VERSION "dbc-export 1 2026.26.6.5"

NS_ :

BS_:

BU_: APP BMS CC CMP CMPD CP DAS DI DIF DIR EPBL EPBR EVSE FC GTW HCML HCMR HVP ICR PCS PCS2 PM PMF PMR PTC SCCM SDCR TAS UMC V2G VC VCBATT VCBATT1 VCBATT2 VCFRONT VCFRONT1 VCLEFT VCRIGHT VCSEC

BO_ 994 VCLEFT_lightStatus: 7 VCLEFT
 SG_ VCLEFT_brakeLightStatus : 0|2@1+ (1,0) [0|2] "" Vector__XXX
 SG_ VCLEFT_tailLightStatus : 2|2@1+ (1,0) [0|2] "" Vector__XXX
 SG_ VCLEFT_turnSignalStatus : 4|2@1+ (1,0) [0|2] "" Vector__XXX
 SG_ VCLEFT_FLMapLightStatus : 6|2@1+ (1,0) [0|2] "" Vector__XXX
 SG_ VCLEFT_FRMapLightStatus : 8|2@1+ (1,0) [0|2] "" Vector__XXX
 SG_ VCLEFT_RLMapLightStatus : 10|2@1+ (1,0) [0|2] "" Vector__XXX
 SG_ VCLEFT_RRMapLightStatus : 12|2@1+ (1,0) [0|2] "" Vector__XXX
 SG_ VCLEFT_FLMapLightSwitchPressed : 14|1@1+ (1,0) [0|1] "" Vector__XXX
 SG_ VCLEFT_FRMapLightSwitchPressed : 15|1@1+ (1,0) [0|1] "" Vector__XXX
 SG_ VCLEFT_RLMapLightSwitchPressed : 16|1@1+ (1,0) [0|1] "" Vector__XXX
 SG_ VCLEFT_RRMapLightSwitchPressed : 17|1@1+ (1,0) [0|1] "" Vector__XXX
 SG_ VCLEFT_leftTurnTrailerLightStatu : 18|2@1+ (1,0) [0|2] "" Vector__XXX
 SG_ VCLEFT_rightTrnTrailerLightStatu : 20|2@1+ (1,0) [0|2] "" Vector__XXX
 SG_ VCLEFT_brakeTrailerLightStatus : 22|2@1+ (1,0) [0|2] "" Vector__XXX
 SG_ VCLEFT_tailTrailerLightStatus : 24|2@1+ (1,0) [0|2] "" Vector__XXX
 SG_ VCLEFT_fogTrailerLightStatus : 26|2@1+ (1,0) [0|2] "" Vector__XXX
 SG_ VCLEFT_frontRideHeight : 28|8@1- (1,0) [-127|127] "mm" Vector__XXX
 SG_ VCLEFT_rearRideHeight : 36|8@1- (1,0) [-127|127] "mm" Vector__XXX
 SG_ VCLEFT_trailerDetected : 46|2@1+ (1,0) [1|3] "" Vector__XXX
 SG_ VCLEFT_rideHeightSensorFault : 48|1@1+ (1,0) [0|1] "" Vector__XXX
 SG_ VCLEFT_reverseTrailerLightStatus : 49|2@1+ (1,0) [0|2] "" Vector__XXX
 SG_ VCLEFT_tailLightOutageStatus : 51|1@1+ (1,0) [0|1] "" Vector__XXX
 SG_ VCLEFT_reverseLightStatus : 52|2@1+ (1,0) [0|2] "" Vector__XXX
 SG_ VCLEFT_thirdRowLeftMapLightSwitc : 54|1@1+ (1,0) [0|1] "" Vector__XXX
 SG_ VCLEFT_thirdRowRightMapLightSwit : 55|1@1+ (1,0) [0|1] "" Vector__XXX

BO_ 1802 VCLEFT_logging0point1Hz: 8 VCLEFT
 SG_ VCLEFT_logging0point1HzIndex M : 0|1@1+ (1,0) [0|1] "" Vector__XXX
 SG_ VCLEFT_leftBrakeTailLightCurrent m0 : 2|9@1+ (0.005,0) [0|2.55] "A" Vector__XXX
 SG_ VCLEFT_leftBrakeTailLightCu_0001 m0 : 11|3@1+ (1,0) [1|7] "" Vector__XXX
 SG_ VCLEFT_leftRearTurnLightCurrent m0 : 14|9@1+ (0.002,0) [0|1.02] "A" Vector__XXX
 SG_ VCLEFT_leftRearTurnLightCurrentS m0 : 24|3@1+ (1,0) [1|7] "" Vector__XXX
 SG_ VCLEFT_canAuthResyncDurationMs m0 : 48|16@1+ (1,0) [0|65535] "" Vector__XXX

BO_ 936 VCLEFT_logging1Hz: 8 VCLEFT
 SG_ VCLEFT_logging1HzIndex M : 0|3@1+ (1,0) [0|7] "" Vector__XXX
 SG_ VCLEFT_tohcPCBATemperature m0 : 8|8@1+ (1,-40) [-40|214] "degC" Vector__XXX
 SG_ VCLEFT_phoneChargingFL m0 : 16|1@1+ (1,0) [0|1] "" Vector__XXX
 SG_ VCLEFT_phoneChargingFR m0 : 17|1@1+ (1,0) [0|1] "" Vector__XXX
 SG_ VCLEFT_swcResistance m0 : 24|7@1+ (0.025,0) [0|3.15] "Ohm" Vector__XXX
 SG_ VCLEFT_frontSeatHeatCushionPwr m0 : 32|7@1+ (1,0) [0|127] "W" Vector__XXX
 SG_ VCLEFT_frontSeatHeatBackrestPwr m0 : 40|7@1+ (1,0) [0|127] "W" Vector__XXX
 SG_ VCLEFT_rgbLedIPFLCurrent m3 : 3|10@1+ (0.000488758552819,0) [0|0.499999999534] "A" Vector__XXX
 SG_ VCLEFT_rgbLedIPFRCurrent m3 : 13|10@1+ (0.000488758552819,0) [0|0.499999999534] "A" Vector__XXX
 SG_ VCLEFT_rgbLedIPFLOutput m3 : 23|1@1+ (1,0) [0|1] "" Vector__XXX
 SG_ VCLEFT_rgbLedIPFROutput m3 : 24|1@1+ (1,0) [0|1] "" Vector__XXX
 SG_ VCLEFT_rgbLedFrontCurrent m3 : 25|10@1+ (0.000488758552819,0) [0|0.499999999534] "A" Vector__XXX
 SG_ VCLEFT_rgbLedRearCurrent m3 : 35|10@1+ (0.000488758552819,0) [0|0.499999999534] "A" Vector__XXX
 SG_ VCLEFT_rgbLedFrontOutput m3 : 45|1@1+ (1,0) [0|1] "" Vector__XXX
 SG_ VCLEFT_rgbLedRearOutput m3 : 46|1@1+ (1,0) [0|1] "" Vector__XXX
 SG_ VCLEFT_seat2RControllerCurrent m3 : 55|9@1+ (0.2,0) [0|102] "A" Vector__XXX

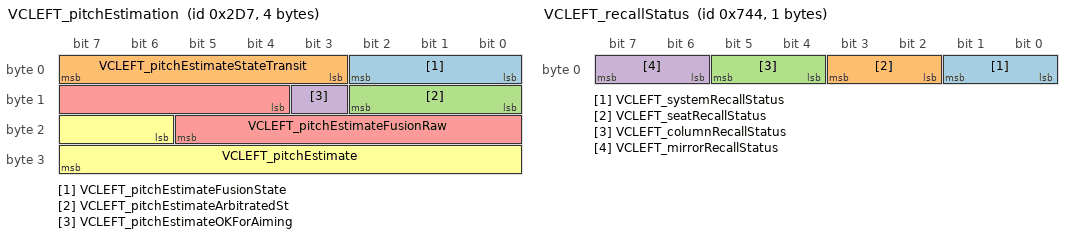
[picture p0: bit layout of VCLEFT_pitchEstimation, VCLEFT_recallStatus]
BO_ 727 VCLEFT_pitchEstimation: 4 VCLEFT
 SG_ VCLEFT_pitchEstimateFusionState : 0|3@1+ (1,0) [0|7] "" Vector__XXX
 SG_ VCLEFT_pitchEstimateStateTransit : 3|5@1+ (1,0) [0|31] "" Vector__XXX
 SG_ VCLEFT_pitchEstimateArbitratedSt : 8|3@1+ (1,0) [0|7] "" Vector__XXX
 SG_ VCLEFT_pitchEstimateOKForAiming : 11|1@1+ (1,0) [0|1] "" Vector__XXX
 SG_ VCLEFT_pitchEstimateFusionRaw : 12|10@1- (0.0002,0) [-0.1024|0.1022] "rad" Vector__XXX
 SG_ VCLEFT_pitchEstimate : 22|10@1- (0.0002,0) [-0.1022|0.1022] "rad" Vector__XXX

BO_ 1860 VCLEFT_recallStatus: 1 VCLEFT
 SG_ VCLEFT_systemRecallStatus : 0|2@1+ (1,0) [1|3] "" Vector__XXX
 SG_ VCLEFT_seatRecallStatus : 2|2@1+ (1,0) [1|3] "" Vector__XXX
 SG_ VCLEFT_columnRecallStatus : 4|2@1+ (1,0) [1|3] "" Vector__XXX
 SG_ VCLEFT_mirrorRecallStatus : 6|2@1+ (1,0) [1|3] "" Vector__XXX

BO_ 1250 VCLEFT_seatStatus: 8 VCLEFT
 SG_ VCLEFT_seatStatusIndex M : 0|3@1+ (1,0) [0|7] "" Vector__XXX
 SG_ VC_AH_1RowLeftSeatMovementHealth m0 : 5|3@1+ (1,0) [0|7] "" Vector__XXX
 SG_ VCLEFT_frontSeatTrackPos m0 : 8|16@1- (1,0) [-32768|32767] "" Vector__XXX
 SG_ VCLEFT_frontSeatTrackCurrent m0 : 24|12@1- (0.01,0) [-20.48|20.47] "A" Vector__XXX
 SG_ VCLEFT_frontSeatTrackDuty m0 : 36|12@1- (0.1,0) [-204.8|204.7] "%" Vector__XXX
 SG_ VCLEFT_frontSeatTrackState m0 : 48|3@1+ (1,0) [0|7] "" Vector__XXX
 SG_ VCLEFT_frontSeatTrackCalibrated m0 : 51|1@1+ (1,0) [0|1] "" Vector__XXX
 SG_ VCLEFT_frontSeatTrackLog m0 : 52|1@1+ (1,0) [0|1] "" Vector__XXX
 SG_ VCLEFT_frontSeatTrackBridgeSt m0 : 53|2@1+ (1,0) [0|3] "" Vector__XXX
 SG_ VCLEFT_frontSeatTrackPercentage m0 : 55|7@1+ (1,0) [0|100] "%" Vector__XXX
 SG_ VCLEFT_frontSeatBackPos m1 : 8|16@1- (1,0) [-32768|32767] "" Vector__XXX
 SG_ VCLEFT_frontSeatBackCurrent m1 : 24|12@1- (0.01,0) [-20.48|20.47] "A" Vector__XXX
 SG_ VCLEFT_frontSeatBackDuty m1 : 36|12@1- (0.1,0) [-204.8|204.7] "%" Vector__XXX
 SG_ VCLEFT_frontSeatBackState m1 : 48|3@1+ (1,0) [0|7] "" Vector__XXX
 SG_ VCLEFT_frontSeatBackCalibrated m1 : 51|1@1+ (1,0) [0|1] "" Vector__XXX
 SG_ VCLEFT_frontSeatBackLog m1 : 52|1@1+ (1,0) [0|1] "" Vector__XXX
 SG_ VCLEFT_frontSeatBackBridgeSt m1 : 53|2@1+ (1,0) [0|3] "" Vector__XXX
 SG_ VCLEFT_frontSeatBackPercentage m1 : 55|7@1+ (1,0) [0|100] "%" Vector__XXX
 SG_ VCLEFT_frontSeatLiftPos m2 : 8|16@1- (1,0) [-32768|32767] "" Vector__XXX
 SG_ VCLEFT_frontSeatLiftCurrent m2 : 24|12@1- (0.01,0) [-20.48|20.47] "A" Vector__XXX
 SG_ VCLEFT_frontSeatLiftDuty m2 : 36|12@1- (0.1,0) [-204.8|204.7] "%" Vector__XXX
 SG_ VCLEFT_frontSeatLiftState m2 : 48|3@1+ (1,0) [0|7] "" Vector__XXX
 SG_ VCLEFT_frontSeatLiftCalibrated m2 : 51|1@1+ (1,0) [0|1] "" Vector__XXX
 SG_ VCLEFT_frontSeatLiftLog m2 : 52|1@1+ (1,0) [0|1] "" Vector__XXX
 SG_ VCLEFT_frontSeatLiftBridgeSt m2 : 53|2@1+ (1,0) [0|3] "" Vector__XXX
 SG_ VCLEFT_frontSeatLiftPercentage m2 : 55|7@1+ (1,0) [0|100] "%" Vector__XXX
 SG_ VCLEFT_frontSeatTiltPos m3 : 8|16@1- (1,0) [-32768|32767] "" Vector__XXX
 SG_ VCLEFT_frontSeatTiltCurrent m3 : 24|12@1- (0.01,0) [-20.48|20.47] "A" Vector__XXX
 SG_ VCLEFT_frontSeatTiltDuty m3 : 36|12@1- (0.1,0) [-204.8|204.7] "%" Vector__XXX
 SG_ VCLEFT_frontSeatTiltState m3 : 48|3@1+ (1,0) [0|7] "" Vector__XXX
 SG_ VCLEFT_frontSeatTiltCalibrated m3 : 51|1@1+ (1,0) [0|1] "" Vector__XXX
 SG_ VCLEFT_frontSeatTiltLog m3 : 52|1@1+ (1,0) [0|1] "" Vector__XXX
 SG_ VCLEFT_frontSeatTiltBridgeSt m3 : 53|2@1+ (1,0) [0|3] "" Vector__XXX
 SG_ VCLEFT_frontSeatTiltPercentage m3 : 55|7@1+ (1,0) [0|100] "%" Vector__XXX
 SG_ VCLEFT_lumbarAState m4 : 3|3@1+ (1,0) [0|7] "" Vector__XXX
 SG_ VCLEFT_lumbarBState m4 : 6|3@1+ (1,0) [0|7] "" Vector__XXX
 SG_ VCLEFT_lumbarAPressureHpa m4 : 9|12@1+ (1,0) [0|4095] "" Vector__XXX
 SG_ VCLEFT_lumbarAPressureHpaFilt m4 : 21|10@1+ (1,0) [0|1023] "" Vector__XXX
 SG_ VCLEFT_lumbarBPressureHpa m4 : 31|12@1+ (1,0) [0|4095] "" Vector__XXX
 SG_ VCLEFT_lumbarBPressureHpaFilt m4 : 43|10@1+ (1,0) [0|1023] "" Vector__XXX
 SG_ VCLEFT_lumbarActiveTooLongErr m4 : 53|1@1+ (1,0) [0|1] "" Vector__XXX
 SG_ VCLEFT_lumbarMaxPErr m4 : 54|1@1+ (1,0) [0|1] "" Vector__XXX
 SG_ VCLEFT_lumbarOvercurrentErr m4 : 55|1@1+ (1,0) [0|1] "" Vector__XXX
 SG_ VCLEFT_lumbarMaxOperatingPErr m4 : 56|1@1+ (1,0) [0|1] "" Vector__XXX
 SG_ VCLEFT_lumbarMinPErr m4 : 57|1@1+ (1,0) [0|1] "" Vector__XXX
 SG_ VCLEFT_lumbarGeneralErr m4 : 58|1@1+ (1,0) [0|1] "" Vector__XXX
 SG_ VCLEFT_lumbarDevMaxPumpPressA m4 : 59|1@1+ (1,0) [0|1] "" Vector__XXX
 SG_ VCLEFT_lumbarDevMaxPumpPressB m4 : 60|1@1+ (1,0) [0|1] "" Vector__XXX
 SG_ VCLEFT_frontSeatTrackPosReal m5 : 3|12@1- (1,0) [-2048|2047] "mm" Vector__XXX
 SG_ VCLEFT_frontSeatBackPosReal m5 : 16|12@1- (0.1,0) [-204.8|204.7] "deg" Vector__XXX
 SG_ VCLEFT_frontSeatLiftPosReal m5 : 28|12@1- (1,0) [-2048|2047] "mm" Vector__XXX
 SG_ VCLEFT_frontSeatTiltPosReal m5 : 40|12@1- (0.1,0) [-204.8|204.7] "deg" Vector__XXX
 SG_ VCLEFT_frontSeatThighSupportPosR m5 : 52|12@1- (1,0) [-2048|2047] "mm" Vector__XXX
 SG_ VCLEFT_frontSeatTrackPosOffset m6 : 3|12@1- (1,0) [-2048|2047] "mm" Vector__XXX
 SG_ VCLEFT_frontSeatBackPosOffset m6 : 16|12@1- (0.1,0) [-204.8|204.7] "deg" Vector__XXX
 SG_ VCLEFT_frontSeatLiftPosOffset m6 : 28|12@1- (1,0) [-2048|2047] "mm" Vector__XXX
 SG_ VCLEFT_frontSeatTiltPosOffset m6 : 40|12@1- (0.1,0) [-204.8|204.7] "deg" Vector__XXX
 SG_ VCLEFT_frontSeatThighSupportPosO m6 : 52|12@1- (1,0) [-2048|2047] "mm" Vector__XXX
 SG_ VCLEFT_lumbarAPressurePercentage m7 : 3|7@1+ (1,0) [0|100] "%" Vector__XXX
 SG_ VCLEFT_lumbarBPressurePercentage m7 : 10|7@1+ (1,0) [0|100] "%" Vector__XXX

BO_ 738 VCLEFT_seatStatus2: 8 VCLEFT
 SG_ VCLEFT_seatStatus2Index M : 0|4@1+ (1,0) [0|15] "" Vector__XXX
 SG_ VCLEFT_frontSeatHeatCurrent m0 : 4|12@1+ (0.01,0) [0|40.95] "A" Vector__XXX
 SG_ VCLEFT_frontSeatHeatDuty m0 : 16|8@1+ (1,0) [0|255] "%" Vector__XXX
 SG_ VCLEFT_frontSeatHeatTmp m0 : 24|12@1- (0.05,0) [-40|80] "degC" Vector__XXX
 SG_ VCLEFT_frontSeatHeatTmpTarget m0 : 36|8@1- (0.5,0) [0|60] "degC" Vector__XXX
 SG_ VCLEFT_frontSeatHeatInhibited m0 : 44|1@1+ (1,0) [0|1] "" Vector__XXX
 SG_ VCLEFT_frontSeatHeatPowered m0 : 45|1@1+ (1,0) [0|1] "" Vector__XXX
 SG_ VCLEFT_2RowSeatFoldLeftSwitch m0 : 46|2@1+ (1,0) [1|3] "" Vector__XXX
 SG_ VCLEFT_2RowSeatUnfoldLeftSwitch m0 : 48|2@1+ (1,0) [1|3] "" Vector__XXX
 SG_ VCLEFT_2RowSeatFoldRightSwitch m0 : 50|2@1+ (1,0) [1|3] "" Vector__XXX
 SG_ VCLEFT_2RowSeatUnfoldRightSwitch m0 : 52|2@1+ (1,0) [1|3] "" Vector__XXX
 SG_ VCLEFT_3RowSeatFoldLeftSwitch m0 : 54|2@1+ (1,0) [1|3] "" Vector__XXX
 SG_ VCLEFT_3RowSeatUnfoldLeftSwitch m0 : 56|2@1+ (1,0) [1|3] "" Vector__XXX
 SG_ VCLEFT_3RowSeatFoldRightSwitch m0 : 58|2@1+ (1,0) [1|3] "" Vector__XXX
 SG_ VCLEFT_3RowSeatUnfoldRightSwitch m0 : 60|2@1+ (1,0) [1|3] "" Vector__XXX
 SG_ VC_AH_1RowLeftSeatHeatVentHealth m0 : 62|2@1+ (1,0) [0|3] "" Vector__XXX
 SG_ VCLEFT_2RowSeatReclineState m11 : 4|4@1+ (1,0) [0|14] "" Vector__XXX
 SG_ VCLEFT_2RowSeatReclineDuty m11 : 8|8@1- (1,0) [-100|100] "%" Vector__XXX
 SG_ VCLEFT_2RowSeatReclineCurrent m11 : 16|12@1- (0.05,0) [-100|100] "A" Vector__XXX
 SG_ VCLEFT_2RowSeatReclineCalibrated m11 : 28|1@1+ (1,0) [0|1] "" Vector__XXX
 SG_ VCLEFT_2RowSeatReclinePositionRa m11 : 29|12@1- (1,0) [-2048|2047] "" Vector__XXX
 SG_ VCLEFT_2RowSeatReclineAngle m11 : 41|12@1- (0.1,0) [-204.8|204.7] "deg" Vector__XXX
 SG_ VCLEFT_2RowSeatReclineAbsPosSwit m11 : 53|2@1+ (1,0) [1|3] "" Vector__XXX
 SG_ VCLEFT_2RowSeatReclinePositionSt m12 : 4|3@1+ (1,0) [0|7] "" Vector__XXX
 SG_ VCLEFT_2RowSeatReclineAdjustment m12 : 7|1@1+ (1,0) [0|1] "" Vector__XXX
 SG_ VCLEFT_2RowSeatReclineFoldAllowe m12 : 8|1@1+ (1,0) [0|1] "" Vector__XXX
 SG_ VCLEFT_2RowSeatReclineUnfoldAllo m12 : 9|1@1+ (1,0) [0|1] "" Vector__XXX
 SG_ VCLEFT_2RowSeatReclineNextToggle m12 : 10|2@1+ (1,0) [0|3] "" Vector__XXX
 SG_ VCLEFT_2RowSeatReclineChoreoBloc m12 : 12|1@1+ (1,0) [0|1] "" Vector__XXX
 SG_ VCLEFT_2RowSeat1RClashAvoidanceB m12 : 13|3@1+ (1,0) [0|7] "" Vector__XXX
 SG_ VCLEFT_2RowSeat1RClashAvoidanceS m12 : 16|2@1+ (1,0) [0|3] "" Vector__XXX
 SG_ VCLEFT_2RowSeatReclineAbsPo_0001 m12 : 18|12@1- (0.1,0) [-204.8|204.7] "deg" Vector__XXX
 SG_ VC_AH_2RowLeftSeatMovementHealth m12 : 61|3@1+ (1,0) [0|7] "" Vector__XXX
 SG_ VCLEFT_3RowSeatReclineState m14 : 4|4@1+ (1,0) [0|14] "" Vector__XXX
 SG_ VCLEFT_3RowSeatReclineDuty m14 : 8|8@1- (1,0) [-100|100] "%" Vector__XXX
 SG_ VCLEFT_3RowSeatReclineCurrent m14 : 16|12@1- (0.05,0) [-100|100] "A" Vector__XXX
 SG_ VCLEFT_3RowSeatReclineCalibrated m14 : 28|1@1+ (1,0) [0|1] "" Vector__XXX
 SG_ VCLEFT_3RowSeatReclinePositionRa m14 : 29|12@1- (1,0) [-2048|2047] "" Vector__XXX
 SG_ VCLEFT_3RowSeatReclineAngle m14 : 41|12@1- (0.1,0) [-204.8|204.7] "deg" Vector__XXX
 SG_ VCLEFT_3RowSeatReclineNextToggle m14 : 53|2@1+ (1,0) [0|3] "" Vector__XXX
 SG_ VCLEFT_3RRightCushionHeatCurrent m15 : 4|12@1+ (0.01,0) [0|40.95] "A" Vector__XXX
 SG_ VCLEFT_3RRightCushionHeatDuty m15 : 16|8@1- (1,0) [-100|100] "%" Vector__XXX
 SG_ VCLEFT_3RRightCushionHeatTmp m15 : 24|12@1- (0.05,0) [-40|80] "degC" Vector__XXX
 SG_ VCLEFT_3RRightCushionHeatTmpTarg m15 : 36|8@1- (0.5,0) [0|60] "degC" Vector__XXX
 SG_ VCLEFT_3RRightCushionHeatInhibit m15 : 44|1@1+ (1,0) [0|1] "" Vector__XXX
 SG_ VCLEFT_3RowSeatReclinePositionSt m15 : 46|3@1+ (1,0) [0|7] "" Vector__XXX
 SG_ VCLEFT_3RowSeatReclineAdjustment m15 : 49|1@1+ (1,0) [0|1] "" Vector__XXX
 SG_ VCLEFT_3RowSeatReclineFoldAllowe m15 : 50|1@1+ (1,0) [0|1] "" Vector__XXX
 SG_ VCLEFT_3RowSeatReclineUnfoldAllo m15 : 51|1@1+ (1,0) [0|1] "" Vector__XXX
 SG_ VCLEFT_3RowSeatReclineChoreoBloc m15 : 52|1@1+ (1,0) [0|1] "" Vector__XXX
 SG_ VCLEFT_3RowSeatReclineAbsPosSwit m15 : 53|2@1+ (1,0) [1|3] "" Vector__XXX

BO_ 930 VCLEFT_status: 8 VCLEFT
 SG_ VCLEFT_statusIndex M : 0|2@1+ (1,0) [0|3] "" Vector__XXX
 SG_ VCLEFT_securityControllerEnable m0 : 5|1@1+ (1,0) [0|1] "" Vector__XXX
 SG_ VCLEFT_securityControllerVoltage m0 : 6|5@1+ (0.625,0) [0|19.375] "V" Vector__XXX
 SG_ VCLEFT_consoleDoorAssist m0 : 11|1@1+ (1,0) [0|1] "" Vector__XXX
 SG_ VCLEFT_OTAState m0 : 12|1@1+ (1,0) [0|1] "" Vector__XXX
 SG_ VCLEFT_5AVoltage m0 : 13|10@1+ (0.005443676,0) [0|5.568880548] "V" Vector__XXX
 SG_ VCLEFT_vbatProt m0 : 23|12@1+ (0.005443676,0) [0|22.29185322] "V" Vector__XXX
 SG_ VCLEFT_footwellLightCurrent m0 : 35|12@1- (0.1,0) [-204.8|204.7] "mA" Vector__XXX
 SG_ VCLEFT_swcInputVoltage m0 : 47|8@1+ (0.1,0) [0|25.4] "V" Vector__XXX
 SG_ VCLEFT_swcPCBATemperature m0 : 55|8@1- (1,68) [-59|195] "degC" Vector__XXX
 SG_ VCLEFT_obdEthernetActive m0 : 63|1@1+ (1,0) [0|1] "" Vector__XXX
 SG_ VCLEFT_rationalityAggregateCurre m1 : 12|8@1+ (0.5,0) [0|127.5] "A" Vector__XXX
 SG_ VCLEFT_LVBatteryTypeDBG m1 : 20|3@1+ (1,0) [0|7] "" Vector__XXX
 SG_ VCLEFT_DIeFuseFault m1 : 24|1@1+ (1,0) [0|1] "" Vector__XXX
 SG_ VCLEFT_eFuseMgmtVoltageMonitor m1 : 25|7@1+ (0.125,0) [0|15.875] "V" Vector__XXX
 SG_ VCLEFT_trailerAuxCurrent m1 : 32|12@1+ (0.025,0) [0|102.35] "A" Vector__XXX
 SG_ VCLEFT_swcHeatTmp m1 : 44|10@1+ (0.1,-35) [-35|65] "degC" Vector__XXX
 SG_ VCLEFT_swcHeatStatus m1 : 54|3@1+ (1,0) [1|7] "" Vector__XXX
 SG_ VCLEFT_swcHeatInhibited m1 : 57|1@1+ (1,0) [0|1] "" Vector__XXX
 SG_ VCLEFT_obdDeviceDetected m1 : 58|1@1+ (1,0) [0|1] "" Vector__XXX
 SG_ VCLEFT_pcbaTemperature m2 : 4|11@1+ (0.125,-40) [-40|150] "degC" Vector__XXX
 SG_ VCLEFT_swcHeatPwr m2 : 15|9@1+ (0.5,0) [0|254] "W" Vector__XXX
 SG_ VCLEFT_swcHeatDutyCycle m2 : 24|7@1+ (1,0) [0|100] "%" Vector__XXX
 SG_ VCLEFT_DIeFuseCurrent m2 : 31|6@1+ (0.1,0) [0|6.3] "A" Vector__XXX
 SG_ VCLEFT_SWCpresent m2 : 37|1@1+ (1,0) [0|1] "" Vector__XXX
 SG_ VCLEFT_autonomyBehaviorStatus m2 : 46|2@1+ (1,0) [0|3] "" Vector__XXX
 SG_ VCLEFT_thirdRowLeftMapLightStatu m2 : 48|2@1+ (1,0) [0|2] "" Vector__XXX
 SG_ VCLEFT_thirdRowRightMapLightStat m2 : 50|2@1+ (1,0) [0|2] "" Vector__XXX

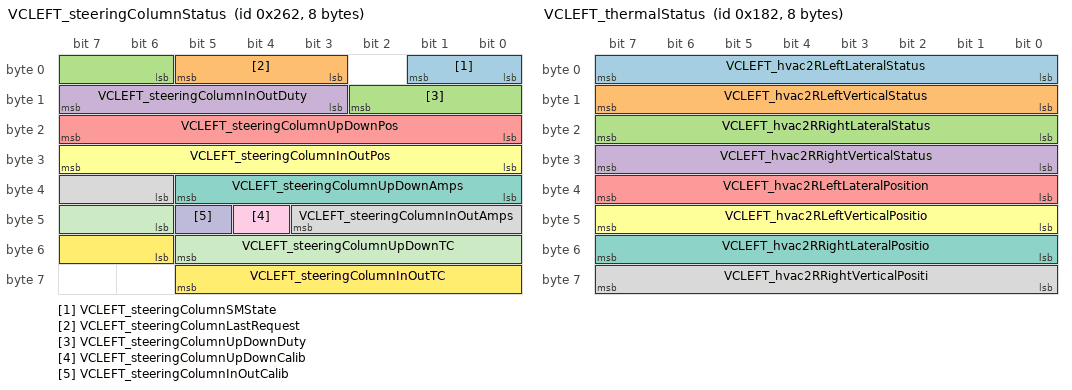
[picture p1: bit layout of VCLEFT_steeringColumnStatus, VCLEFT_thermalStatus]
BO_ 610 VCLEFT_steeringColumnStatus: 8 VCLEFT
 SG_ VCLEFT_steeringColumnSMState : 0|2@1+ (1,0) [1|3] "" Vector__XXX
 SG_ VCLEFT_steeringColumnLastRequest : 3|3@1+ (1,0) [1|7] "" Vector__XXX
 SG_ VCLEFT_steeringColumnUpDownDuty : 6|5@1- (7,0) [-100|100] "%" Vector__XXX
 SG_ VCLEFT_steeringColumnInOutDuty : 11|5@1- (7,0) [-100|100] "%" Vector__XXX
 SG_ VCLEFT_steeringColumnUpDownPos : 16|8@1- (1,103) [-25|230] "mm" Vector__XXX
 SG_ VCLEFT_steeringColumnInOutPos : 24|8@1- (1,103) [-25|230] "mm" Vector__XXX
 SG_ VCLEFT_steeringColumnUpDownAmps : 32|6@1- (0.63,0) [-20|19.53] "A" Vector__XXX
 SG_ VCLEFT_steeringColumnInOutAmps : 38|6@1- (0.63,0) [-20|19.53] "A" Vector__XXX
 SG_ VCLEFT_steeringColumnUpDownCalib : 44|1@1+ (1,0) [0|1] "" Vector__XXX
 SG_ VCLEFT_steeringColumnInOutCalib : 45|1@1+ (1,0) [0|1] "" Vector__XXX
 SG_ VCLEFT_steeringColumnUpDownTC : 46|8@1+ (0.5,-10) [-10|117.5] "s" Vector__XXX
 SG_ VCLEFT_steeringColumnInOutTC : 54|8@1+ (0.5,-10) [-10|117.5] "s" Vector__XXX

BO_ 962 VCLEFT_switchStatus: 8 VCLEFT
 SG_ VCLEFT_switchStatusIndex M : 0|1@1+ (1,0) [0|1] "" Vector__XXX
 SG_ VCLEFT_hornSwitchPressed m0 : 2|1@1+ (1,0) [0|1] "" Vector__XXX
 SG_ VCLEFT_hazardButtonPressed m0 : 3|1@1+ (1,0) [0|1] "" Vector__XXX
 SG_ VCLEFT_brakeSwitchPressed m0 : 4|1@1+ (1,0) [0|1] "" Vector__XXX
 SG_ VCLEFT_rightMirrorTilt m0 : 5|3@1+ (1,0) [0|7] "" Vector__XXX
 SG_ VCLEFT_frontSeatTrackBack m0 : 8|2@1+ (1,0) [1|3] "" Vector__XXX
 SG_ VCLEFT_frontSeatTrackForward m0 : 10|2@1+ (1,0) [1|3] "" Vector__XXX
 SG_ VCLEFT_frontSeatTiltDown m0 : 12|2@1+ (1,0) [1|3] "" Vector__XXX
 SG_ VCLEFT_frontSeatTiltUp m0 : 14|2@1+ (1,0) [1|3] "" Vector__XXX
 SG_ VCLEFT_frontSeatLiftDown m0 : 16|2@1+ (1,0) [1|3] "" Vector__XXX
 SG_ VCLEFT_frontSeatLiftUp m0 : 18|2@1+ (1,0) [1|3] "" Vector__XXX
 SG_ VCLEFT_frontSeatBackrestBack m0 : 20|2@1+ (1,0) [1|3] "" Vector__XXX
 SG_ VCLEFT_frontSeatBackrestForward m0 : 22|2@1+ (1,0) [1|3] "" Vector__XXX
 SG_ VCLEFT_frontSeatLumbarDown m0 : 24|2@1+ (1,0) [1|3] "" Vector__XXX
 SG_ VCLEFT_frontSeatLumbarUp m0 : 26|2@1+ (1,0) [1|3] "" Vector__XXX
 SG_ VCLEFT_frontSeatLumbarIn m0 : 28|2@1+ (1,0) [1|3] "" Vector__XXX
 SG_ VCLEFT_frontSeatLumbarOut m0 : 30|2@1+ (1,0) [1|3] "" Vector__XXX
 SG_ VCLEFT_btnWindowSwPackUpLF m0 : 32|1@1+ (1,0) [0|1] "" Vector__XXX
 SG_ VCLEFT_btnWindowSwPackAutoUpLF m0 : 33|1@1+ (1,0) [0|1] "" Vector__XXX
 SG_ VCLEFT_btnWindowSwPackDownLF m0 : 34|1@1+ (1,0) [0|1] "" Vector__XXX
 SG_ VCLEFT_btnWindowSwPackAutoDownLF m0 : 35|1@1+ (1,0) [0|1] "" Vector__XXX
 SG_ VCLEFT_btnWindowSwPackUpLR m0 : 36|1@1+ (1,0) [0|1] "" Vector__XXX
 SG_ VCLEFT_btnWindowSwPackAutoUpLR m0 : 37|1@1+ (1,0) [0|1] "" Vector__XXX
 SG_ VCLEFT_btnWindowSwPackDownLR m0 : 38|1@1+ (1,0) [0|1] "" Vector__XXX
 SG_ VCLEFT_btnWindowSwPackAutoDownLR m0 : 39|1@1+ (1,0) [0|1] "" Vector__XXX
 SG_ VCLEFT_btnWindowSwPackUpRF m0 : 40|1@1+ (1,0) [0|1] "" Vector__XXX
 SG_ VCLEFT_btnWindowSwPackAutoUpRF m0 : 41|1@1+ (1,0) [0|1] "" Vector__XXX
 SG_ VCLEFT_btnWindowSwPackDownRF m0 : 42|1@1+ (1,0) [0|1] "" Vector__XXX
 SG_ VCLEFT_btnWindowSwPackAutoDownRF m0 : 43|1@1+ (1,0) [0|1] "" Vector__XXX
 SG_ VCLEFT_btnWindowSwPackUpRR m0 : 44|1@1+ (1,0) [0|1] "" Vector__XXX
 SG_ VCLEFT_btnWindowSwPackAutoUpRR m0 : 45|1@1+ (1,0) [0|1] "" Vector__XXX
 SG_ VCLEFT_btnWindowSwPackDownRR m0 : 46|1@1+ (1,0) [0|1] "" Vector__XXX
 SG_ VCLEFT_btnWindowSwPackAutoDownRR m0 : 47|1@1+ (1,0) [0|1] "" Vector__XXX
 SG_ VCLEFT_frontBuckleSwitch m0 : 48|2@1+ (1,0) [1|3] "" Vector__XXX
 SG_ VCLEFT_frontOccupancySwitch m0 : 50|2@1+ (1,0) [1|3] "" Vector__XXX
 SG_ VCLEFT_rearLeftBuckleSwitch m0 : 52|2@1+ (1,0) [1|3] "" Vector__XXX
 SG_ VCLEFT_rearCenterOccupancySwitch m0 : 54|2@1+ (1,0) [1|3] "" Vector__XXX
 SG_ VCLEFT_rearLeftOccupancySwitch m0 : 56|2@1+ (1,0) [1|3] "" Vector__XXX
 SG_ VCLEFT_rearRightOccupancySwitch m0 : 58|2@1+ (1,0) [1|3] "" Vector__XXX
 SG_ VCLEFT_brakePressed m0 : 60|1@1+ (1,0) [0|1] "" Vector__XXX
 SG_ VCLEFT_rearHVACButtonPressed m0 : 61|1@1+ (1,0) [0|1] "" Vector__XXX
 SG_ VCLEFT_rearCenterBuckleSwitch m0 : 62|2@1+ (1,0) [1|3] "" Vector__XXX
 SG_ VCLEFT_isAlcoholInterlockSet m1 : 2|1@1+ (1,0) [0|1] "" Vector__XXX
 SG_ VCLEFT_swcLeftTiltRight m1 : 3|2@1+ (1,0) [1|3] "" Vector__XXX
 SG_ VCLEFT_swcLeftPressed m1 : 5|2@1+ (1,0) [1|3] "" Vector__XXX
 SG_ VCLEFT_swcRightTiltLeft m1 : 8|2@1+ (1,0) [1|3] "" Vector__XXX
 SG_ VCLEFT_swcRightTiltRight m1 : 10|2@1+ (1,0) [1|3] "" Vector__XXX
 SG_ VCLEFT_swcRightPressed m1 : 12|2@1+ (1,0) [1|3] "" Vector__XXX
 SG_ VCLEFT_swcLeftTiltLeft m1 : 14|2@1+ (1,0) [1|3] "" Vector__XXX
 SG_ VCLEFT_swcLeftScrollTicks m1 : 16|6@1- (1,0) [-32|31] "" Vector__XXX
 SG_ VCLEFT_swcWiperButtonState m1 : 22|2@1+ (1,0) [0|3] "" Vector__XXX
 SG_ VCLEFT_swcRightScrollTicks m1 : 24|6@1- (1,0) [-32|31] "" Vector__XXX
 SG_ VCLEFT_swcTurnSignalLeftButtonSt m1 : 30|2@1+ (1,0) [0|3] "" Vector__XXX
 SG_ VCLEFT_btnWindowUpLR m1 : 32|1@1+ (1,0) [0|1] "" Vector__XXX
 SG_ VCLEFT_btnWindowAutoUpLR m1 : 33|1@1+ (1,0) [0|1] "" Vector__XXX
 SG_ VCLEFT_btnWindowDownLR m1 : 34|1@1+ (1,0) [0|1] "" Vector__XXX
 SG_ VCLEFT_btnWindowAutoDownLR m1 : 35|1@1+ (1,0) [0|1] "" Vector__XXX
 SG_ VCLEFT_2RowSeatLeftFoldFlatSwitc m1 : 38|1@1+ (1,0) [0|1] "" Vector__XXX
 SG_ VCLEFT_2RowSeatRightFoldFlatSwit m1 : 39|1@1+ (1,0) [0|1] "" Vector__XXX
 SG_ VCLEFT_2RowSeatBothFoldFlatSwitc m1 : 40|1@1+ (1,0) [0|1] "" Vector__XXX
 SG_ VCLEFT_swcLeftDoublePress m1 : 41|1@1+ (1,0) [0|1] "" Vector__XXX
 SG_ VCLEFT_swcRightDoublePress m1 : 42|1@1+ (1,0) [0|1] "" Vector__XXX
 SG_ VCLEFT_swcTurnSignalRightButtonS m1 : 44|2@1+ (1,0) [0|3] "" Vector__XXX
 SG_ VCLEFT_swcHighBeamButtonState m1 : 46|2@1+ (1,0) [0|3] "" Vector__XXX
 SG_ VCLEFT_swcVoiceControlPress m1 : 48|2@1+ (1,0) [1|3] "" Vector__XXX
 SG_ VCLEFT_swcCameraButtonState m1 : 50|2@1+ (1,0) [0|3] "" Vector__XXX
 SG_ VCLEFT_swcRightPressedQF m1 : 52|1@1+ (1,0) [0|1] "" Vector__XXX
 SG_ VCLEFT_frontSeatResistiveOccupan m1 : 62|2@1+ (1,0) [1|3] "" Vector__XXX

BO_ 656 VCLEFT_thermalLogging10Hz: 8 VCLEFT
 SG_ VCLEFT_thermalLogging10HzIndex M : 0|3@1+ (1,0) [0|7] "" Vector__XXX
 SG_ VCLEFT_hvac2RLeftLateralVoltage m2 : 8|8@1+ (0.02,0) [0|5] "V" Vector__XXX
 SG_ VCLEFT_hvac2RLeftVerticalVoltage m2 : 16|8@1+ (0.02,0) [0|5] "V" Vector__XXX
 SG_ VCLEFT_hvac2RRightLateralVoltage m2 : 24|8@1+ (0.02,0) [0|5] "V" Vector__XXX
 SG_ VCLEFT_hvac2RRightVerticalVoltag m2 : 32|8@1+ (0.02,0) [0|5] "V" Vector__XXX
 SG_ VCLEFT_hvac2RLeftLateralCalibrat m2 : 40|1@1+ (1,0) [0|1] "" Vector__XXX
 SG_ VCLEFT_hvac2RLeftVerticalCalibra m2 : 41|1@1+ (1,0) [0|1] "" Vector__XXX
 SG_ VCLEFT_hvac2RRightLateralCalibra m2 : 42|1@1+ (1,0) [0|1] "" Vector__XXX
 SG_ VCLEFT_hvac2RRightVerticalCalibr m2 : 43|1@1+ (1,0) [0|1] "" Vector__XXX
 SG_ VCLEFT_hvac2RLeftLateralState m2 : 44|4@1+ (1,0) [0|15] "" Vector__XXX
 SG_ VCLEFT_hvac2RLeftVerticalState m2 : 48|4@1+ (1,0) [0|15] "" Vector__XXX
 SG_ VCLEFT_hvac2RRightLateralState m2 : 52|4@1+ (1,0) [0|15] "" Vector__XXX
 SG_ VCLEFT_hvac2RRightVerticalState m2 : 56|4@1+ (1,0) [0|15] "" Vector__XXX
 SG_ VCLEFT_hvacBlowerWindmillElecRpm m3 : 3|14@1+ (1,0) [0|16383] "RPM" Vector__XXX
 SG_ VCLEFT_hvac2RRightVerticalVeloci m3 : 17|8@1- (1,0) [-100|100] "deg/s" Vector__XXX
 SG_ VCLEFT_hvacBlowerWindmillBemf m3 : 25|14@1+ (4,0) [0|65532] "mV" Vector__XXX
 SG_ VCLEFT_hvac2RLeftVerticalVelocit m3 : 39|8@1- (1,0) [-100|100] "deg/s" Vector__XXX
 SG_ VCLEFT_hvac2RLeftLateralVelocity m3 : 47|8@1- (1,0) [-100|100] "deg/s" Vector__XXX
 SG_ VCLEFT_vcusbLinSchedule m3 : 55|2@1+ (1,0) [0|3] "" Vector__XXX
 SG_ VCLEFT_hvacBlowerArbState m3 : 57|3@1+ (1,0) [0|7] "" Vector__XXX
 SG_ VCLEFT_hvacBlowerArbResult m3 : 60|2@1+ (1,0) [0|3] "" Vector__XXX
 SG_ VCLEFT_hvac2RLeftLateralDuty m4 : 3|8@1- (1,0) [-100|100] "%" Vector__XXX
 SG_ VCLEFT_hvac2RLeftVerticalDuty m4 : 11|8@1- (1,0) [-100|100] "%" Vector__XXX
 SG_ VCLEFT_hvac2RRightLateralDuty m4 : 19|8@1- (1,0) [-100|100] "%" Vector__XXX
 SG_ VCLEFT_hvac2RRightVerticalDuty m4 : 27|8@1- (1,0) [-100|100] "%" Vector__XXX
 SG_ VCLEFT_hvacBlowerWindmilling m4 : 35|1@1+ (1,0) [0|1] "" Vector__XXX
 SG_ VCLEFT_hvac2RRightLateralVelocit m4 : 36|8@1- (1,0) [-100|100] "deg/s" Vector__XXX
 SG_ VCLEFT_hvacBlower1msOverrunFrequ m4 : 44|10@1+ (1,0) [0|1023] "" Vector__XXX
 SG_ VCLEFT_hvacBlower10msOverrunFreq m4 : 54|7@1+ (1,0) [0|127] "" Vector__XXX

BO_ 657 VCLEFT_thermalLogging1Hz: 7 VCLEFT
 SG_ VCLEFT_thermalLogging1HzIndex M : 0|4@1+ (1,0) [0|15] "" Vector__XXX
 SG_ VCLEFT_hvac2RLeftLateralZeroStop m0 : 8|8@1+ (0.02,0) [0|5] "V" Vector__XXX
 SG_ VCLEFT_hvac2RLeftVerticalZeroSto m0 : 16|8@1+ (0.02,0) [0|5] "V" Vector__XXX
 SG_ VCLEFT_hvac2RRightLateralZeroSto m0 : 24|8@1+ (0.02,0) [0|5] "V" Vector__XXX
 SG_ VCLEFT_hvac2RRightVerticalZeroSt m0 : 32|8@1+ (0.02,0) [0|5] "V" Vector__XXX
 SG_ VCLEFT_hvac2RLeftLateralEndStopV m1 : 8|8@1+ (0.02,0) [0|5] "V" Vector__XXX
 SG_ VCLEFT_hvac2RLeftVerticalEndStop m1 : 16|8@1+ (0.02,0) [0|5] "V" Vector__XXX
 SG_ VCLEFT_hvac2RRightLateralEndStop m1 : 24|8@1+ (0.02,0) [0|5] "V" Vector__XXX
 SG_ VCLEFT_hvac2RRightVerticalEndSto m1 : 32|8@1+ (0.02,0) [0|5] "V" Vector__XXX
 SG_ VCLEFT_hvacBlowerArbCurrent m1 : 40|8@1+ (0.1,0) [0|25.5] "A" Vector__XXX
 SG_ VCLEFT_hvacBlowerTorqueIndexFilt m1 : 48|7@1+ (1,0) [0|127] "%" Vector__XXX

BO_ 386 VCLEFT_thermalStatus: 8 VCLEFT
 SG_ VCLEFT_hvac2RLeftLateralStatus : 0|8@1+ (1,0) [0|255] "" Vector__XXX
 SG_ VCLEFT_hvac2RLeftVerticalStatus : 8|8@1+ (1,0) [0|255] "" Vector__XXX
 SG_ VCLEFT_hvac2RRightLateralStatus : 16|8@1+ (1,0) [0|255] "" Vector__XXX
 SG_ VCLEFT_hvac2RRightVerticalStatus : 24|8@1+ (1,0) [0|255] "" Vector__XXX
 SG_ VCLEFT_hvac2RLeftLateralPosition : 32|8@1+ (0.4,0) [0|100] "%" Vector__XXX
 SG_ VCLEFT_hvac2RLeftVerticalPositio : 40|8@1+ (0.4,0) [0|100] "%" Vector__XXX
 SG_ VCLEFT_hvac2RRightLateralPositio : 48|8@1+ (0.4,0) [0|100] "%" Vector__XXX
 SG_ VCLEFT_hvac2RRightVerticalPositi : 56|8@1+ (0.4,0) [0|100] "%" Vector__XXX

BO_ 706 VCLEFT_windowStatus: 8 VCLEFT
 SG_ VCLEFT_windowStatusIndex M : 0|1@1+ (1,0) [0|1] "" Vector__XXX
 SG_ VCLEFT_windowStateLF m0 : 1|4@1+ (1,0) [0|15] "" Vector__XXX
 SG_ VCLEFT_windowTrimClearMoveReques m0 : 5|2@1+ (1,0) [0|3] "" Vector__XXX
 SG_ VCLEFT_windowDutyLF m0 : 8|6@1- (5,0) [-100|100] "%" Vector__XXX
 SG_ VCLEFT_windowTrimClearActiveRequ m0 : 14|2@1+ (1,0) [1|3] "" Vector__XXX
 SG_ VCLEFT_windowCurrentLF m0 : 16|6@1- (0.5,0) [-15|15] "A" Vector__XXX
 SG_ VCLEFT_windowPositionLF m0 : 22|9@1- (1.25,265) [-50|580] "mm" Vector__XXX
 SG_ VCLEFT_windowCalibratedLF m0 : 32|1@1+ (1,0) [0|1] "" Vector__XXX
 SG_ VCLEFT_windowStateLR m0 : 33|4@1+ (1,0) [0|15] "" Vector__XXX
 SG_ VCLEFT_windowDutyLR m0 : 40|6@1- (5,0) [-100|100] "%" Vector__XXX
 SG_ VCLEFT_windowCurrentLR m0 : 48|6@1- (0.5,0) [-15|15] "A" Vector__XXX
 SG_ VCLEFT_windowPositionLR m0 : 54|9@1- (1.25,265) [-50|580] "mm" Vector__XXX
 SG_ VCLEFT_windowCalibratedLR m0 : 63|1@1+ (1,0) [0|1] "" Vector__XXX
 SG_ VCLEFT_windowThermalTCLF m1 : 1|8@1+ (1,0) [0|255] "s" Vector__XXX
 SG_ VCLEFT_windowThermalModeLF m1 : 9|2@1+ (1,0) [1|3] "" Vector__XXX
 SG_ VCLEFT_windowStopReasonLF m1 : 11|3@1+ (1,0) [0|7] "" Vector__XXX
 SG_ VCLEFT_windowStopReqReasonLF m1 : 14|4@1+ (1,0) [0|15] "" Vector__XXX
 SG_ VCLEFT_windowThermalTCLR m1 : 18|8@1+ (1,0) [0|255] "s" Vector__XXX
 SG_ VCLEFT_windowThermalModeLR m1 : 26|2@1+ (1,0) [1|3] "" Vector__XXX
 SG_ VCLEFT_windowStopReasonLR m1 : 28|3@1+ (1,0) [0|7] "" Vector__XXX
 SG_ VCLEFT_windowStopReqReasonLR m1 : 31|4@1+ (1,0) [0|15] "" Vector__XXX
 SG_ VCLEFT_windowControlStateLF m1 : 35|2@1+ (1,0) [0|3] "" Vector__XXX
 SG_ VCLEFT_windowCtrlUnavailableLF m1 : 38|3@1+ (1,0) [0|7] "" Vector__XXX
 SG_ VCLEFT_windowControlStateLR m1 : 42|2@1+ (1,0) [0|3] "" Vector__XXX
 SG_ VCLEFT_windowCtrlUnavailableLR m1 : 45|3@1+ (1,0) [0|7] "" Vector__XXX
 SG_ VCLEFT_windowPositionStateLF m1 : 49|3@1+ (1,0) [0|7] "" Vector__XXX
 SG_ VCLEFT_windowPositionStateLR m1 : 52|3@1+ (1,0) [0|7] "" Vector__XXX
 SG_ VCLEFT_windowVehGearStateLF m1 : 56|2@1+ (1,0) [1|3] "" Vector__XXX
 SG_ VCLEFT_windowVehGearStateLR m1 : 58|2@1+ (1,0) [1|3] "" Vector__XXX
 SG_ VCLEFT_windowSpeedTableStatusLF m1 : 60|2@1+ (1,0) [1|3] "" Vector__XXX
 SG_ VCLEFT_windowSpeedTableStatusLR m1 : 62|2@1+ (1,0) [1|3] "" Vector__XXX

BO_ 549 VCRIGHT_LVPowerState: 4 VCRIGHT
 SG_ VCRIGHT_ptcLVState : 0|2@1+ (1,0) [0|3] "" Vector__XXX
 SG_ VCRIGHT_ocsLVState : 2|2@1+ (1,0) [0|3] "" Vector__XXX
 SG_ VCRIGHT_premAudioLVState : 4|2@1+ (1,0) [0|3] "" Vector__XXX
 SG_ VCRIGHT_rearOilPumpLVState : 6|2@1+ (1,0) [0|3] "" Vector__XXX
 SG_ VCRIGHT_tunerLVState : 8|2@1+ (1,0) [0|3] "" Vector__XXX
 SG_ VCRIGHT_hvcLVState : 10|2@1+ (1,0) [0|3] "" Vector__XXX
 SG_ VCRIGHT_rcmLVState : 12|2@1+ (1,0) [0|3] "" Vector__XXX
 SG_ VCRIGHT_lumbarLVState : 14|2@1+ (1,0) [0|3] "" Vector__XXX
 SG_ VCRIGHT_3RUSBPowered : 16|1@1+ (1,0) [0|1] "" Vector__XXX
 SG_ VCRIGHT_cntctrPwrState : 17|1@1+ (1,0) [0|1] "" Vector__XXX
 SG_ VCRIGHT_eFuseLockoutStatus : 18|2@1+ (1,0) [0|3] "" Vector__XXX
 SG_ VCRIGHT_swEnStatus : 20|1@1+ (1,0) [0|1] "" Vector__XXX
 SG_ VCRIGHT_vehiclePowerStateDBG : 21|2@1+ (1,0) [0|3] "" Vector__XXX
 SG_ VCRIGHT_parkLVState : 23|2@1+ (1,0) [0|3] "" Vector__XXX
 SG_ VCRIGHT_icrLVState : 25|2@1+ (1,0) [0|3] "" Vector__XXX
 SG_ VCRIGHT_interiorCameraLedLVState : 27|2@1+ (1,0) [0|3] "" Vector__XXX
 SG_ VCRIGHT_diLVState : 29|2@1+ (1,0) [0|3] "" Vector__XXX
 SG_ VCRIGHT_accDevicesDetected : 31|1@1+ (1,0) [0|1] "" Vector__XXX

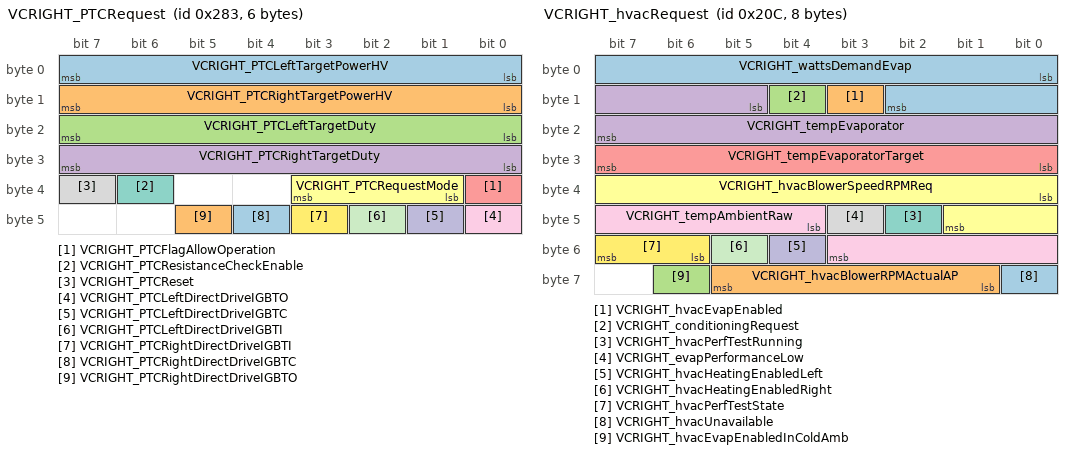
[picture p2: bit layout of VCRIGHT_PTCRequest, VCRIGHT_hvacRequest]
BO_ 643 VCRIGHT_PTCRequest: 6 VCRIGHT
 SG_ VCRIGHT_PTCLeftTargetPowerHV : 0|8@1+ (30,0) [0|7650] "W" Vector__XXX
 SG_ VCRIGHT_PTCRightTargetPowerHV : 8|8@1+ (30,0) [0|7650] "W" Vector__XXX
 SG_ VCRIGHT_PTCLeftTargetDuty : 16|8@1+ (0.5,0) [0|100] "%" Vector__XXX
 SG_ VCRIGHT_PTCRightTargetDuty : 24|8@1+ (0.5,0) [0|100] "%" Vector__XXX
 SG_ VCRIGHT_PTCFlagAllowOperation : 32|1@1+ (1,0) [0|1] "" Vector__XXX
 SG_ VCRIGHT_PTCRequestMode : 33|3@1+ (1,0) [0|7] "" Vector__XXX
 SG_ VCRIGHT_PTCResistanceCheckEnable : 38|1@1+ (1,0) [0|1] "" Vector__XXX
 SG_ VCRIGHT_PTCReset : 39|1@1+ (1,0) [0|1] "" Vector__XXX
 SG_ VCRIGHT_PTCLeftDirectDriveIGBTO : 40|1@1+ (1,0) [0|1] "" Vector__XXX
 SG_ VCRIGHT_PTCLeftDirectDriveIGBTC : 41|1@1+ (1,0) [0|1] "" Vector__XXX
 SG_ VCRIGHT_PTCLeftDirectDriveIGBTI : 42|1@1+ (1,0) [0|1] "" Vector__XXX
 SG_ VCRIGHT_PTCRightDirectDriveIGBTI : 43|1@1+ (1,0) [0|1] "" Vector__XXX
 SG_ VCRIGHT_PTCRightDirectDriveIGBTC : 44|1@1+ (1,0) [0|1] "" Vector__XXX
 SG_ VCRIGHT_PTCRightDirectDriveIGBTO : 45|1@1+ (1,0) [0|1] "" Vector__XXX

BO_ 1795 VCRIGHT_debugThermal10Hz: 8 VCRIGHT
 SG_ VCRIGHT_debugThermal10HzIndex M : 0|4@1+ (1,0) [0|15] "" Vector__XXX
 SG_ VCRIGHT_hvacPanelFloorSplitRow1 m2 : 8|8@1+ (0.4,0) [0|100] "%" Vector__XXX
 SG_ VCRIGHT_hvacDefrostPercent m2 : 16|8@1+ (0.4,0) [0|100] "%" Vector__XXX
 SG_ VCRIGHT_hvacRow2Percent m2 : 24|8@1+ (0.4,0) [0|100] "%" Vector__XXX
 SG_ VCRIGHT_hvacPanelFloorSplitRow2 m2 : 32|8@1+ (0.4,0) [0|100] "%" Vector__XXX
 SG_ VCRIGHT_hvacFreshMassCounter m2 : 40|12@1+ (10,0) [0|40000] "kg" Vector__XXX
 SG_ VCRIGHT_hvacRecircMassCounter m2 : 52|12@1+ (10,0) [0|40000] "kg" Vector__XXX
 SG_ VCRIGHT_setTempAdjustmentLeft m3 : 8|7@1+ (0.1,0) [0|12] "degC" Vector__XXX
 SG_ VCRIGHT_setTempAdjustmentRight m3 : 16|7@1+ (0.1,0) [0|12] "degC" Vector__XXX
 SG_ VCRIGHT_hvacLHVaneVelocity m3 : 24|8@1- (0.8,0) [-100|100] "deg/s" Vector__XXX
 SG_ VCRIGHT_hvacRHVaneVelocity m3 : 32|8@1- (0.8,0) [-100|100] "deg/s" Vector__XXX
 SG_ VCRIGHT_hvacVehicleSpeed m3 : 40|5@1+ (5,0) [0|150] "kph" Vector__XXX
 SG_ VCRIGHT_hvacMassflowCompensated m3 : 47|8@1+ (1.5,0) [0|250] "g/s" Vector__XXX
 SG_ VCRIGHT_PTCcenterPowerLeft m5 : 8|6@1+ (30,0) [0|1800] "W" Vector__XXX
 SG_ VCRIGHT_PTCouterPowerLeft m5 : 16|6@1+ (30,0) [0|1800] "W" Vector__XXX
 SG_ VCRIGHT_PTCinnerPowerLeft m5 : 24|6@1+ (30,0) [0|1800] "W" Vector__XXX
 SG_ VCRIGHT_PTCcenterPowerRight m5 : 32|6@1+ (30,0) [0|1800] "W" Vector__XXX
 SG_ VCRIGHT_PTCouterPowerRight m5 : 40|6@1+ (30,0) [0|1800] "W" Vector__XXX
 SG_ VCRIGHT_PTCinnerPowerRight m5 : 48|6@1+ (30,0) [0|1800] "W" Vector__XXX
 SG_ VCRIGHT_PTCcenterStoneTempLeft m6 : 8|8@1+ (2,-70) [-70|438] "degC" Vector__XXX
 SG_ VCRIGHT_PTCcenterStoneTempRight m6 : 16|8@1+ (2,-70) [-70|438] "degC" Vector__XXX
 SG_ VCRIGHT_PTCinnerStoneTempLeft m6 : 24|8@1+ (2,-70) [-70|438] "degC" Vector__XXX
 SG_ VCRIGHT_PTCinnerStoneTempRight m6 : 32|8@1+ (2,-70) [-70|438] "degC" Vector__XXX
 SG_ VCRIGHT_PTCouterStoneTempLeft m7 : 8|8@1+ (2,-70) [-70|438] "degC" Vector__XXX
 SG_ VCRIGHT_PTCouterRodTempLeft m7 : 16|8@1+ (2,-70) [-70|438] "degC" Vector__XXX
 SG_ VCRIGHT_PTCouterAirTempLeft m7 : 24|8@1+ (2,-70) [-70|438] "degC" Vector__XXX
 SG_ VCRIGHT_PTCcenterRodTempLeft m7 : 32|8@1+ (2,-70) [-70|438] "degC" Vector__XXX
 SG_ VCRIGHT_PTCinnerRodTempLeft m7 : 40|8@1+ (2,-70) [-70|438] "degC" Vector__XXX
 SG_ VCRIGHT_PTCcenterAirTempLeft m7 : 48|8@1+ (2,-70) [-70|438] "degC" Vector__XXX
 SG_ VCRIGHT_PTCinnerAirTempLeft m7 : 56|8@1+ (2,-70) [-70|438] "degC" Vector__XXX
 SG_ VCRIGHT_PTCouterStoneTempRight m8 : 8|8@1+ (2,-70) [-70|438] "degC" Vector__XXX
 SG_ VCRIGHT_PTCouterRodTempRight m8 : 16|8@1+ (2,-70) [-70|438] "degC" Vector__XXX
 SG_ VCRIGHT_PTCouterAirTempRight m8 : 24|8@1+ (2,-70) [-70|438] "degC" Vector__XXX
 SG_ VCRIGHT_PTCcenterRodTempRight m8 : 32|8@1+ (2,-70) [-70|438] "degC" Vector__XXX
 SG_ VCRIGHT_PTCinnerRodTempRight m8 : 40|8@1+ (2,-70) [-70|438] "degC" Vector__XXX
 SG_ VCRIGHT_PTCcenterAirTempRight m8 : 48|8@1+ (2,-70) [-70|438] "degC" Vector__XXX
 SG_ VCRIGHT_PTCinnerAirTempRight m8 : 56|8@1+ (2,-70) [-70|438] "degC" Vector__XXX

BO_ 291 VCRIGHT_doorStatus2: 8 VCRIGHT
 SG_ VCRIGHT_doorStatus2Index M : 0|1@1+ (1,0) [0|1] "" Vector__XXX
 SG_ VCRIGHT_frontLatchRelDuty m1 : 8|8@1+ (1,0) [0|255] "%" Vector__XXX
 SG_ VCRIGHT_BPillarCameraHeaterState m1 : 16|3@1+ (1,0) [1|7] "" Vector__XXX
 SG_ VCRIGHT_doorLatchAjarSwitchVolta m1 : 24|8@1+ (0.02,0) [0|5] "V" Vector__XXX
 SG_ VCRIGHT_doorLatchAjarSwitch_0001 m1 : 32|8@1+ (0.02,0) [0|5] "V" Vector__XXX
 SG_ VCRIGHT_BPillarCameraHeaterCurre m1 : 40|6@1+ (0.02,0) [0|1.24] "A" Vector__XXX
 SG_ VCRIGHT_mirrorTiltXOffset m1 : 48|8@1- (0.02,0) [-2.5|2.5] "V" Vector__XXX
 SG_ VCRIGHT_mirrorTiltYOffset m1 : 56|8@1- (0.02,0) [-2.5|2.5] "V" Vector__XXX

BO_ 915 VCRIGHT_epbmDebug: 8 VCRIGHT
 SG_ VCRIGHT_epbmDebugIndex M : 0|1@1+ (1,0) [0|1] "" Vector__XXX
 SG_ VCRIGHT_epbmCaliperState m0 : 1|3@1+ (1,0) [0|7] "" Vector__XXX
 SG_ VCRIGHT_epbmMotorEnabled m0 : 4|1@1+ (1,0) [0|1] "" Vector__XXX
 SG_ VCRIGHT_epbMotorCurrent m0 : 5|11@1+ (0.01,0) [0|20.47] "A" Vector__XXX
 SG_ VCRIGHT_epbmApplyVoltage m0 : 16|11@1+ (0.01,0) [0|20.47] "A" Vector__XXX
 SG_ VCRIGHT_epbmReleaseVoltage m0 : 27|11@1+ (0.01,0) [0|20.47] "A" Vector__XXX
 SG_ VCRIGHT_summonFaultReason m0 : 38|5@1+ (1,0) [0|31] "" Vector__XXX
 SG_ VCRIGHT_epbSummonState m0 : 43|3@1+ (1,0) [0|7] "" Vector__XXX
 SG_ VCRIGHT_epbmSummonState m0 : 46|3@1+ (1,0) [0|7] "" Vector__XXX
 SG_ VCRIGHT_epbUnitStatus m0 : 49|5@1+ (1,0) [0|31] "" Vector__XXX
 SG_ VCRIGHT_epbmFaultStatus m0 : 54|2@1+ (1,0) [0|3] "" Vector__XXX
 SG_ VCRIGHT_epbFaultStatus m0 : 56|2@1+ (1,0) [0|3] "" Vector__XXX
 SG_ VCRIGHT_epbmSystemStatus m0 : 58|4@1+ (1,0) [0|15] "" Vector__XXX
 SG_ VCRIGHT_epbmAutonomyBehavior m0 : 62|2@1+ (1,0) [0|3] "" Vector__XXX

BO_ 524 VCRIGHT_hvacRequest: 8 VCRIGHT
 SG_ VCRIGHT_wattsDemandEvap : 0|11@1+ (5,0) [0|10000] "W" Vector__XXX
 SG_ VCRIGHT_hvacEvapEnabled : 11|1@1+ (1,0) [0|1] "" Vector__XXX
 SG_ VCRIGHT_conditioningRequest : 12|1@1+ (1,0) [0|1] "" Vector__XXX
 SG_ VCRIGHT_tempEvaporator : 13|11@1+ (0.1,-40) [-40|105] "degC" Vector__XXX
 SG_ VCRIGHT_tempEvaporatorTarget : 24|8@1+ (0.2,0) [0|50] "degC" Vector__XXX
 SG_ VCRIGHT_hvacBlowerSpeedRPMReq : 32|10@1+ (5,0) [0|5115] "RPM" Vector__XXX
 SG_ VCRIGHT_hvacPerfTestRunning : 42|1@1+ (1,0) [0|1] "" Vector__XXX
 SG_ VCRIGHT_evapPerformanceLow : 43|1@1+ (1,0) [0|1] "" Vector__XXX
 SG_ VCRIGHT_tempAmbientRaw : 44|8@1+ (0.5,-40) [-39.5|80] "degC" Vector__XXX
 SG_ VCRIGHT_hvacHeatingEnabledLeft : 52|1@1+ (1,0) [0|1] "" Vector__XXX
 SG_ VCRIGHT_hvacHeatingEnabledRight : 53|1@1+ (1,0) [0|1] "" Vector__XXX
 SG_ VCRIGHT_hvacPerfTestState : 54|2@1+ (1,0) [0|3] "" Vector__XXX
 SG_ VCRIGHT_hvacUnavailable : 56|1@1+ (1,0) [0|1] "" Vector__XXX
 SG_ VCRIGHT_hvacBlowerRPMActualAP : 57|5@1+ (200,0) [0|4200] "rpm" Vector__XXX
 SG_ VCRIGHT_hvacEvapEnabledInColdAmb : 62|1@1+ (1,0) [0|1] "" Vector__XXX

BO_TX_BU_ 994 : VCLEFT;
BO_TX_BU_ 1802 : VCLEFT;
BO_TX_BU_ 936 : VCLEFT;
BO_TX_BU_ 727 : VCLEFT;
BO_TX_BU_ 1860 : VCLEFT;
BO_TX_BU_ 1250 : VCLEFT;
BO_TX_BU_ 738 : VCLEFT;
BO_TX_BU_ 930 : VCLEFT;
BO_TX_BU_ 610 : VCLEFT;
BO_TX_BU_ 962 : VCLEFT;
BO_TX_BU_ 656 : VCLEFT;
BO_TX_BU_ 657 : VCLEFT;
BO_TX_BU_ 386 : VCLEFT;
BO_TX_BU_ 706 : VCLEFT;
BO_TX_BU_ 549 : VCRIGHT;
BO_TX_BU_ 643 : VCRIGHT;
BO_TX_BU_ 1795 : VCRIGHT;
BO_TX_BU_ 291 : VCRIGHT;
BO_TX_BU_ 915 : VCRIGHT;
BO_TX_BU_ 524 : VCRIGHT;
CM_ BO_ 994 "Left body controller message: light status";
CM_ SG_ 994 VCLEFT_brakeLightStatus "Status of rear left brake light source; raw 3 = signal not available (SNA)";
CM_ SG_ 994 VCLEFT_tailLightStatus "Status of left tail (rear position) light source; raw 3 = signal not available (SNA)";
CM_ SG_ 994 VCLEFT_turnSignalStatus "Status of rear left turn signal light source; raw 3 = signal not available (SNA)";
CM_ SG_ 994 VCLEFT_FLMapLightStatus "Status of front left overhead map light; raw 3 = signal not available (SNA)";
CM_ SG_ 994 VCLEFT_FRMapLightStatus "Status of front right overhead map light; raw 3 = signal not available (SNA)";
CM_ SG_ 994 VCLEFT_RLMapLightStatus "Status of rear left overhead map light; raw 3 = signal not available (SNA)";
CM_ SG_ 994 VCLEFT_RRMapLightStatus "Status of rear right overhead map light; raw 3 = signal not available (SNA)";
CM_ SG_ 994 VCLEFT_FLMapLightSwitchPressed "Status of front left overhead map light switch";
CM_ SG_ 994 VCLEFT_FRMapLightSwitchPressed "Status of front right overhead map light switch";
CM_ SG_ 994 VCLEFT_RLMapLightSwitchPressed "Status of rear left overhead map light switch";
CM_ SG_ 994 VCLEFT_RRMapLightSwitchPressed "Status of rear right overhead map light switch";
CM_ SG_ 994 VCLEFT_leftTurnTrailerLightStatu "The desired on/off state of the trailer left turn light; raw 3 = signal not available (SNA)";
CM_ SG_ 994 VCLEFT_rightTrnTrailerLightStatu "The desired on/off state of the trailer right turn light; raw 3 = signal not available (SNA)";
CM_ SG_ 994 VCLEFT_brakeTrailerLightStatus "The desired on/off state of the trailer brake light; raw 3 = signal not available (SNA)";
CM_ SG_ 994 VCLEFT_tailTrailerLightStatus "The desired on/off state of the trailer tail light; raw 3 = signal not available (SNA)";
CM_ SG_ 994 VCLEFT_fogTrailerLightStatus "The desired on/off state of the trailer fog light.; raw 3 = signal not available (SNA)";
CM_ SG_ 994 VCLEFT_frontRideHeight "Left body controller: front ride height; raw 128 = signal not available (SNA)";
CM_ SG_ 994 VCLEFT_rearRideHeight "Left body controller: rear ride height; raw 128 = signal not available (SNA)";
CM_ SG_ 994 VCLEFT_trailerDetected "Trailer light detection status; raw 0 = signal not available (SNA)";
CM_ SG_ 994 VCLEFT_rideHeightSensorFault "Fault status of the front and rear ride height sensors";
CM_ SG_ 994 VCLEFT_reverseTrailerLightStatus "The desired on/off state of the trailer reverse light; raw 3 = signal not available (SNA)";
CM_ SG_ 994 VCLEFT_tailLightOutageStatus "Left body controller: tail light outage status";
CM_ SG_ 994 VCLEFT_reverseLightStatus "Status of left rear body side reverse light source; raw 3 = signal not available (SNA)";
CM_ SG_ 994 VCLEFT_thirdRowLeftMapLightSwitc "Reports the status of the third row left overhead map light switch";
CM_ SG_ 994 VCLEFT_thirdRowRightMapLightSwit "Reports the status of the third row right overhead map light switch";
CM_ BO_ 1802 "Left body controller message: logging0point1 hz";
CM_ SG_ 1802 VCLEFT_logging0point1HzIndex "Left body controller: logging0point1 hz index";
CM_ SG_ 1802 VCLEFT_leftBrakeTailLightCurrent "Current sensed by the left brake tail light HSD (high side driver).; raw 511 = signal not available (SNA)";
CM_ SG_ 1802 VCLEFT_leftBrakeTailLightCu_0001 "State representing validity of the left brake tail light HSD (high side driver) current sense.; raw 0 = signal not available (SNA)";
CM_ SG_ 1802 VCLEFT_leftRearTurnLightCurrent "Current sensed by the left rear turn signal HSD (high side driver).; raw 511 = signal not available (SNA)";
CM_ SG_ 1802 VCLEFT_leftRearTurnLightCurrentS "State representing validity of the left rear turn signal HSD (high side driver) current sense.; raw 0 = signal not available (SNA)";
CM_ SG_ 1802 VCLEFT_canAuthResyncDurationMs "Left body controller: can auth resync duration ms";
CM_ BO_ 936 "Left body controller message: logging1 hz";
CM_ SG_ 936 VCLEFT_logging1HzIndex "Left body controller: logging1 hz index";
CM_ SG_ 936 VCLEFT_tohcPCBATemperature "Left body controller: tohc PCBA temperature; raw 255 = signal not available (SNA)";
CM_ SG_ 936 VCLEFT_phoneChargingFL "Charging status of front left wireless phone charger (if installed)";
CM_ SG_ 936 VCLEFT_phoneChargingFR "Charging status of front right wireless phone charger (if installed)";
CM_ SG_ 936 VCLEFT_swcResistance "Left body controller: swc resistance; raw 127 = signal not available (SNA)";
CM_ SG_ 936 VCLEFT_frontSeatHeatCushionPwr "Left body controller: front seat heat cushion pwr";
CM_ SG_ 936 VCLEFT_frontSeatHeatBackrestPwr "Left body controller: front seat heat backrest pwr";
CM_ SG_ 936 VCLEFT_rgbLedIPFLCurrent "Current drawn by the IPFL RGB LED";
CM_ SG_ 936 VCLEFT_rgbLedIPFRCurrent "Current drawn by the IPFR RGB LED";
CM_ SG_ 936 VCLEFT_rgbLedIPFLOutput "The power state of the IPFL RGB LED";
CM_ SG_ 936 VCLEFT_rgbLedIPFROutput "The power state of the IPFR RGB LED";
CM_ SG_ 936 VCLEFT_rgbLedFrontCurrent "Current drawn by the front door RGB LED";
CM_ SG_ 936 VCLEFT_rgbLedRearCurrent "Current drawn by the rear door RGB LED";
CM_ SG_ 936 VCLEFT_rgbLedFrontOutput "The power state of the front door RGB LED";
CM_ SG_ 936 VCLEFT_rgbLedRearOutput "The power state of the rear door RGB LED";
CM_ SG_ 936 VCLEFT_seat2RControllerCurrent "Left body controller: seat2 r controller current";
CM_ BO_ 727 "Left body controller message: pitch estimation";
CM_ SG_ 727 VCLEFT_pitchEstimateFusionState "Left body controller: pitch estimate fusion state";
CM_ SG_ 727 VCLEFT_pitchEstimateStateTransit "Left body controller: pitch estimate state transition ID";
CM_ SG_ 727 VCLEFT_pitchEstimateArbitratedSt "Left body controller: pitch estimate arbitrated state";
CM_ SG_ 727 VCLEFT_pitchEstimateOKForAiming "Left body controller: pitch estimate OK for aiming";
CM_ SG_ 727 VCLEFT_pitchEstimateFusionRaw "Left body controller: pitch estimate fusion raw";
CM_ SG_ 727 VCLEFT_pitchEstimate "Left body controller: pitch estimate; raw 512 = signal not available (SNA)";
CM_ BO_ 1860 "Left body controller message: recall status";
CM_ SG_ 1860 VCLEFT_systemRecallStatus "Left body controller: system recall status; raw 0 = signal not available (SNA)";
CM_ SG_ 1860 VCLEFT_seatRecallStatus "Left body controller: seat recall status; raw 0 = signal not available (SNA)";
CM_ SG_ 1860 VCLEFT_columnRecallStatus "Left body controller: column recall status; raw 0 = signal not available (SNA)";
CM_ SG_ 1860 VCLEFT_mirrorRecallStatus "Recall status for the left side view mirror; raw 0 = signal not available (SNA)";
CM_ BO_ 1250 "Left body controller message: seat status";
CM_ SG_ 1250 VCLEFT_seatStatusIndex "Left body controller: seat status index";
CM_ SG_ 1250 VC_AH_1RowLeftSeatMovementHealth "Left body controller: AH 1 row left seat movement health";
CM_ SG_ 1250 VCLEFT_frontSeatTrackPos "communicates raw encoder count for driver seat track position";
CM_ SG_ 1250 VCLEFT_frontSeatTrackCurrent "Current drawn by front left seat track motor";
CM_ SG_ 1250 VCLEFT_frontSeatTrackDuty "Front left seat track motor duty cycle";
CM_ SG_ 1250 VCLEFT_frontSeatTrackState "State of front left seat track motor";
CM_ SG_ 1250 VCLEFT_frontSeatTrackCalibrated "Left body controller: front seat track calibrated";
CM_ SG_ 1250 VCLEFT_frontSeatTrackLog "Left body controller: front seat track log";
CM_ SG_ 1250 VCLEFT_frontSeatTrackBridgeSt "Bridge state";
CM_ SG_ 1250 VCLEFT_frontSeatTrackPercentage "Communicates position of front seat track as percentage of its total range";
CM_ SG_ 1250 VCLEFT_frontSeatBackPos "communicates raw encoder count for driver seat backrest position";
CM_ SG_ 1250 VCLEFT_frontSeatBackCurrent "Current drawn by front left seat backrest motor";
CM_ SG_ 1250 VCLEFT_frontSeatBackDuty "Front left seat backrest motor duty cycle";
CM_ SG_ 1250 VCLEFT_frontSeatBackState "Active state of front left seat backrest";
CM_ SG_ 1250 VCLEFT_frontSeatBackCalibrated "Left body controller: front seat back calibrated";
CM_ SG_ 1250 VCLEFT_frontSeatBackLog "Left body controller: front seat back log";
CM_ SG_ 1250 VCLEFT_frontSeatBackBridgeSt "Bridge state";
CM_ SG_ 1250 VCLEFT_frontSeatBackPercentage "Communicates position of front seat backrest recline as percentage of its total range";
CM_ SG_ 1250 VCLEFT_frontSeatLiftPos "communicates raw encoder count for driver seat lift position";
CM_ SG_ 1250 VCLEFT_frontSeatLiftCurrent "Current drawn by front left seat lift motor";
CM_ SG_ 1250 VCLEFT_frontSeatLiftDuty "Front left seat lift motor duty cycle";
CM_ SG_ 1250 VCLEFT_frontSeatLiftState "Status of front left seat motor";
CM_ SG_ 1250 VCLEFT_frontSeatLiftCalibrated "Left body controller: front seat lift calibrated";
CM_ SG_ 1250 VCLEFT_frontSeatLiftLog "Left body controller: front seat lift log";
CM_ SG_ 1250 VCLEFT_frontSeatLiftBridgeSt "Bridge state";
CM_ SG_ 1250 VCLEFT_frontSeatLiftPercentage "Communicates position of front seat lift as percentage of its total range";
CM_ SG_ 1250 VCLEFT_frontSeatTiltPos "communicates raw encoder count for driver seat tile position";
CM_ SG_ 1250 VCLEFT_frontSeatTiltCurrent "Current drawn by front left seat tilt motor";
CM_ SG_ 1250 VCLEFT_frontSeatTiltDuty "Front left seat tilt motor duty cycle";
CM_ SG_ 1250 VCLEFT_frontSeatTiltState "State of front left seat tilt motor";
CM_ SG_ 1250 VCLEFT_frontSeatTiltCalibrated "Left body controller: front seat tilt calibrated";
CM_ SG_ 1250 VCLEFT_frontSeatTiltLog "Left body controller: front seat tilt log";
CM_ SG_ 1250 VCLEFT_frontSeatTiltBridgeSt "Bridge state";
CM_ SG_ 1250 VCLEFT_frontSeatTiltPercentage "Communicates position of front seat tilt as percentage of its total range";
CM_ SG_ 1250 VCLEFT_lumbarAState "State of front left seat lumbar bladder A";
CM_ SG_ 1250 VCLEFT_lumbarBState "State of front left lumbar bladder B";
CM_ SG_ 1250 VCLEFT_lumbarAPressureHpa "Left body controller: lumbar a pressure hpa";
CM_ SG_ 1250 VCLEFT_lumbarAPressureHpaFilt "logs filtered pressure of left seat lumbar bladder A";
CM_ SG_ 1250 VCLEFT_lumbarBPressureHpa "Left body controller: lumbar b pressure hpa";
CM_ SG_ 1250 VCLEFT_lumbarBPressureHpaFilt "logs filtered pressure of left seat lumbar bladder B";
CM_ SG_ 1250 VCLEFT_lumbarActiveTooLongErr "Error reported by lumbar ECU: Valve activated too long";
CM_ SG_ 1250 VCLEFT_lumbarMaxPErr "Error reported by lumbar ECU: max bladder pressure reached";
CM_ SG_ 1250 VCLEFT_lumbarOvercurrentErr "Error reported by lumbar ECU: pump overcurrent";
CM_ SG_ 1250 VCLEFT_lumbarMaxOperatingPErr "Error reported by lumbar ECU: max bladder operating pressure reached";
CM_ SG_ 1250 VCLEFT_lumbarMinPErr "Error reported by lumbar ECU: min bladder pressure reached";
CM_ SG_ 1250 VCLEFT_lumbarGeneralErr "Error reported by lumbar ECU: general error";
CM_ SG_ 1250 VCLEFT_lumbarDevMaxPumpPressA "System has reached Tesla specified maximum pressure for lumbar bladder A";
CM_ SG_ 1250 VCLEFT_lumbarDevMaxPumpPressB "System has reached Tesla specified maximum pressure for lumbar bladder B";
CM_ SG_ 1250 VCLEFT_frontSeatTrackPosReal "communicates position of driver seat track in a physical unit";
CM_ SG_ 1250 VCLEFT_frontSeatBackPosReal "communicates position of driver seat backrest in degrees";
CM_ SG_ 1250 VCLEFT_frontSeatLiftPosReal "communicates position of driver seat lift in a physical unit";
CM_ SG_ 1250 VCLEFT_frontSeatTiltPosReal "communicates position of driver seat tilt in a physical unit";
CM_ SG_ 1250 VCLEFT_frontSeatThighSupportPosR "Position of front seat thigh support in a physical unit";
CM_ SG_ 1250 VCLEFT_frontSeatTrackPosOffset "Communicates post calibration position offset of front left seat track in a physical unit";
CM_ SG_ 1250 VCLEFT_frontSeatBackPosOffset "Communicates post calibration position offset of front left seat backrest in degrees";
CM_ SG_ 1250 VCLEFT_frontSeatLiftPosOffset "Communicates post calibration position offset of front left seat lift in a physical unit";
CM_ SG_ 1250 VCLEFT_frontSeatTiltPosOffset "Communicates post calibration position offset of front left seat tilt in a physical unit";
CM_ SG_ 1250 VCLEFT_frontSeatThighSupportPosO "Post calibration position offset of front seat thigh support in a physical unit";
CM_ SG_ 1250 VCLEFT_lumbarAPressurePercentage "Percentage of lumbar bladder A pressure relative to maximum pressure";
CM_ SG_ 1250 VCLEFT_lumbarBPressurePercentage "Percentage of lumbar bladder B pressure relative to maximum pressure";
CM_ BO_ 738 "Left body controller message: seat status2";
CM_ SG_ 738 VCLEFT_seatStatus2Index "Left body controller: seat status2 index";
CM_ SG_ 738 VCLEFT_frontSeatHeatCurrent "Left body controller: front seat heat current; raw 12 = signal not available (SNA)";
CM_ SG_ 738 VCLEFT_frontSeatHeatDuty "Left body controller: front seat heat duty";
CM_ SG_ 738 VCLEFT_frontSeatHeatTmp "Left body controller: front seat heat tmp";
CM_ SG_ 738 VCLEFT_frontSeatHeatTmpTarget "Left body controller: front seat heat tmp target";
CM_ SG_ 738 VCLEFT_frontSeatHeatInhibited "Left body controller: front seat heat inhibited";
CM_ SG_ 738 VCLEFT_frontSeatHeatPowered "Left body controller: front seat heat powered";
CM_ SG_ 738 VCLEFT_2RowSeatFoldLeftSwitch "Reports status of the left seat fold switch in the second row; raw 0 = signal not available (SNA)";
CM_ SG_ 738 VCLEFT_2RowSeatUnfoldLeftSwitch "Reports status of the left seat unfold switch in the second row; raw 0 = signal not available (SNA)";
CM_ SG_ 738 VCLEFT_2RowSeatFoldRightSwitch "Reports status of the right seat fold switch in the second row; raw 0 = signal not available (SNA)";
CM_ SG_ 738 VCLEFT_2RowSeatUnfoldRightSwitch "Reports status of the right seat unfold switch in the second row; raw 0 = signal not available (SNA)";
CM_ SG_ 738 VCLEFT_3RowSeatFoldLeftSwitch "Reports status of the left seat fold switch in the third row; raw 0 = signal not available (SNA)";
CM_ SG_ 738 VCLEFT_3RowSeatUnfoldLeftSwitch "Reports status of the left seat unfold switch in the third row; raw 0 = signal not available (SNA)";
CM_ SG_ 738 VCLEFT_3RowSeatFoldRightSwitch "Reports status of the right seat fold switch in the third row; raw 0 = signal not available (SNA)";
CM_ SG_ 738 VCLEFT_3RowSeatUnfoldRightSwitch "Reports status of the right seat unfold switch in the third row; raw 0 = signal not available (SNA)";
CM_ SG_ 738 VC_AH_1RowLeftSeatHeatVentHealth "Left body controller: AH 1 row left seat heat vent health";
CM_ SG_ 738 VCLEFT_2RowSeatReclineState "Reports the active state of the 2nd row seat recliner; raw 15 = signal not available (SNA)";
CM_ SG_ 738 VCLEFT_2RowSeatReclineDuty "Reports the 2nd row seat recliner motor duty cycle";
CM_ SG_ 738 VCLEFT_2RowSeatReclineCurrent "Reports the 2nd row seat recliner motor current";
CM_ SG_ 738 VCLEFT_2RowSeatReclineCalibrated "Reports calibration status of the 2nd row seat recliner";
CM_ SG_ 738 VCLEFT_2RowSeatReclinePositionRa "Reports the 2nd row seat recliner raw encoder count";
CM_ SG_ 738 VCLEFT_2RowSeatReclineAngle "Reports the position of the 2nd row seat recliner in degrees";
CM_ SG_ 738 VCLEFT_2RowSeatReclineAbsPosSwit "Reports the status of 2nd row seat recline absolute position (comfort zone) switch; raw 0 = signal not available (SNA)";
CM_ SG_ 738 VCLEFT_2RowSeatReclinePositionSt "Reports the active position state of the 2nd row seat recliner; raw 4 = signal not available (SNA)";
CM_ SG_ 738 VCLEFT_2RowSeatReclineAdjustment "Indicates whether adjustment requests are currently permitted for the rear seat recliner";
CM_ SG_ 738 VCLEFT_2RowSeatReclineFoldAllowe "Indicates whether auto-fold requests are currently permitted for the rear seat recliner";
CM_ SG_ 738 VCLEFT_2RowSeatReclineUnfoldAllo "Indicates whether auto-unfold requests are currently permitted for the rear seat recliner";
CM_ SG_ 738 VCLEFT_2RowSeatReclineNextToggle "Left body controller: 2 row seat recline next toggle direction; raw 2 = signal not available (SNA)";
CM_ SG_ 738 VCLEFT_2RowSeatReclineChoreoBloc "Left body controller: 2 row seat recline choreo blocked by occupancy";
CM_ SG_ 738 VCLEFT_2RowSeat1RClashAvoidanceB "Left body controller: 2 row seat1 r clash avoidance blocked reason";
CM_ SG_ 738 VCLEFT_2RowSeat1RClashAvoidanceS "Left body controller: 2 row seat1 r clash avoidance state";
CM_ SG_ 738 VCLEFT_2RowSeatReclineAbsPo_0001 "Left body controller: 2 row seat recline abs pos switch trans point";
CM_ SG_ 738 VC_AH_2RowLeftSeatMovementHealth "Left body controller: AH 2 row left seat movement health";
CM_ SG_ 738 VCLEFT_3RowSeatReclineState "Reports active state of the rear seat recliner; raw 15 = signal not available (SNA)";
CM_ SG_ 738 VCLEFT_3RowSeatReclineDuty "Reports the third row seat recliner motor duty cycle";
CM_ SG_ 738 VCLEFT_3RowSeatReclineCurrent "Reports the third row seat recliner motor current";
CM_ SG_ 738 VCLEFT_3RowSeatReclineCalibrated "Reports calibration status of the third row seat recliner";
CM_ SG_ 738 VCLEFT_3RowSeatReclinePositionRa "Reports the third row seat recliner raw encoder count";
CM_ SG_ 738 VCLEFT_3RowSeatReclineAngle "Reports position of the 3rd row seat recliner in degrees";
CM_ SG_ 738 VCLEFT_3RowSeatReclineNextToggle "Left body controller: 3 row seat recline next toggle direction; raw 2 = signal not available (SNA)";
CM_ SG_ 738 VCLEFT_3RRightCushionHeatCurrent "Current drawn by 3rd row right seat heater";
CM_ SG_ 738 VCLEFT_3RRightCushionHeatDuty "3rd row right seat heater duty cycle";
CM_ SG_ 738 VCLEFT_3RRightCushionHeatTmp "Left body controller: 3 r right cushion heat tmp";
CM_ SG_ 738 VCLEFT_3RRightCushionHeatTmpTarg "Target temperature for 3rd row right seat heater";
CM_ SG_ 738 VCLEFT_3RRightCushionHeatInhibit "Status describing whether 3rd row right seat heat is inhibited";
CM_ SG_ 738 VCLEFT_3RowSeatReclinePositionSt "Reports active position state of the rear seat recliner; raw 4 = signal not available (SNA)";
CM_ SG_ 738 VCLEFT_3RowSeatReclineAdjustment "Indicates whether adjustment requests are currently permitted for the rear seat recliner";
CM_ SG_ 738 VCLEFT_3RowSeatReclineFoldAllowe "Indicates whether auto-fold requests are currently permitted for the rear seat recliner";
CM_ SG_ 738 VCLEFT_3RowSeatReclineUnfoldAllo "Indicates whether auto-unfold requests are currently permitted for the rear seat recliner";
CM_ SG_ 738 VCLEFT_3RowSeatReclineChoreoBloc "Left body controller: 3 row seat recline choreo blocked by occupancy";
CM_ SG_ 738 VCLEFT_3RowSeatReclineAbsPosSwit "Reports status of 2R seat recline absolute position (comfort zone) switch; raw 0 = signal not available (SNA)";
CM_ BO_ 930 "Left body controller message: status";
CM_ SG_ 930 VCLEFT_statusIndex "Left body controller: status index";
CM_ SG_ 930 VCLEFT_securityControllerEnable "Left body controller: security controller enable";
CM_ SG_ 930 VCLEFT_securityControllerVoltage "Voltage of the VCSEC power feed";
CM_ SG_ 930 VCLEFT_consoleDoorAssist "Left body controller: console door assist";
CM_ SG_ 930 VCLEFT_OTAState "Left body controller: OTA state";
CM_ SG_ 930 VCLEFT_5AVoltage "Left body controller: 5 a voltage";
CM_ SG_ 930 VCLEFT_vbatProt "Left body controller: vbat prot";
CM_ SG_ 930 VCLEFT_footwellLightCurrent "Left body controller: footwell light current";
CM_ SG_ 930 VCLEFT_swcInputVoltage "Input voltage reported by steering wheel controller module; raw 255 = signal not available (SNA)";
CM_ SG_ 930 VCLEFT_swcPCBATemperature "Left body controller: swc PCBA temperature; raw 128 = signal not available (SNA)";
CM_ SG_ 930 VCLEFT_obdEthernetActive "Left body controller: obd ethernet active";
CM_ SG_ 930 VCLEFT_rationalityAggregateCurre "Left body controller: rationality aggregate current";
CM_ SG_ 930 VCLEFT_LVBatteryTypeDBG "Left body controller: LV battery type DBG";
CM_ SG_ 930 VCLEFT_DIeFuseFault "Left body controller: d ie fuse fault";
CM_ SG_ 930 VCLEFT_eFuseMgmtVoltageMonitor "Left body controller: e fuse mgmt voltage monitor";
CM_ SG_ 930 VCLEFT_trailerAuxCurrent "Current Draw of the trailer aux output; raw 4095 = signal not available (SNA)";
CM_ SG_ 930 VCLEFT_swcHeatTmp "Temperature of steering wheel heater as reported by NTC; raw 1023 = signal not available (SNA)";
CM_ SG_ 930 VCLEFT_swcHeatStatus "Status of steering wheel heater; raw 0 = signal not available (SNA)";
CM_ SG_ 930 VCLEFT_swcHeatInhibited "Status describing whether steering wheel heat is inhibited";
CM_ SG_ 930 VCLEFT_obdDeviceDetected "Reports whether the Left Vehicle Controller (VCLEFT) detects that an external device is connected to the OBD port.";
CM_ SG_ 930 VCLEFT_pcbaTemperature "Left body controller: pcba temperature";
CM_ SG_ 930 VCLEFT_swcHeatPwr "Power of steering wheel heater; raw 511 = signal not available (SNA)";
CM_ SG_ 930 VCLEFT_swcHeatDutyCycle "Steering wheel heater duty cycle; raw 127 = signal not available (SNA)";
CM_ SG_ 930 VCLEFT_DIeFuseCurrent "Left body controller: d ie fuse current";
CM_ SG_ 930 VCLEFT_SWCpresent "Left body controller: SW cpresent";
CM_ SG_ 930 VCLEFT_autonomyBehaviorStatus "Left body controller: autonomy behavior status";
CM_ SG_ 930 VCLEFT_thirdRowLeftMapLightStatu "Reports the status of the third row left overhead map light.; raw 3 = signal not available (SNA)";
CM_ SG_ 930 VCLEFT_thirdRowRightMapLightStat "Reports the status of the third row right overhead map light; raw 3 = signal not available (SNA)";
CM_ BO_ 610 "Left body controller message: steering column status";
CM_ SG_ 610 VCLEFT_steeringColumnSMState "Status of steering column state machine; raw 0 = signal not available (SNA)";
CM_ SG_ 610 VCLEFT_steeringColumnLastRequest "Left body controller: steering column last request; raw 0 = signal not available (SNA)";
CM_ SG_ 610 VCLEFT_steeringColumnUpDownDuty "Steering column tilt motor duty cycle";
CM_ SG_ 610 VCLEFT_steeringColumnInOutDuty "Steering column telescope motor duty cycle";
CM_ SG_ 610 VCLEFT_steeringColumnUpDownPos "Motor encoder value representing steering column tilt position";
CM_ SG_ 610 VCLEFT_steeringColumnInOutPos "Motor encoder value representing steering column telescope position";
CM_ SG_ 610 VCLEFT_steeringColumnUpDownAmps "Measures current used by the steering column tilt motor.";
CM_ SG_ 610 VCLEFT_steeringColumnInOutAmps "Measures current used by the steering column telescope motor.";
CM_ SG_ 610 VCLEFT_steeringColumnUpDownCalib "Left body controller: steering column up down calib";
CM_ SG_ 610 VCLEFT_steeringColumnInOutCalib "Left body controller: steering column in out calib";
CM_ SG_ 610 VCLEFT_steeringColumnUpDownTC "Left body controller: steering column up down TC";
CM_ SG_ 610 VCLEFT_steeringColumnInOutTC "Left body controller: steering column in out TC";
CM_ BO_ 962 "Left body controller message: switch status";
CM_ SG_ 962 VCLEFT_switchStatusIndex "Left body controller: switch status index";
CM_ SG_ 962 VCLEFT_hornSwitchPressed "Left body controller: horn switch pressed";
CM_ SG_ 962 VCLEFT_hazardButtonPressed "Left body controller: hazard button pressed";
CM_ SG_ 962 VCLEFT_brakeSwitchPressed "Status of the brake pedal switch";
CM_ SG_ 962 VCLEFT_rightMirrorTilt "Left body controller: right mirror tilt";
CM_ SG_ 962 VCLEFT_frontSeatTrackBack "Left body controller: front seat track back; raw 0 = signal not available (SNA)";
CM_ SG_ 962 VCLEFT_frontSeatTrackForward "Left body controller: front seat track forward; raw 0 = signal not available (SNA)";
CM_ SG_ 962 VCLEFT_frontSeatTiltDown "Left body controller: front seat tilt down; raw 0 = signal not available (SNA)";
CM_ SG_ 962 VCLEFT_frontSeatTiltUp "Left body controller: front seat tilt up; raw 0 = signal not available (SNA)";
CM_ SG_ 962 VCLEFT_frontSeatLiftDown "Left body controller: front seat lift down; raw 0 = signal not available (SNA)";
CM_ SG_ 962 VCLEFT_frontSeatLiftUp "Left body controller: front seat lift up; raw 0 = signal not available (SNA)";
CM_ SG_ 962 VCLEFT_frontSeatBackrestBack "Left body controller: front seat backrest back; raw 0 = signal not available (SNA)";
CM_ SG_ 962 VCLEFT_frontSeatBackrestForward "Left body controller: front seat backrest forward; raw 0 = signal not available (SNA)";
CM_ SG_ 962 VCLEFT_frontSeatLumbarDown "Left body controller: front seat lumbar down; raw 0 = signal not available (SNA)";
CM_ SG_ 962 VCLEFT_frontSeatLumbarUp "Left body controller: front seat lumbar up; raw 0 = signal not available (SNA)";
CM_ SG_ 962 VCLEFT_frontSeatLumbarIn "Left body controller: front seat lumbar in; raw 0 = signal not available (SNA)";
CM_ SG_ 962 VCLEFT_frontSeatLumbarOut "Left body controller: front seat lumbar out; raw 0 = signal not available (SNA)";
CM_ SG_ 962 VCLEFT_btnWindowSwPackUpLF "Left body controller: btn window sw pack up LF";
CM_ SG_ 962 VCLEFT_btnWindowSwPackAutoUpLF "Left body controller: btn window sw pack auto up LF";
CM_ SG_ 962 VCLEFT_btnWindowSwPackDownLF "Left body controller: btn window sw pack down LF";
CM_ SG_ 962 VCLEFT_btnWindowSwPackAutoDownLF "Left body controller: btn window sw pack auto down LF";
CM_ SG_ 962 VCLEFT_btnWindowSwPackUpLR "Left body controller: btn window sw pack up LR";
CM_ SG_ 962 VCLEFT_btnWindowSwPackAutoUpLR "Left body controller: btn window sw pack auto up LR";
CM_ SG_ 962 VCLEFT_btnWindowSwPackDownLR "Left body controller: btn window sw pack down LR";
CM_ SG_ 962 VCLEFT_btnWindowSwPackAutoDownLR "Left body controller: btn window sw pack auto down LR";
CM_ SG_ 962 VCLEFT_btnWindowSwPackUpRF "Left body controller: btn window sw pack up RF";
CM_ SG_ 962 VCLEFT_btnWindowSwPackAutoUpRF "Left body controller: btn window sw pack auto up RF";
CM_ SG_ 962 VCLEFT_btnWindowSwPackDownRF "Left body controller: btn window sw pack down RF";
CM_ SG_ 962 VCLEFT_btnWindowSwPackAutoDownRF "Left body controller: btn window sw pack auto down RF";
CM_ SG_ 962 VCLEFT_btnWindowSwPackUpRR "Left body controller: btn window sw pack up RR";
CM_ SG_ 962 VCLEFT_btnWindowSwPackAutoUpRR "Left body controller: btn window sw pack auto up RR";
CM_ SG_ 962 VCLEFT_btnWindowSwPackDownRR "Left body controller: btn window sw pack down RR";
CM_ SG_ 962 VCLEFT_btnWindowSwPackAutoDownRR "Left body controller: btn window sw pack auto down RR";
CM_ SG_ 962 VCLEFT_frontBuckleSwitch "Left body controller: front buckle switch; raw 0 = signal not available (SNA)";
CM_ SG_ 962 VCLEFT_frontOccupancySwitch "Front left seat occupancy status; raw 0 = signal not available (SNA)";
CM_ SG_ 962 VCLEFT_rearLeftBuckleSwitch "Left body controller: rear left buckle switch; raw 0 = signal not available (SNA)";
CM_ SG_ 962 VCLEFT_rearCenterOccupancySwitch "Left body controller: rear center occupancy switch; raw 0 = signal not available (SNA)";
CM_ SG_ 962 VCLEFT_rearLeftOccupancySwitch "Left body controller: rear left occupancy switch; raw 0 = signal not available (SNA)";
CM_ SG_ 962 VCLEFT_rearRightOccupancySwitch "Left body controller: rear right occupancy switch; raw 0 = signal not available (SNA)";
CM_ SG_ 962 VCLEFT_brakePressed "Status of the brake pedal";
CM_ SG_ 962 VCLEFT_rearHVACButtonPressed "Left body controller: rear HVAC button pressed";
CM_ SG_ 962 VCLEFT_rearCenterBuckleSwitch "Left body controller: rear center buckle switch; raw 0 = signal not available (SNA)";
CM_ SG_ 962 VCLEFT_isAlcoholInterlockSet "Reports if the alcohol interlock is set.";
CM_ SG_ 962 VCLEFT_swcLeftTiltRight "Left body controller: swc left tilt right; raw 0 = signal not available (SNA)";
CM_ SG_ 962 VCLEFT_swcLeftPressed "Left body controller: swc left pressed; raw 0 = signal not available (SNA)";
CM_ SG_ 962 VCLEFT_swcRightTiltLeft "Left body controller: swc right tilt left; raw 0 = signal not available (SNA)";
CM_ SG_ 962 VCLEFT_swcRightTiltRight "Left body controller: swc right tilt right; raw 0 = signal not available (SNA)";
CM_ SG_ 962 VCLEFT_swcRightPressed "Left body controller: swc right pressed; raw 0 = signal not available (SNA)";
CM_ SG_ 962 VCLEFT_swcLeftTiltLeft "Left body controller: swc left tilt left; raw 0 = signal not available (SNA)";
CM_ SG_ 962 VCLEFT_swcLeftScrollTicks "Left body controller: swc left scroll ticks";
CM_ SG_ 962 VCLEFT_swcWiperButtonState "Left body controller: swc wiper button state";
CM_ SG_ 962 VCLEFT_swcRightScrollTicks "Encoder value for right steering wheel switch scroll";
CM_ SG_ 962 VCLEFT_swcTurnSignalLeftButtonSt "Left body controller: swc turn signal left button state";
CM_ SG_ 962 VCLEFT_btnWindowUpLR "Left body controller: btn window up LR";
CM_ SG_ 962 VCLEFT_btnWindowAutoUpLR "Left body controller: btn window auto up LR";
CM_ SG_ 962 VCLEFT_btnWindowDownLR "Left body controller: btn window down LR";
CM_ SG_ 962 VCLEFT_btnWindowAutoDownLR "Left body controller: btn window auto down LR";
CM_ SG_ 962 VCLEFT_2RowSeatLeftFoldFlatSwitc "Second row seat left fold flat switch";
CM_ SG_ 962 VCLEFT_2RowSeatRightFoldFlatSwit "Second row seat right fold flat switch";
CM_ SG_ 962 VCLEFT_2RowSeatBothFoldFlatSwitc "Second row seat both fold flat switch";
CM_ SG_ 962 VCLEFT_swcLeftDoublePress "Left body controller: swc left double press";
CM_ SG_ 962 VCLEFT_swcRightDoublePress "Left body controller: swc right double press";
CM_ SG_ 962 VCLEFT_swcTurnSignalRightButtonS "Left body controller: swc turn signal right button state";
CM_ SG_ 962 VCLEFT_swcHighBeamButtonState "Left body controller: swc high beam button state";
CM_ SG_ 962 VCLEFT_swcVoiceControlPress "Left body controller: swc voice control press; raw 0 = signal not available (SNA)";
CM_ SG_ 962 VCLEFT_swcCameraButtonState "Left body controller: swc camera button state";
CM_ SG_ 962 VCLEFT_swcRightPressedQF "Quality of steering wheel right scroll wheel button signal";
CM_ SG_ 962 VCLEFT_frontSeatResistiveOccupan "Front left seat occupancy status; raw 0 = signal not available (SNA)";
CM_ BO_ 656 "Left body controller message: thermal logging10 hz";
CM_ SG_ 656 VCLEFT_thermalLogging10HzIndex "Left body controller: thermal logging10 hz index";
CM_ SG_ 656 VCLEFT_hvac2RLeftLateralVoltage "Left body controller: hvac2 r left lateral voltage";
CM_ SG_ 656 VCLEFT_hvac2RLeftVerticalVoltage "Left body controller: hvac2 r left vertical voltage";
CM_ SG_ 656 VCLEFT_hvac2RRightLateralVoltage "Left body controller: hvac2 r right lateral voltage";
CM_ SG_ 656 VCLEFT_hvac2RRightVerticalVoltag "Left body controller: hvac2 r right vertical voltage";
CM_ SG_ 656 VCLEFT_hvac2RLeftLateralCalibrat "Left body controller: hvac2 r left lateral calibrated";
CM_ SG_ 656 VCLEFT_hvac2RLeftVerticalCalibra "Left body controller: hvac2 r left vertical calibrated";
CM_ SG_ 656 VCLEFT_hvac2RRightLateralCalibra "Left body controller: hvac2 r right lateral calibrated";
CM_ SG_ 656 VCLEFT_hvac2RRightVerticalCalibr "Left body controller: hvac2 r right vertical calibrated";
CM_ SG_ 656 VCLEFT_hvac2RLeftLateralState "Left body controller: hvac2 r left lateral state";
CM_ SG_ 656 VCLEFT_hvac2RLeftVerticalState "Left body controller: hvac2 r left vertical state";
CM_ SG_ 656 VCLEFT_hvac2RRightLateralState "Left body controller: hvac2 r right lateral state";
CM_ SG_ 656 VCLEFT_hvac2RRightVerticalState "Left body controller: hvac2 r right vertical state";
CM_ SG_ 656 VCLEFT_hvacBlowerWindmillElecRpm "Left body controller: hvac blower windmill elec rpm";
CM_ SG_ 656 VCLEFT_hvac2RRightVerticalVeloci "Left body controller: hvac2 r right vertical velocity";
CM_ SG_ 656 VCLEFT_hvacBlowerWindmillBemf "Left body controller: hvac blower windmill bemf";
CM_ SG_ 656 VCLEFT_hvac2RLeftVerticalVelocit "Left body controller: hvac2 r left vertical velocity";
CM_ SG_ 656 VCLEFT_hvac2RLeftLateralVelocity "Left body controller: hvac2 r left lateral velocity";
CM_ SG_ 656 VCLEFT_vcusbLinSchedule "Left body controller: vcusb lin schedule";
CM_ SG_ 656 VCLEFT_hvacBlowerArbState "Left body controller: hvac blower arb state";
CM_ SG_ 656 VCLEFT_hvacBlowerArbResult "Left body controller: hvac blower arb result";
CM_ SG_ 656 VCLEFT_hvac2RLeftLateralDuty "Left body controller: hvac2 r left lateral duty";
CM_ SG_ 656 VCLEFT_hvac2RLeftVerticalDuty "Left body controller: hvac2 r left vertical duty";
CM_ SG_ 656 VCLEFT_hvac2RRightLateralDuty "Left body controller: hvac2 r right lateral duty";
CM_ SG_ 656 VCLEFT_hvac2RRightVerticalDuty "Left body controller: hvac2 r right vertical duty";
CM_ SG_ 656 VCLEFT_hvacBlowerWindmilling "Left body controller: hvac blower windmilling";
CM_ SG_ 656 VCLEFT_hvac2RRightLateralVelocit "Left body controller: hvac2 r right lateral velocity";
CM_ SG_ 656 VCLEFT_hvacBlower1msOverrunFrequ "Left body controller: hvac blower1ms overrun frequency";
CM_ SG_ 656 VCLEFT_hvacBlower10msOverrunFreq "Left body controller: hvac blower10ms overrun frequency";
CM_ BO_ 657 "Left body controller message: thermal logging1 hz";
CM_ SG_ 657 VCLEFT_thermalLogging1HzIndex "Left body controller: thermal logging1 hz index";
CM_ SG_ 657 VCLEFT_hvac2RLeftLateralZeroStop "Left body controller: hvac2 r left lateral zero stop voltage";
CM_ SG_ 657 VCLEFT_hvac2RLeftVerticalZeroSto "Left body controller: hvac2 r left vertical zero stop voltage";
CM_ SG_ 657 VCLEFT_hvac2RRightLateralZeroSto "Left body controller: hvac2 r right lateral zero stop voltage";
CM_ SG_ 657 VCLEFT_hvac2RRightVerticalZeroSt "Left body controller: hvac2 r right vertical zero stop voltage";
CM_ SG_ 657 VCLEFT_hvac2RLeftLateralEndStopV "Left body controller: hvac2 r left lateral end stop voltage";
CM_ SG_ 657 VCLEFT_hvac2RLeftVerticalEndStop "Left body controller: hvac2 r left vertical end stop voltage";
CM_ SG_ 657 VCLEFT_hvac2RRightLateralEndStop "Left body controller: hvac2 r right lateral end stop voltage";
CM_ SG_ 657 VCLEFT_hvac2RRightVerticalEndSto "Left body controller: hvac2 r right vertical end stop voltage";
CM_ SG_ 657 VCLEFT_hvacBlowerArbCurrent "Left body controller: hvac blower arb current";
CM_ SG_ 657 VCLEFT_hvacBlowerTorqueIndexFilt "Left body controller: hvac blower torque index filtered";
CM_ BO_ 386 "Left body controller message: thermal status";
CM_ SG_ 386 VCLEFT_hvac2RLeftLateralStatus "Left body controller: hvac2 r left lateral status";
CM_ SG_ 386 VCLEFT_hvac2RLeftVerticalStatus "Left body controller: hvac2 r left vertical status";
CM_ SG_ 386 VCLEFT_hvac2RRightLateralStatus "Left body controller: hvac2 r right lateral status";
CM_ SG_ 386 VCLEFT_hvac2RRightVerticalStatus "Left body controller: hvac2 r right vertical status";
CM_ SG_ 386 VCLEFT_hvac2RLeftLateralPosition "Left body controller: hvac2 r left lateral position";
CM_ SG_ 386 VCLEFT_hvac2RLeftVerticalPositio "Left body controller: hvac2 r left vertical position";
CM_ SG_ 386 VCLEFT_hvac2RRightLateralPositio "Left body controller: hvac2 r right lateral position";
CM_ SG_ 386 VCLEFT_hvac2RRightVerticalPositi "Left body controller: hvac2 r right vertical position";
CM_ BO_ 706 "Left body controller message: window status";
CM_ SG_ 706 VCLEFT_windowStatusIndex "Left body controller: window status index";
CM_ SG_ 706 VCLEFT_windowStateLF "Status of left front window motor";
CM_ SG_ 706 VCLEFT_windowTrimClearMoveReques "Requests whether windows should enter or exit trim clear. Signal only valid if Vehicle Controller Left (VCLEFT) is on driver side.";
CM_ SG_ 706 VCLEFT_windowDutyLF "Left body controller: window duty LF";
CM_ SG_ 706 VCLEFT_windowTrimClearActiveRequ "Reports whether window trim clear is active. Signal is only valid if Vehicle Controller Left (VCLEFT) is on driver side.; raw 0 = signal not available (SNA)";
CM_ SG_ 706 VCLEFT_windowCurrentLF "Current drawn by left front window regulator";
CM_ SG_ 706 VCLEFT_windowPositionLF "Left body controller: window position LF; raw 1 = signal not available (SNA)";
CM_ SG_ 706 VCLEFT_windowCalibratedLF "Calibration status of left front window motor";
CM_ SG_ 706 VCLEFT_windowStateLR "Status of left rear window motor";
CM_ SG_ 706 VCLEFT_windowDutyLR "Left body controller: window duty LR";
CM_ SG_ 706 VCLEFT_windowCurrentLR "Current drawn by left rear window regulator";
CM_ SG_ 706 VCLEFT_windowPositionLR "Left body controller: window position LR";
CM_ SG_ 706 VCLEFT_windowCalibratedLR "Calibraiton status of left rear window motor";
CM_ SG_ 706 VCLEFT_windowThermalTCLF "Left body controller: window thermal TCLF";
CM_ SG_ 706 VCLEFT_windowThermalModeLF "Left body controller: window thermal mode LF; raw 0 = signal not available (SNA)";
CM_ SG_ 706 VCLEFT_windowStopReasonLF "Reason for left front window stopping motion";
CM_ SG_ 706 VCLEFT_windowStopReqReasonLF "Reason for left front window stopping motion";
CM_ SG_ 706 VCLEFT_windowThermalTCLR "Left body controller: window thermal TCLR";
CM_ SG_ 706 VCLEFT_windowThermalModeLR "Left body controller: window thermal mode LR; raw 0 = signal not available (SNA)";
CM_ SG_ 706 VCLEFT_windowStopReasonLR "Reason for left rear window stopping motion";
CM_ SG_ 706 VCLEFT_windowStopReqReasonLR "Reason for left rear window stopping motion";
CM_ SG_ 706 VCLEFT_windowControlStateLF "Window control state";
CM_ SG_ 706 VCLEFT_windowCtrlUnavailableLF "Window control unavailable reason";
CM_ SG_ 706 VCLEFT_windowControlStateLR "Window control state";
CM_ SG_ 706 VCLEFT_windowCtrlUnavailableLR "Window control unavailable reason";
CM_ SG_ 706 VCLEFT_windowPositionStateLF "Window position state";
CM_ SG_ 706 VCLEFT_windowPositionStateLR "Window position state";
CM_ SG_ 706 VCLEFT_windowVehGearStateLF "Window's interpretation of vehicle gear state; raw 0 = signal not available (SNA)";
CM_ SG_ 706 VCLEFT_windowVehGearStateLR "Window's interpretation of vehicle gear state; raw 0 = signal not available (SNA)";
CM_ SG_ 706 VCLEFT_windowSpeedTableStatusLF "Speed table build status of left front window; raw 0 = signal not available (SNA)";
CM_ SG_ 706 VCLEFT_windowSpeedTableStatusLR "Speed table build status of left rear window; raw 0 = signal not available (SNA)";
CM_ BO_ 549 "Right body controller message: LV power state";
CM_ SG_ 549 VCRIGHT_ptcLVState "Right body controller: ptc LV state";
CM_ SG_ 549 VCRIGHT_ocsLVState "Right body controller: ocs LV state";
CM_ SG_ 549 VCRIGHT_premAudioLVState "Right body controller: prem audio LV state";
CM_ SG_ 549 VCRIGHT_rearOilPumpLVState "Right body controller: rear oil pump LV state";
CM_ SG_ 549 VCRIGHT_tunerLVState "Right body controller: tuner LV state";
CM_ SG_ 549 VCRIGHT_hvcLVState "Right body controller: hvc LV state";
CM_ SG_ 549 VCRIGHT_rcmLVState "Right body controller: rcm LV state";
CM_ SG_ 549 VCRIGHT_lumbarLVState "Right body controller: lumbar LV state";
CM_ SG_ 549 VCRIGHT_3RUSBPowered "State of power to the 3R USB Ports";
CM_ SG_ 549 VCRIGHT_cntctrPwrState "Right body controller: cntctr pwr state";
CM_ SG_ 549 VCRIGHT_eFuseLockoutStatus "Right body controller: e fuse lockout status";
CM_ SG_ 549 VCRIGHT_swEnStatus "Status of the internal switched power rail on the board";
CM_ SG_ 549 VCRIGHT_vehiclePowerStateDBG "Right body controller: vehicle power state DBG";
CM_ SG_ 549 VCRIGHT_parkLVState "Right body controller: park LV state";
CM_ SG_ 549 VCRIGHT_icrLVState "Right body controller: icr LV state";
CM_ SG_ 549 VCRIGHT_interiorCameraLedLVState "Right body controller: interior camera led LV state";
CM_ SG_ 549 VCRIGHT_diLVState "Right body controller: di LV state";
CM_ SG_ 549 VCRIGHT_accDevicesDetected "At least one accessory device detected on accessory ports";
CM_ BO_ 643 "Right body controller message: PTC request";
CM_ SG_ 643 VCRIGHT_PTCLeftTargetPowerHV "Right body controller: PTC left target power HV";
CM_ SG_ 643 VCRIGHT_PTCRightTargetPowerHV "Right body controller: PTC right target power HV";
CM_ SG_ 643 VCRIGHT_PTCLeftTargetDuty "Right body controller: PTC left target duty";
CM_ SG_ 643 VCRIGHT_PTCRightTargetDuty "Right body controller: PTC right target duty";
CM_ SG_ 643 VCRIGHT_PTCFlagAllowOperation "Right body controller: PTC flag allow operation";
CM_ SG_ 643 VCRIGHT_PTCRequestMode "Right body controller: PTC request mode";
CM_ SG_ 643 VCRIGHT_PTCResistanceCheckEnable "Right body controller: PTC resistance check enable";
CM_ SG_ 643 VCRIGHT_PTCReset "Right body controller: PTC reset";
CM_ SG_ 643 VCRIGHT_PTCLeftDirectDriveIGBTO "Right body controller: PTC left direct drive IGBTO";
CM_ SG_ 643 VCRIGHT_PTCLeftDirectDriveIGBTC "Right body controller: PTC left direct drive IGBTC";
CM_ SG_ 643 VCRIGHT_PTCLeftDirectDriveIGBTI "Right body controller: PTC left direct drive IGBTI";
CM_ SG_ 643 VCRIGHT_PTCRightDirectDriveIGBTI "Right body controller: PTC right direct drive IGBTI";
CM_ SG_ 643 VCRIGHT_PTCRightDirectDriveIGBTC "Right body controller: PTC right direct drive IGBTC";
CM_ SG_ 643 VCRIGHT_PTCRightDirectDriveIGBTO "Right body controller: PTC right direct drive IGBTO";
CM_ BO_ 1795 "Right body controller message: debug thermal10 hz";
CM_ SG_ 1795 VCRIGHT_debugThermal10HzIndex "Right body controller: debug thermal10 hz index";
CM_ SG_ 1795 VCRIGHT_hvacPanelFloorSplitRow1 "Right body controller: hvac panel floor split row1";
CM_ SG_ 1795 VCRIGHT_hvacDefrostPercent "Right body controller: hvac defrost percent";
CM_ SG_ 1795 VCRIGHT_hvacRow2Percent "Right body controller: hvac row2 percent";
CM_ SG_ 1795 VCRIGHT_hvacPanelFloorSplitRow2 "Right body controller: hvac panel floor split row2";
CM_ SG_ 1795 VCRIGHT_hvacFreshMassCounter "Right body controller: hvac fresh mass counter";
CM_ SG_ 1795 VCRIGHT_hvacRecircMassCounter "Right body controller: hvac recirc mass counter";
CM_ SG_ 1795 VCRIGHT_setTempAdjustmentLeft "Right body controller: set temp adjustment left; raw 127 = signal not available (SNA)";
CM_ SG_ 1795 VCRIGHT_setTempAdjustmentRight "Right body controller: set temp adjustment right; raw 127 = signal not available (SNA)";
CM_ SG_ 1795 VCRIGHT_hvacLHVaneVelocity "Right body controller: hvac LH vane velocity";
CM_ SG_ 1795 VCRIGHT_hvacRHVaneVelocity "Right body controller: hvac RH vane velocity";
CM_ SG_ 1795 VCRIGHT_hvacVehicleSpeed "Right body controller: hvac vehicle speed";
CM_ SG_ 1795 VCRIGHT_hvacMassflowCompensated "Right body controller: hvac massflow compensated";
CM_ SG_ 1795 VCRIGHT_PTCcenterPowerLeft "Right body controller: PT ccenter power left; raw 63 = signal not available (SNA)";
CM_ SG_ 1795 VCRIGHT_PTCouterPowerLeft "Right body controller: PT couter power left; raw 63 = signal not available (SNA)";
CM_ SG_ 1795 VCRIGHT_PTCinnerPowerLeft "Right body controller: PT cinner power left; raw 63 = signal not available (SNA)";
CM_ SG_ 1795 VCRIGHT_PTCcenterPowerRight "Right body controller: PT ccenter power right; raw 63 = signal not available (SNA)";
CM_ SG_ 1795 VCRIGHT_PTCouterPowerRight "Right body controller: PT couter power right; raw 63 = signal not available (SNA)";
CM_ SG_ 1795 VCRIGHT_PTCinnerPowerRight "Right body controller: PT cinner power right; raw 63 = signal not available (SNA)";
CM_ SG_ 1795 VCRIGHT_PTCcenterStoneTempLeft "Right body controller: PT ccenter stone temp left; raw 255 = signal not available (SNA)";
CM_ SG_ 1795 VCRIGHT_PTCcenterStoneTempRight "Right body controller: PT ccenter stone temp right; raw 255 = signal not available (SNA)";
CM_ SG_ 1795 VCRIGHT_PTCinnerStoneTempLeft "Right body controller: PT cinner stone temp left; raw 255 = signal not available (SNA)";
CM_ SG_ 1795 VCRIGHT_PTCinnerStoneTempRight "Right body controller: PT cinner stone temp right; raw 255 = signal not available (SNA)";
CM_ SG_ 1795 VCRIGHT_PTCouterStoneTempLeft "Right body controller: PT couter stone temp left; raw 255 = signal not available (SNA)";
CM_ SG_ 1795 VCRIGHT_PTCouterRodTempLeft "Right body controller: PT couter rod temp left; raw 255 = signal not available (SNA)";
CM_ SG_ 1795 VCRIGHT_PTCouterAirTempLeft "Right body controller: PT couter air temp left; raw 255 = signal not available (SNA)";
CM_ SG_ 1795 VCRIGHT_PTCcenterRodTempLeft "Right body controller: PT ccenter rod temp left; raw 255 = signal not available (SNA)";
CM_ SG_ 1795 VCRIGHT_PTCinnerRodTempLeft "Right body controller: PT cinner rod temp left; raw 255 = signal not available (SNA)";
CM_ SG_ 1795 VCRIGHT_PTCcenterAirTempLeft "Right body controller: PT ccenter air temp left; raw 255 = signal not available (SNA)";
CM_ SG_ 1795 VCRIGHT_PTCinnerAirTempLeft "Right body controller: PT cinner air temp left; raw 255 = signal not available (SNA)";
CM_ SG_ 1795 VCRIGHT_PTCouterStoneTempRight "Right body controller: PT couter stone temp right; raw 255 = signal not available (SNA)";
CM_ SG_ 1795 VCRIGHT_PTCouterRodTempRight "Right body controller: PT couter rod temp right; raw 255 = signal not available (SNA)";
CM_ SG_ 1795 VCRIGHT_PTCouterAirTempRight "Right body controller: PT couter air temp right; raw 255 = signal not available (SNA)";
CM_ SG_ 1795 VCRIGHT_PTCcenterRodTempRight "Right body controller: PT ccenter rod temp right; raw 255 = signal not available (SNA)";
CM_ SG_ 1795 VCRIGHT_PTCinnerRodTempRight "Right body controller: PT cinner rod temp right; raw 255 = signal not available (SNA)";
CM_ SG_ 1795 VCRIGHT_PTCcenterAirTempRight "Right body controller: PT ccenter air temp right; raw 255 = signal not available (SNA)";
CM_ SG_ 1795 VCRIGHT_PTCinnerAirTempRight "Right body controller: PT cinner air temp right; raw 255 = signal not available (SNA)";
CM_ BO_ 291 "Right body controller message: door status2";
CM_ SG_ 291 VCRIGHT_doorStatus2Index "Right body controller: door status2 index";
CM_ SG_ 291 VCRIGHT_frontLatchRelDuty "Front left door latch motor duty cycle.";
CM_ SG_ 291 VCRIGHT_BPillarCameraHeaterState "Indicates the state of the right b-pillar camera heater; raw 0 = signal not available (SNA)";
CM_ SG_ 291 VCRIGHT_doorLatchAjarSwitchVolta "Door latch switch voltage feeding switch logic";
CM_ SG_ 291 VCRIGHT_doorLatchAjarSwitch_0001 "Door latch switch voltage feeding switch logic";
CM_ SG_ 291 VCRIGHT_BPillarCameraHeaterCurre "Current drawn by the right b-pillar camera heater; raw 63 = signal not available (SNA)";
CM_ SG_ 291 VCRIGHT_mirrorTiltXOffset "Communicates post calibration position offset of right side view mirror tilt horizontal position";
CM_ SG_ 291 VCRIGHT_mirrorTiltYOffset "Communicates post calibration position offset of right side view mirror tilt vertical position";
CM_ BO_ 915 "Right body controller message: epbm debug";
CM_ SG_ 915 VCRIGHT_epbmDebugIndex "Right body controller: epbm debug index";
CM_ SG_ 915 VCRIGHT_epbmCaliperState "Right body controller: epbm caliper state";
CM_ SG_ 915 VCRIGHT_epbmMotorEnabled "Right body controller: epbm motor enabled";
CM_ SG_ 915 VCRIGHT_epbMotorCurrent "Right body controller: epb motor current";
CM_ SG_ 915 VCRIGHT_epbmApplyVoltage "Right body controller: epbm apply voltage";
CM_ SG_ 915 VCRIGHT_epbmReleaseVoltage "Right body controller: epbm release voltage";
CM_ SG_ 915 VCRIGHT_summonFaultReason "Electronic Parking Brake Monitors error code associated with previous summon failure.";
CM_ SG_ 915 VCRIGHT_epbSummonState "Electronic Parking Brake Monitors reading of Electronic Parking Brake's summon state.";
CM_ SG_ 915 VCRIGHT_epbmSummonState "Electronic Parking Brake Monitors summon state.";
CM_ SG_ 915 VCRIGHT_epbUnitStatus "Electronic Parking Brake Monitors reading of Electronic Parking Brake's state.";
CM_ SG_ 915 VCRIGHT_epbmFaultStatus "Electronic Parking Brake Monitors fault state.";
CM_ SG_ 915 VCRIGHT_epbFaultStatus "Electronic Parking Brake Monitors reading of Electronic Parking Brake's fault state.";
CM_ SG_ 915 VCRIGHT_epbmSystemStatus "Electronic Parking Brake Monitors reading of Electronic Parking Brake's state.";
CM_ SG_ 915 VCRIGHT_epbmAutonomyBehavior "Right body controller: epbm autonomy behavior";
CM_ BO_ 524 "Right body controller message: hvac request";
CM_ SG_ 524 VCRIGHT_wattsDemandEvap "Right body controller: watts demand evap";
CM_ SG_ 524 VCRIGHT_hvacEvapEnabled "Right body controller: hvac evap enabled";
CM_ SG_ 524 VCRIGHT_conditioningRequest "Right body controller: conditioning request";
CM_ SG_ 524 VCRIGHT_tempEvaporator "Evaporator temperature; raw 2047 = signal not available (SNA)";
CM_ SG_ 524 VCRIGHT_tempEvaporatorTarget "Evaporator temperature target; raw 255 = signal not available (SNA)";
CM_ SG_ 524 VCRIGHT_hvacBlowerSpeedRPMReq "Right body controller: hvac blower speed RPM req";
CM_ SG_ 524 VCRIGHT_hvacPerfTestRunning "Right body controller: hvac perf test running";
CM_ SG_ 524 VCRIGHT_evapPerformanceLow "Right body controller: evap performance low";
CM_ SG_ 524 VCRIGHT_tempAmbientRaw "Right body controller: temp ambient raw; raw 0 = signal not available (SNA)";
CM_ SG_ 524 VCRIGHT_hvacHeatingEnabledLeft "Right body controller: hvac heating enabled left";
CM_ SG_ 524 VCRIGHT_hvacHeatingEnabledRight "Right body controller: hvac heating enabled right";
CM_ SG_ 524 VCRIGHT_hvacPerfTestState "The HVAC performance test running state";
CM_ SG_ 524 VCRIGHT_hvacUnavailable "Right body controller: hvac unavailable";
CM_ SG_ 524 VCRIGHT_hvacBlowerRPMActualAP "Right body controller: hvac blower RPM actual AP";
CM_ SG_ 524 VCRIGHT_hvacEvapEnabledInColdAmb "Right body controller: hvac evap enabled in cold ambient";
BA_DEF_ BO_ "GenMsgCycleTime" INT 0 3600000;
BA_DEF_ BO_ "GenMsgSendType" ENUM "Cyclic","NotUsed","NotUsed","NotUsed","NotUsed","NotUsed","NotUsed","IfActive","NoMsgSendType","NotUsed";
BA_DEF_ BO_ "VFrameFormat" ENUM "StandardCAN","ExtendedCAN","reserved","J1939PG","reserved","reserved","reserved","reserved","reserved","reserved","reserved","reserved","reserved","reserved","StandardCAN_FD","ExtendedCAN_FD";
BA_DEF_ BO_ "CANFD_BRS" ENUM "0","1";
BA_DEF_ SG_ "GenSigSNA" STRING;
BA_DEF_ SG_ "SystemSignalLongSymbol" STRING;
BA_DEF_ SG_ "Confidence" ENUM "validated","plausible","layout-only","contradicted";
BA_DEF_DEF_ "GenMsgCycleTime" 0;
BA_DEF_DEF_ "GenMsgSendType" "NoMsgSendType";
BA_DEF_DEF_ "VFrameFormat" "StandardCAN";
BA_DEF_DEF_ "CANFD_BRS" "1";
BA_DEF_DEF_ "GenSigSNA" "";
BA_DEF_DEF_ "SystemSignalLongSymbol" "";
BA_DEF_DEF_ "Confidence" "layout-only";
BA_ "GenMsgCycleTime" BO_ 994 200;
BA_ "GenMsgSendType" BO_ 994 0;
BA_ "GenMsgCycleTime" BO_ 1802 10000;
BA_ "GenMsgSendType" BO_ 1802 0;
BA_ "GenMsgCycleTime" BO_ 936 200;
BA_ "GenMsgSendType" BO_ 936 0;
BA_ "GenMsgCycleTime" BO_ 727 1000;
BA_ "GenMsgSendType" BO_ 727 0;
BA_ "GenMsgCycleTime" BO_ 1860 1000;
BA_ "GenMsgSendType" BO_ 1860 0;
BA_ "GenMsgCycleTime" BO_ 1250 100;
BA_ "GenMsgSendType" BO_ 1250 0;
BA_ "GenMsgCycleTime" BO_ 738 200;
BA_ "GenMsgSendType" BO_ 738 0;
BA_ "GenMsgCycleTime" BO_ 930 33;
BA_ "GenMsgSendType" BO_ 930 0;
BA_ "GenMsgCycleTime" BO_ 610 1000;
BA_ "GenMsgSendType" BO_ 610 0;
BA_ "GenMsgCycleTime" BO_ 962 50;
BA_ "GenMsgSendType" BO_ 962 0;
BA_ "GenMsgCycleTime" BO_ 656 20;
BA_ "GenMsgSendType" BO_ 656 0;
BA_ "GenMsgCycleTime" BO_ 657 500;
BA_ "GenMsgSendType" BO_ 657 0;
BA_ "GenMsgCycleTime" BO_ 386 100;
BA_ "GenMsgSendType" BO_ 386 0;
BA_ "GenMsgCycleTime" BO_ 706 100;
BA_ "GenMsgSendType" BO_ 706 0;
BA_ "GenMsgCycleTime" BO_ 549 100;
BA_ "GenMsgSendType" BO_ 549 0;
BA_ "GenMsgCycleTime" BO_ 643 100;
BA_ "GenMsgSendType" BO_ 643 0;
BA_ "GenMsgCycleTime" BO_ 1795 10;
BA_ "GenMsgSendType" BO_ 1795 0;
BA_ "GenMsgCycleTime" BO_ 291 100;
BA_ "GenMsgSendType" BO_ 291 0;
BA_ "GenMsgCycleTime" BO_ 915 100;
BA_ "GenMsgSendType" BO_ 915 0;
BA_ "GenMsgCycleTime" BO_ 524 100;
BA_ "GenMsgSendType" BO_ 524 0;
BA_ "Confidence" SG_ 994 VCLEFT_brakeLightStatus 0;
BA_ "GenSigSNA" SG_ 994 VCLEFT_brakeLightStatus "3";
BA_ "Confidence" SG_ 994 VCLEFT_tailLightStatus 0;
BA_ "GenSigSNA" SG_ 994 VCLEFT_tailLightStatus "3";
BA_ "Confidence" SG_ 994 VCLEFT_turnSignalStatus 0;
BA_ "GenSigSNA" SG_ 994 VCLEFT_turnSignalStatus "3";
BA_ "Confidence" SG_ 994 VCLEFT_FLMapLightStatus 0;
BA_ "GenSigSNA" SG_ 994 VCLEFT_FLMapLightStatus "3";
BA_ "Confidence" SG_ 994 VCLEFT_FRMapLightStatus 0;
BA_ "GenSigSNA" SG_ 994 VCLEFT_FRMapLightStatus "3";
BA_ "Confidence" SG_ 994 VCLEFT_RLMapLightStatus 0;
BA_ "GenSigSNA" SG_ 994 VCLEFT_RLMapLightStatus "3";
BA_ "Confidence" SG_ 994 VCLEFT_RRMapLightStatus 0;
BA_ "GenSigSNA" SG_ 994 VCLEFT_RRMapLightStatus "3";
BA_ "Confidence" SG_ 994 VCLEFT_FLMapLightSwitchPressed 0;
BA_ "Confidence" SG_ 994 VCLEFT_FRMapLightSwitchPressed 0;
BA_ "Confidence" SG_ 994 VCLEFT_RLMapLightSwitchPressed 0;
BA_ "Confidence" SG_ 994 VCLEFT_RRMapLightSwitchPressed 0;
BA_ "Confidence" SG_ 994 VCLEFT_leftTurnTrailerLightStatu 0;
BA_ "GenSigSNA" SG_ 994 VCLEFT_leftTurnTrailerLightStatu "3";
BA_ "SystemSignalLongSymbol" SG_ 994 VCLEFT_leftTurnTrailerLightStatu "VCLEFT_leftTurnTrailerLightStatus";
BA_ "Confidence" SG_ 994 VCLEFT_rightTrnTrailerLightStatu 0;
BA_ "GenSigSNA" SG_ 994 VCLEFT_rightTrnTrailerLightStatu "3";
BA_ "SystemSignalLongSymbol" SG_ 994 VCLEFT_rightTrnTrailerLightStatu "VCLEFT_rightTrnTrailerLightStatus";
BA_ "Confidence" SG_ 994 VCLEFT_brakeTrailerLightStatus 0;
BA_ "GenSigSNA" SG_ 994 VCLEFT_brakeTrailerLightStatus "3";
BA_ "Confidence" SG_ 994 VCLEFT_tailTrailerLightStatus 0;
BA_ "GenSigSNA" SG_ 994 VCLEFT_tailTrailerLightStatus "3";
BA_ "Confidence" SG_ 994 VCLEFT_fogTrailerLightStatus 0;
BA_ "GenSigSNA" SG_ 994 VCLEFT_fogTrailerLightStatus "3";
BA_ "Confidence" SG_ 994 VCLEFT_frontRideHeight 0;
BA_ "GenSigSNA" SG_ 994 VCLEFT_frontRideHeight "128";
BA_ "Confidence" SG_ 994 VCLEFT_rearRideHeight 0;
BA_ "GenSigSNA" SG_ 994 VCLEFT_rearRideHeight "128";
BA_ "Confidence" SG_ 994 VCLEFT_trailerDetected 0;
BA_ "GenSigSNA" SG_ 994 VCLEFT_trailerDetected "0";
BA_ "Confidence" SG_ 994 VCLEFT_rideHeightSensorFault 0;
BA_ "Confidence" SG_ 994 VCLEFT_reverseTrailerLightStatus 0;
BA_ "GenSigSNA" SG_ 994 VCLEFT_reverseTrailerLightStatus "3";
BA_ "Confidence" SG_ 994 VCLEFT_tailLightOutageStatus 0;
BA_ "Confidence" SG_ 994 VCLEFT_reverseLightStatus 0;
BA_ "GenSigSNA" SG_ 994 VCLEFT_reverseLightStatus "3";
BA_ "Confidence" SG_ 994 VCLEFT_thirdRowLeftMapLightSwitc 0;
BA_ "SystemSignalLongSymbol" SG_ 994 VCLEFT_thirdRowLeftMapLightSwitc "VCLEFT_thirdRowLeftMapLightSwitchPressed";
BA_ "Confidence" SG_ 994 VCLEFT_thirdRowRightMapLightSwit 0;
BA_ "SystemSignalLongSymbol" SG_ 994 VCLEFT_thirdRowRightMapLightSwit "VCLEFT_thirdRowRightMapLightSwitchPressed";
BA_ "Confidence" SG_ 1802 VCLEFT_logging0point1HzIndex 1;
BA_ "Confidence" SG_ 1802 VCLEFT_leftBrakeTailLightCurrent 0;
BA_ "GenSigSNA" SG_ 1802 VCLEFT_leftBrakeTailLightCurrent "511";
BA_ "Confidence" SG_ 1802 VCLEFT_leftBrakeTailLightCu_0001 0;
BA_ "GenSigSNA" SG_ 1802 VCLEFT_leftBrakeTailLightCu_0001 "0";
BA_ "SystemSignalLongSymbol" SG_ 1802 VCLEFT_leftBrakeTailLightCu_0001 "VCLEFT_leftBrakeTailLightCurrentSenseState";
BA_ "Confidence" SG_ 1802 VCLEFT_leftRearTurnLightCurrent 0;
BA_ "GenSigSNA" SG_ 1802 VCLEFT_leftRearTurnLightCurrent "511";
BA_ "Confidence" SG_ 1802 VCLEFT_leftRearTurnLightCurrentS 0;
BA_ "GenSigSNA" SG_ 1802 VCLEFT_leftRearTurnLightCurrentS "0";
BA_ "SystemSignalLongSymbol" SG_ 1802 VCLEFT_leftRearTurnLightCurrentS "VCLEFT_leftRearTurnLightCurrentSenseState";
BA_ "Confidence" SG_ 1802 VCLEFT_canAuthResyncDurationMs 0;
BA_ "Confidence" SG_ 936 VCLEFT_logging1HzIndex 1;
BA_ "Confidence" SG_ 936 VCLEFT_tohcPCBATemperature 0;
BA_ "GenSigSNA" SG_ 936 VCLEFT_tohcPCBATemperature "255";
BA_ "Confidence" SG_ 936 VCLEFT_phoneChargingFL 0;
BA_ "Confidence" SG_ 936 VCLEFT_phoneChargingFR 0;
BA_ "Confidence" SG_ 936 VCLEFT_swcResistance 0;
BA_ "GenSigSNA" SG_ 936 VCLEFT_swcResistance "127";
BA_ "Confidence" SG_ 936 VCLEFT_frontSeatHeatCushionPwr 0;
BA_ "Confidence" SG_ 936 VCLEFT_frontSeatHeatBackrestPwr 0;
BA_ "Confidence" SG_ 936 VCLEFT_rgbLedIPFLCurrent 0;
BA_ "Confidence" SG_ 936 VCLEFT_rgbLedIPFRCurrent 0;
BA_ "Confidence" SG_ 936 VCLEFT_rgbLedIPFLOutput 0;
BA_ "Confidence" SG_ 936 VCLEFT_rgbLedIPFROutput 0;
BA_ "Confidence" SG_ 936 VCLEFT_rgbLedFrontCurrent 0;
BA_ "Confidence" SG_ 936 VCLEFT_rgbLedRearCurrent 0;
BA_ "Confidence" SG_ 936 VCLEFT_rgbLedFrontOutput 0;
BA_ "Confidence" SG_ 936 VCLEFT_rgbLedRearOutput 0;
BA_ "Confidence" SG_ 936 VCLEFT_seat2RControllerCurrent 0;
BA_ "Confidence" SG_ 727 VCLEFT_pitchEstimateFusionState 0;
BA_ "Confidence" SG_ 727 VCLEFT_pitchEstimateStateTransit 0;
BA_ "SystemSignalLongSymbol" SG_ 727 VCLEFT_pitchEstimateStateTransit "VCLEFT_pitchEstimateStateTransitionID";
BA_ "Confidence" SG_ 727 VCLEFT_pitchEstimateArbitratedSt 0;
BA_ "SystemSignalLongSymbol" SG_ 727 VCLEFT_pitchEstimateArbitratedSt "VCLEFT_pitchEstimateArbitratedState";
BA_ "Confidence" SG_ 727 VCLEFT_pitchEstimateOKForAiming 0;
BA_ "Confidence" SG_ 727 VCLEFT_pitchEstimateFusionRaw 0;
BA_ "Confidence" SG_ 727 VCLEFT_pitchEstimate 0;
BA_ "GenSigSNA" SG_ 727 VCLEFT_pitchEstimate "512";
BA_ "Confidence" SG_ 1860 VCLEFT_systemRecallStatus 0;
BA_ "GenSigSNA" SG_ 1860 VCLEFT_systemRecallStatus "0";
BA_ "Confidence" SG_ 1860 VCLEFT_seatRecallStatus 0;
BA_ "GenSigSNA" SG_ 1860 VCLEFT_seatRecallStatus "0";
BA_ "Confidence" SG_ 1860 VCLEFT_columnRecallStatus 0;
BA_ "GenSigSNA" SG_ 1860 VCLEFT_columnRecallStatus "0";
BA_ "Confidence" SG_ 1860 VCLEFT_mirrorRecallStatus 0;
BA_ "GenSigSNA" SG_ 1860 VCLEFT_mirrorRecallStatus "0";
BA_ "Confidence" SG_ 1250 VCLEFT_seatStatusIndex 1;
BA_ "Confidence" SG_ 1250 VC_AH_1RowLeftSeatMovementHealth 0;
BA_ "Confidence" SG_ 1250 VCLEFT_frontSeatTrackPos 0;
BA_ "Confidence" SG_ 1250 VCLEFT_frontSeatTrackCurrent 0;
BA_ "Confidence" SG_ 1250 VCLEFT_frontSeatTrackDuty 0;
BA_ "Confidence" SG_ 1250 VCLEFT_frontSeatTrackState 0;
BA_ "Confidence" SG_ 1250 VCLEFT_frontSeatTrackCalibrated 0;
BA_ "Confidence" SG_ 1250 VCLEFT_frontSeatTrackLog 0;
BA_ "Confidence" SG_ 1250 VCLEFT_frontSeatTrackBridgeSt 0;
BA_ "Confidence" SG_ 1250 VCLEFT_frontSeatTrackPercentage 0;
BA_ "Confidence" SG_ 1250 VCLEFT_frontSeatBackPos 0;
BA_ "Confidence" SG_ 1250 VCLEFT_frontSeatBackCurrent 0;
BA_ "Confidence" SG_ 1250 VCLEFT_frontSeatBackDuty 0;
BA_ "Confidence" SG_ 1250 VCLEFT_frontSeatBackState 0;
BA_ "Confidence" SG_ 1250 VCLEFT_frontSeatBackCalibrated 0;
BA_ "Confidence" SG_ 1250 VCLEFT_frontSeatBackLog 0;
BA_ "Confidence" SG_ 1250 VCLEFT_frontSeatBackBridgeSt 0;
BA_ "Confidence" SG_ 1250 VCLEFT_frontSeatBackPercentage 0;
BA_ "Confidence" SG_ 1250 VCLEFT_frontSeatLiftPos 0;
BA_ "Confidence" SG_ 1250 VCLEFT_frontSeatLiftCurrent 0;
BA_ "Confidence" SG_ 1250 VCLEFT_frontSeatLiftDuty 0;
BA_ "Confidence" SG_ 1250 VCLEFT_frontSeatLiftState 0;
BA_ "Confidence" SG_ 1250 VCLEFT_frontSeatLiftCalibrated 0;
BA_ "Confidence" SG_ 1250 VCLEFT_frontSeatLiftLog 0;
BA_ "Confidence" SG_ 1250 VCLEFT_frontSeatLiftBridgeSt 0;
BA_ "Confidence" SG_ 1250 VCLEFT_frontSeatLiftPercentage 0;
BA_ "Confidence" SG_ 1250 VCLEFT_frontSeatTiltPos 0;
BA_ "Confidence" SG_ 1250 VCLEFT_frontSeatTiltCurrent 0;
BA_ "Confidence" SG_ 1250 VCLEFT_frontSeatTiltDuty 0;
BA_ "Confidence" SG_ 1250 VCLEFT_frontSeatTiltState 0;
BA_ "Confidence" SG_ 1250 VCLEFT_frontSeatTiltCalibrated 0;
BA_ "Confidence" SG_ 1250 VCLEFT_frontSeatTiltLog 0;
BA_ "Confidence" SG_ 1250 VCLEFT_frontSeatTiltBridgeSt 0;
BA_ "Confidence" SG_ 1250 VCLEFT_frontSeatTiltPercentage 0;
BA_ "Confidence" SG_ 1250 VCLEFT_lumbarAState 0;
BA_ "Confidence" SG_ 1250 VCLEFT_lumbarBState 0;
BA_ "Confidence" SG_ 1250 VCLEFT_lumbarAPressureHpa 0;
BA_ "Confidence" SG_ 1250 VCLEFT_lumbarAPressureHpaFilt 0;
BA_ "Confidence" SG_ 1250 VCLEFT_lumbarBPressureHpa 0;
BA_ "Confidence" SG_ 1250 VCLEFT_lumbarBPressureHpaFilt 0;
BA_ "Confidence" SG_ 1250 VCLEFT_lumbarActiveTooLongErr 0;
BA_ "Confidence" SG_ 1250 VCLEFT_lumbarMaxPErr 0;
BA_ "Confidence" SG_ 1250 VCLEFT_lumbarOvercurrentErr 0;
BA_ "Confidence" SG_ 1250 VCLEFT_lumbarMaxOperatingPErr 0;
BA_ "Confidence" SG_ 1250 VCLEFT_lumbarMinPErr 0;
BA_ "Confidence" SG_ 1250 VCLEFT_lumbarGeneralErr 0;
BA_ "Confidence" SG_ 1250 VCLEFT_lumbarDevMaxPumpPressA 0;
BA_ "Confidence" SG_ 1250 VCLEFT_lumbarDevMaxPumpPressB 0;
BA_ "Confidence" SG_ 1250 VCLEFT_frontSeatTrackPosReal 0;
BA_ "Confidence" SG_ 1250 VCLEFT_frontSeatBackPosReal 0;
BA_ "Confidence" SG_ 1250 VCLEFT_frontSeatLiftPosReal 0;
BA_ "Confidence" SG_ 1250 VCLEFT_frontSeatTiltPosReal 0;
BA_ "Confidence" SG_ 1250 VCLEFT_frontSeatThighSupportPosR 0;
BA_ "SystemSignalLongSymbol" SG_ 1250 VCLEFT_frontSeatThighSupportPosR "VCLEFT_frontSeatThighSupportPosReal";
BA_ "Confidence" SG_ 1250 VCLEFT_frontSeatTrackPosOffset 0;
BA_ "Confidence" SG_ 1250 VCLEFT_frontSeatBackPosOffset 0;
BA_ "Confidence" SG_ 1250 VCLEFT_frontSeatLiftPosOffset 0;
BA_ "Confidence" SG_ 1250 VCLEFT_frontSeatTiltPosOffset 0;
BA_ "Confidence" SG_ 1250 VCLEFT_frontSeatThighSupportPosO 0;
BA_ "SystemSignalLongSymbol" SG_ 1250 VCLEFT_frontSeatThighSupportPosO "VCLEFT_frontSeatThighSupportPosOffset";
BA_ "Confidence" SG_ 1250 VCLEFT_lumbarAPressurePercentage 0;
BA_ "Confidence" SG_ 1250 VCLEFT_lumbarBPressurePercentage 0;
BA_ "Confidence" SG_ 738 VCLEFT_seatStatus2Index 1;
BA_ "Confidence" SG_ 738 VCLEFT_frontSeatHeatCurrent 0;
BA_ "GenSigSNA" SG_ 738 VCLEFT_frontSeatHeatCurrent "12";
BA_ "Confidence" SG_ 738 VCLEFT_frontSeatHeatDuty 0;
BA_ "Confidence" SG_ 738 VCLEFT_frontSeatHeatTmp 0;
BA_ "Confidence" SG_ 738 VCLEFT_frontSeatHeatTmpTarget 0;
BA_ "Confidence" SG_ 738 VCLEFT_frontSeatHeatInhibited 0;
BA_ "Confidence" SG_ 738 VCLEFT_frontSeatHeatPowered 0;
BA_ "Confidence" SG_ 738 VCLEFT_2RowSeatFoldLeftSwitch 0;
BA_ "GenSigSNA" SG_ 738 VCLEFT_2RowSeatFoldLeftSwitch "0";
BA_ "Confidence" SG_ 738 VCLEFT_2RowSeatUnfoldLeftSwitch 0;
BA_ "GenSigSNA" SG_ 738 VCLEFT_2RowSeatUnfoldLeftSwitch "0";
BA_ "Confidence" SG_ 738 VCLEFT_2RowSeatFoldRightSwitch 0;
BA_ "GenSigSNA" SG_ 738 VCLEFT_2RowSeatFoldRightSwitch "0";
BA_ "Confidence" SG_ 738 VCLEFT_2RowSeatUnfoldRightSwitch 0;
BA_ "GenSigSNA" SG_ 738 VCLEFT_2RowSeatUnfoldRightSwitch "0";
BA_ "Confidence" SG_ 738 VCLEFT_3RowSeatFoldLeftSwitch 0;
BA_ "GenSigSNA" SG_ 738 VCLEFT_3RowSeatFoldLeftSwitch "0";
BA_ "Confidence" SG_ 738 VCLEFT_3RowSeatUnfoldLeftSwitch 0;
BA_ "GenSigSNA" SG_ 738 VCLEFT_3RowSeatUnfoldLeftSwitch "0";
BA_ "Confidence" SG_ 738 VCLEFT_3RowSeatFoldRightSwitch 0;
BA_ "GenSigSNA" SG_ 738 VCLEFT_3RowSeatFoldRightSwitch "0";
BA_ "Confidence" SG_ 738 VCLEFT_3RowSeatUnfoldRightSwitch 0;
BA_ "GenSigSNA" SG_ 738 VCLEFT_3RowSeatUnfoldRightSwitch "0";
BA_ "Confidence" SG_ 738 VC_AH_1RowLeftSeatHeatVentHealth 0;
BA_ "Confidence" SG_ 738 VCLEFT_2RowSeatReclineState 0;
BA_ "GenSigSNA" SG_ 738 VCLEFT_2RowSeatReclineState "15";
BA_ "Confidence" SG_ 738 VCLEFT_2RowSeatReclineDuty 0;
BA_ "Confidence" SG_ 738 VCLEFT_2RowSeatReclineCurrent 0;
BA_ "Confidence" SG_ 738 VCLEFT_2RowSeatReclineCalibrated 0;
BA_ "Confidence" SG_ 738 VCLEFT_2RowSeatReclinePositionRa 0;
BA_ "SystemSignalLongSymbol" SG_ 738 VCLEFT_2RowSeatReclinePositionRa "VCLEFT_2RowSeatReclinePositionRaw";
BA_ "Confidence" SG_ 738 VCLEFT_2RowSeatReclineAngle 0;
BA_ "Confidence" SG_ 738 VCLEFT_2RowSeatReclineAbsPosSwit 0;
BA_ "GenSigSNA" SG_ 738 VCLEFT_2RowSeatReclineAbsPosSwit "0";
BA_ "SystemSignalLongSymbol" SG_ 738 VCLEFT_2RowSeatReclineAbsPosSwit "VCLEFT_2RowSeatReclineAbsPosSwitchState";
BA_ "Confidence" SG_ 738 VCLEFT_2RowSeatReclinePositionSt 0;
BA_ "GenSigSNA" SG_ 738 VCLEFT_2RowSeatReclinePositionSt "4";
BA_ "SystemSignalLongSymbol" SG_ 738 VCLEFT_2RowSeatReclinePositionSt "VCLEFT_2RowSeatReclinePositionState";
BA_ "Confidence" SG_ 738 VCLEFT_2RowSeatReclineAdjustment 0;
BA_ "SystemSignalLongSymbol" SG_ 738 VCLEFT_2RowSeatReclineAdjustment "VCLEFT_2RowSeatReclineAdjustmentAllowed";
BA_ "Confidence" SG_ 738 VCLEFT_2RowSeatReclineFoldAllowe 0;
BA_ "SystemSignalLongSymbol" SG_ 738 VCLEFT_2RowSeatReclineFoldAllowe "VCLEFT_2RowSeatReclineFoldAllowed";
BA_ "Confidence" SG_ 738 VCLEFT_2RowSeatReclineUnfoldAllo 0;
BA_ "SystemSignalLongSymbol" SG_ 738 VCLEFT_2RowSeatReclineUnfoldAllo "VCLEFT_2RowSeatReclineUnfoldAllowed";
BA_ "Confidence" SG_ 738 VCLEFT_2RowSeatReclineNextToggle 0;
BA_ "GenSigSNA" SG_ 738 VCLEFT_2RowSeatReclineNextToggle "2";
BA_ "SystemSignalLongSymbol" SG_ 738 VCLEFT_2RowSeatReclineNextToggle "VCLEFT_2RowSeatReclineNextToggleDirection";
BA_ "Confidence" SG_ 738 VCLEFT_2RowSeatReclineChoreoBloc 0;
BA_ "SystemSignalLongSymbol" SG_ 738 VCLEFT_2RowSeatReclineChoreoBloc "VCLEFT_2RowSeatReclineChoreoBlockedByOccupancy";
BA_ "Confidence" SG_ 738 VCLEFT_2RowSeat1RClashAvoidanceB 0;
BA_ "SystemSignalLongSymbol" SG_ 738 VCLEFT_2RowSeat1RClashAvoidanceB "VCLEFT_2RowSeat1RClashAvoidanceBlockedReason";
BA_ "Confidence" SG_ 738 VCLEFT_2RowSeat1RClashAvoidanceS 0;
BA_ "SystemSignalLongSymbol" SG_ 738 VCLEFT_2RowSeat1RClashAvoidanceS "VCLEFT_2RowSeat1RClashAvoidanceState";
BA_ "Confidence" SG_ 738 VCLEFT_2RowSeatReclineAbsPo_0001 0;
BA_ "SystemSignalLongSymbol" SG_ 738 VCLEFT_2RowSeatReclineAbsPo_0001 "VCLEFT_2RowSeatReclineAbsPosSwitchTransPoint";
BA_ "Confidence" SG_ 738 VC_AH_2RowLeftSeatMovementHealth 0;
BA_ "Confidence" SG_ 738 VCLEFT_3RowSeatReclineState 0;
BA_ "GenSigSNA" SG_ 738 VCLEFT_3RowSeatReclineState "15";
BA_ "Confidence" SG_ 738 VCLEFT_3RowSeatReclineDuty 0;
BA_ "Confidence" SG_ 738 VCLEFT_3RowSeatReclineCurrent 0;
BA_ "Confidence" SG_ 738 VCLEFT_3RowSeatReclineCalibrated 0;
BA_ "Confidence" SG_ 738 VCLEFT_3RowSeatReclinePositionRa 0;
BA_ "SystemSignalLongSymbol" SG_ 738 VCLEFT_3RowSeatReclinePositionRa "VCLEFT_3RowSeatReclinePositionRaw";
BA_ "Confidence" SG_ 738 VCLEFT_3RowSeatReclineAngle 0;
BA_ "Confidence" SG_ 738 VCLEFT_3RowSeatReclineNextToggle 0;
BA_ "GenSigSNA" SG_ 738 VCLEFT_3RowSeatReclineNextToggle "2";
BA_ "SystemSignalLongSymbol" SG_ 738 VCLEFT_3RowSeatReclineNextToggle "VCLEFT_3RowSeatReclineNextToggleDirection";
BA_ "Confidence" SG_ 738 VCLEFT_3RRightCushionHeatCurrent 0;
BA_ "Confidence" SG_ 738 VCLEFT_3RRightCushionHeatDuty 0;
BA_ "Confidence" SG_ 738 VCLEFT_3RRightCushionHeatTmp 0;
BA_ "Confidence" SG_ 738 VCLEFT_3RRightCushionHeatTmpTarg 0;
BA_ "SystemSignalLongSymbol" SG_ 738 VCLEFT_3RRightCushionHeatTmpTarg "VCLEFT_3RRightCushionHeatTmpTarget";
BA_ "Confidence" SG_ 738 VCLEFT_3RRightCushionHeatInhibit 0;
BA_ "SystemSignalLongSymbol" SG_ 738 VCLEFT_3RRightCushionHeatInhibit "VCLEFT_3RRightCushionHeatInhibited";
BA_ "Confidence" SG_ 738 VCLEFT_3RowSeatReclinePositionSt 0;
BA_ "GenSigSNA" SG_ 738 VCLEFT_3RowSeatReclinePositionSt "4";
BA_ "SystemSignalLongSymbol" SG_ 738 VCLEFT_3RowSeatReclinePositionSt "VCLEFT_3RowSeatReclinePositionState";
BA_ "Confidence" SG_ 738 VCLEFT_3RowSeatReclineAdjustment 0;
BA_ "SystemSignalLongSymbol" SG_ 738 VCLEFT_3RowSeatReclineAdjustment "VCLEFT_3RowSeatReclineAdjustmentAllowed";
BA_ "Confidence" SG_ 738 VCLEFT_3RowSeatReclineFoldAllowe 0;
BA_ "SystemSignalLongSymbol" SG_ 738 VCLEFT_3RowSeatReclineFoldAllowe "VCLEFT_3RowSeatReclineFoldAllowed";
BA_ "Confidence" SG_ 738 VCLEFT_3RowSeatReclineUnfoldAllo 0;
BA_ "SystemSignalLongSymbol" SG_ 738 VCLEFT_3RowSeatReclineUnfoldAllo "VCLEFT_3RowSeatReclineUnfoldAllowed";
BA_ "Confidence" SG_ 738 VCLEFT_3RowSeatReclineChoreoBloc 0;
BA_ "SystemSignalLongSymbol" SG_ 738 VCLEFT_3RowSeatReclineChoreoBloc "VCLEFT_3RowSeatReclineChoreoBlockedByOccupancy";
BA_ "Confidence" SG_ 738 VCLEFT_3RowSeatReclineAbsPosSwit 0;
BA_ "GenSigSNA" SG_ 738 VCLEFT_3RowSeatReclineAbsPosSwit "0";
BA_ "SystemSignalLongSymbol" SG_ 738 VCLEFT_3RowSeatReclineAbsPosSwit "VCLEFT_3RowSeatReclineAbsPosSwitchState";
BA_ "Confidence" SG_ 930 VCLEFT_statusIndex 1;
BA_ "Confidence" SG_ 930 VCLEFT_securityControllerEnable 0;
BA_ "Confidence" SG_ 930 VCLEFT_securityControllerVoltage 0;
BA_ "Confidence" SG_ 930 VCLEFT_consoleDoorAssist 0;
BA_ "Confidence" SG_ 930 VCLEFT_OTAState 0;
BA_ "Confidence" SG_ 930 VCLEFT_5AVoltage 0;
BA_ "Confidence" SG_ 930 VCLEFT_vbatProt 0;
BA_ "Confidence" SG_ 930 VCLEFT_footwellLightCurrent 0;
BA_ "Confidence" SG_ 930 VCLEFT_swcInputVoltage 0;
BA_ "GenSigSNA" SG_ 930 VCLEFT_swcInputVoltage "255";
BA_ "Confidence" SG_ 930 VCLEFT_swcPCBATemperature 0;
BA_ "GenSigSNA" SG_ 930 VCLEFT_swcPCBATemperature "128";
BA_ "Confidence" SG_ 930 VCLEFT_obdEthernetActive 0;
BA_ "Confidence" SG_ 930 VCLEFT_rationalityAggregateCurre 0;
BA_ "SystemSignalLongSymbol" SG_ 930 VCLEFT_rationalityAggregateCurre "VCLEFT_rationalityAggregateCurrent";
BA_ "Confidence" SG_ 930 VCLEFT_LVBatteryTypeDBG 0;
BA_ "Confidence" SG_ 930 VCLEFT_DIeFuseFault 0;
BA_ "Confidence" SG_ 930 VCLEFT_eFuseMgmtVoltageMonitor 0;
BA_ "Confidence" SG_ 930 VCLEFT_trailerAuxCurrent 0;
BA_ "GenSigSNA" SG_ 930 VCLEFT_trailerAuxCurrent "4095";
BA_ "Confidence" SG_ 930 VCLEFT_swcHeatTmp 0;
BA_ "GenSigSNA" SG_ 930 VCLEFT_swcHeatTmp "1023";
BA_ "Confidence" SG_ 930 VCLEFT_swcHeatStatus 0;
BA_ "GenSigSNA" SG_ 930 VCLEFT_swcHeatStatus "0";
BA_ "Confidence" SG_ 930 VCLEFT_swcHeatInhibited 0;
BA_ "Confidence" SG_ 930 VCLEFT_obdDeviceDetected 0;
BA_ "Confidence" SG_ 930 VCLEFT_pcbaTemperature 0;
BA_ "Confidence" SG_ 930 VCLEFT_swcHeatPwr 0;
BA_ "GenSigSNA" SG_ 930 VCLEFT_swcHeatPwr "511";
BA_ "Confidence" SG_ 930 VCLEFT_swcHeatDutyCycle 0;
BA_ "GenSigSNA" SG_ 930 VCLEFT_swcHeatDutyCycle "127";
BA_ "Confidence" SG_ 930 VCLEFT_DIeFuseCurrent 0;
BA_ "Confidence" SG_ 930 VCLEFT_SWCpresent 0;
BA_ "Confidence" SG_ 930 VCLEFT_autonomyBehaviorStatus 0;
BA_ "Confidence" SG_ 930 VCLEFT_thirdRowLeftMapLightStatu 0;
BA_ "GenSigSNA" SG_ 930 VCLEFT_thirdRowLeftMapLightStatu "3";
BA_ "SystemSignalLongSymbol" SG_ 930 VCLEFT_thirdRowLeftMapLightStatu "VCLEFT_thirdRowLeftMapLightStatus";
BA_ "Confidence" SG_ 930 VCLEFT_thirdRowRightMapLightStat 0;
BA_ "GenSigSNA" SG_ 930 VCLEFT_thirdRowRightMapLightStat "3";
BA_ "SystemSignalLongSymbol" SG_ 930 VCLEFT_thirdRowRightMapLightStat "VCLEFT_thirdRowRightMapLightStatus";
BA_ "Confidence" SG_ 610 VCLEFT_steeringColumnSMState 0;
BA_ "GenSigSNA" SG_ 610 VCLEFT_steeringColumnSMState "0";
BA_ "Confidence" SG_ 610 VCLEFT_steeringColumnLastRequest 0;
BA_ "GenSigSNA" SG_ 610 VCLEFT_steeringColumnLastRequest "0";
BA_ "Confidence" SG_ 610 VCLEFT_steeringColumnUpDownDuty 0;
BA_ "Confidence" SG_ 610 VCLEFT_steeringColumnInOutDuty 0;
BA_ "Confidence" SG_ 610 VCLEFT_steeringColumnUpDownPos 0;
BA_ "Confidence" SG_ 610 VCLEFT_steeringColumnInOutPos 0;
BA_ "Confidence" SG_ 610 VCLEFT_steeringColumnUpDownAmps 0;
BA_ "Confidence" SG_ 610 VCLEFT_steeringColumnInOutAmps 0;
BA_ "Confidence" SG_ 610 VCLEFT_steeringColumnUpDownCalib 0;
BA_ "Confidence" SG_ 610 VCLEFT_steeringColumnInOutCalib 0;
BA_ "Confidence" SG_ 610 VCLEFT_steeringColumnUpDownTC 0;
BA_ "Confidence" SG_ 610 VCLEFT_steeringColumnInOutTC 0;
BA_ "Confidence" SG_ 962 VCLEFT_switchStatusIndex 1;
BA_ "Confidence" SG_ 962 VCLEFT_hornSwitchPressed 0;
BA_ "Confidence" SG_ 962 VCLEFT_hazardButtonPressed 0;
BA_ "Confidence" SG_ 962 VCLEFT_brakeSwitchPressed 0;
BA_ "Confidence" SG_ 962 VCLEFT_rightMirrorTilt 0;
BA_ "Confidence" SG_ 962 VCLEFT_frontSeatTrackBack 0;
BA_ "GenSigSNA" SG_ 962 VCLEFT_frontSeatTrackBack "0";
BA_ "Confidence" SG_ 962 VCLEFT_frontSeatTrackForward 0;
BA_ "GenSigSNA" SG_ 962 VCLEFT_frontSeatTrackForward "0";
BA_ "Confidence" SG_ 962 VCLEFT_frontSeatTiltDown 0;
BA_ "GenSigSNA" SG_ 962 VCLEFT_frontSeatTiltDown "0";
BA_ "Confidence" SG_ 962 VCLEFT_frontSeatTiltUp 0;
BA_ "GenSigSNA" SG_ 962 VCLEFT_frontSeatTiltUp "0";
BA_ "Confidence" SG_ 962 VCLEFT_frontSeatLiftDown 0;
BA_ "GenSigSNA" SG_ 962 VCLEFT_frontSeatLiftDown "0";
BA_ "Confidence" SG_ 962 VCLEFT_frontSeatLiftUp 0;
BA_ "GenSigSNA" SG_ 962 VCLEFT_frontSeatLiftUp "0";
BA_ "Confidence" SG_ 962 VCLEFT_frontSeatBackrestBack 0;
BA_ "GenSigSNA" SG_ 962 VCLEFT_frontSeatBackrestBack "0";
BA_ "Confidence" SG_ 962 VCLEFT_frontSeatBackrestForward 0;
BA_ "GenSigSNA" SG_ 962 VCLEFT_frontSeatBackrestForward "0";
BA_ "Confidence" SG_ 962 VCLEFT_frontSeatLumbarDown 0;
BA_ "GenSigSNA" SG_ 962 VCLEFT_frontSeatLumbarDown "0";
BA_ "Confidence" SG_ 962 VCLEFT_frontSeatLumbarUp 0;
BA_ "GenSigSNA" SG_ 962 VCLEFT_frontSeatLumbarUp "0";
BA_ "Confidence" SG_ 962 VCLEFT_frontSeatLumbarIn 0;
BA_ "GenSigSNA" SG_ 962 VCLEFT_frontSeatLumbarIn "0";
BA_ "Confidence" SG_ 962 VCLEFT_frontSeatLumbarOut 0;
BA_ "GenSigSNA" SG_ 962 VCLEFT_frontSeatLumbarOut "0";
BA_ "Confidence" SG_ 962 VCLEFT_btnWindowSwPackUpLF 0;
BA_ "Confidence" SG_ 962 VCLEFT_btnWindowSwPackAutoUpLF 0;
BA_ "Confidence" SG_ 962 VCLEFT_btnWindowSwPackDownLF 0;
BA_ "Confidence" SG_ 962 VCLEFT_btnWindowSwPackAutoDownLF 0;
BA_ "Confidence" SG_ 962 VCLEFT_btnWindowSwPackUpLR 0;
BA_ "Confidence" SG_ 962 VCLEFT_btnWindowSwPackAutoUpLR 0;
BA_ "Confidence" SG_ 962 VCLEFT_btnWindowSwPackDownLR 0;
BA_ "Confidence" SG_ 962 VCLEFT_btnWindowSwPackAutoDownLR 0;
BA_ "Confidence" SG_ 962 VCLEFT_btnWindowSwPackUpRF 0;
BA_ "Confidence" SG_ 962 VCLEFT_btnWindowSwPackAutoUpRF 0;
BA_ "Confidence" SG_ 962 VCLEFT_btnWindowSwPackDownRF 0;
BA_ "Confidence" SG_ 962 VCLEFT_btnWindowSwPackAutoDownRF 0;
BA_ "Confidence" SG_ 962 VCLEFT_btnWindowSwPackUpRR 0;
BA_ "Confidence" SG_ 962 VCLEFT_btnWindowSwPackAutoUpRR 0;
BA_ "Confidence" SG_ 962 VCLEFT_btnWindowSwPackDownRR 0;
BA_ "Confidence" SG_ 962 VCLEFT_btnWindowSwPackAutoDownRR 0;
BA_ "Confidence" SG_ 962 VCLEFT_frontBuckleSwitch 0;
BA_ "GenSigSNA" SG_ 962 VCLEFT_frontBuckleSwitch "0";
BA_ "Confidence" SG_ 962 VCLEFT_frontOccupancySwitch 0;
BA_ "GenSigSNA" SG_ 962 VCLEFT_frontOccupancySwitch "0";
BA_ "Confidence" SG_ 962 VCLEFT_rearLeftBuckleSwitch 0;
BA_ "GenSigSNA" SG_ 962 VCLEFT_rearLeftBuckleSwitch "0";
BA_ "Confidence" SG_ 962 VCLEFT_rearCenterOccupancySwitch 0;
BA_ "GenSigSNA" SG_ 962 VCLEFT_rearCenterOccupancySwitch "0";
BA_ "Confidence" SG_ 962 VCLEFT_rearLeftOccupancySwitch 0;
BA_ "GenSigSNA" SG_ 962 VCLEFT_rearLeftOccupancySwitch "0";
BA_ "Confidence" SG_ 962 VCLEFT_rearRightOccupancySwitch 0;
BA_ "GenSigSNA" SG_ 962 VCLEFT_rearRightOccupancySwitch "0";
BA_ "Confidence" SG_ 962 VCLEFT_brakePressed 0;
BA_ "Confidence" SG_ 962 VCLEFT_rearHVACButtonPressed 0;
BA_ "Confidence" SG_ 962 VCLEFT_rearCenterBuckleSwitch 0;
BA_ "GenSigSNA" SG_ 962 VCLEFT_rearCenterBuckleSwitch "0";
BA_ "Confidence" SG_ 962 VCLEFT_isAlcoholInterlockSet 0;
BA_ "Confidence" SG_ 962 VCLEFT_swcLeftTiltRight 0;
BA_ "GenSigSNA" SG_ 962 VCLEFT_swcLeftTiltRight "0";
BA_ "Confidence" SG_ 962 VCLEFT_swcLeftPressed 0;
BA_ "GenSigSNA" SG_ 962 VCLEFT_swcLeftPressed "0";
BA_ "Confidence" SG_ 962 VCLEFT_swcRightTiltLeft 0;
BA_ "GenSigSNA" SG_ 962 VCLEFT_swcRightTiltLeft "0";
BA_ "Confidence" SG_ 962 VCLEFT_swcRightTiltRight 0;
BA_ "GenSigSNA" SG_ 962 VCLEFT_swcRightTiltRight "0";
BA_ "Confidence" SG_ 962 VCLEFT_swcRightPressed 0;
BA_ "GenSigSNA" SG_ 962 VCLEFT_swcRightPressed "0";
BA_ "Confidence" SG_ 962 VCLEFT_swcLeftTiltLeft 0;
BA_ "GenSigSNA" SG_ 962 VCLEFT_swcLeftTiltLeft "0";
BA_ "Confidence" SG_ 962 VCLEFT_swcLeftScrollTicks 0;
BA_ "Confidence" SG_ 962 VCLEFT_swcWiperButtonState 0;
BA_ "Confidence" SG_ 962 VCLEFT_swcRightScrollTicks 0;
BA_ "Confidence" SG_ 962 VCLEFT_swcTurnSignalLeftButtonSt 0;
BA_ "SystemSignalLongSymbol" SG_ 962 VCLEFT_swcTurnSignalLeftButtonSt "VCLEFT_swcTurnSignalLeftButtonState";
BA_ "Confidence" SG_ 962 VCLEFT_btnWindowUpLR 0;
BA_ "Confidence" SG_ 962 VCLEFT_btnWindowAutoUpLR 0;
BA_ "Confidence" SG_ 962 VCLEFT_btnWindowDownLR 0;
BA_ "Confidence" SG_ 962 VCLEFT_btnWindowAutoDownLR 0;
BA_ "Confidence" SG_ 962 VCLEFT_2RowSeatLeftFoldFlatSwitc 0;
BA_ "SystemSignalLongSymbol" SG_ 962 VCLEFT_2RowSeatLeftFoldFlatSwitc "VCLEFT_2RowSeatLeftFoldFlatSwitch";
BA_ "Confidence" SG_ 962 VCLEFT_2RowSeatRightFoldFlatSwit 0;
BA_ "SystemSignalLongSymbol" SG_ 962 VCLEFT_2RowSeatRightFoldFlatSwit "VCLEFT_2RowSeatRightFoldFlatSwitch";
BA_ "Confidence" SG_ 962 VCLEFT_2RowSeatBothFoldFlatSwitc 0;
BA_ "SystemSignalLongSymbol" SG_ 962 VCLEFT_2RowSeatBothFoldFlatSwitc "VCLEFT_2RowSeatBothFoldFlatSwitch";
BA_ "Confidence" SG_ 962 VCLEFT_swcLeftDoublePress 0;
BA_ "Confidence" SG_ 962 VCLEFT_swcRightDoublePress 0;
BA_ "Confidence" SG_ 962 VCLEFT_swcTurnSignalRightButtonS 0;
BA_ "SystemSignalLongSymbol" SG_ 962 VCLEFT_swcTurnSignalRightButtonS "VCLEFT_swcTurnSignalRightButtonState";
BA_ "Confidence" SG_ 962 VCLEFT_swcHighBeamButtonState 0;
BA_ "Confidence" SG_ 962 VCLEFT_swcVoiceControlPress 0;
BA_ "GenSigSNA" SG_ 962 VCLEFT_swcVoiceControlPress "0";
BA_ "Confidence" SG_ 962 VCLEFT_swcCameraButtonState 0;
BA_ "Confidence" SG_ 962 VCLEFT_swcRightPressedQF 0;
BA_ "Confidence" SG_ 962 VCLEFT_frontSeatResistiveOccupan 0;
BA_ "GenSigSNA" SG_ 962 VCLEFT_frontSeatResistiveOccupan "0";
BA_ "SystemSignalLongSymbol" SG_ 962 VCLEFT_frontSeatResistiveOccupan "VCLEFT_frontSeatResistiveOccupancy";
BA_ "Confidence" SG_ 656 VCLEFT_thermalLogging10HzIndex 1;
BA_ "Confidence" SG_ 656 VCLEFT_hvac2RLeftLateralVoltage 0;
BA_ "Confidence" SG_ 656 VCLEFT_hvac2RLeftVerticalVoltage 0;
BA_ "Confidence" SG_ 656 VCLEFT_hvac2RRightLateralVoltage 0;
BA_ "Confidence" SG_ 656 VCLEFT_hvac2RRightVerticalVoltag 0;
BA_ "SystemSignalLongSymbol" SG_ 656 VCLEFT_hvac2RRightVerticalVoltag "VCLEFT_hvac2RRightVerticalVoltage";
BA_ "Confidence" SG_ 656 VCLEFT_hvac2RLeftLateralCalibrat 0;
BA_ "SystemSignalLongSymbol" SG_ 656 VCLEFT_hvac2RLeftLateralCalibrat "VCLEFT_hvac2RLeftLateralCalibrated";
BA_ "Confidence" SG_ 656 VCLEFT_hvac2RLeftVerticalCalibra 0;
BA_ "SystemSignalLongSymbol" SG_ 656 VCLEFT_hvac2RLeftVerticalCalibra "VCLEFT_hvac2RLeftVerticalCalibrated";
BA_ "Confidence" SG_ 656 VCLEFT_hvac2RRightLateralCalibra 0;
BA_ "SystemSignalLongSymbol" SG_ 656 VCLEFT_hvac2RRightLateralCalibra "VCLEFT_hvac2RRightLateralCalibrated";
BA_ "Confidence" SG_ 656 VCLEFT_hvac2RRightVerticalCalibr 0;
BA_ "SystemSignalLongSymbol" SG_ 656 VCLEFT_hvac2RRightVerticalCalibr "VCLEFT_hvac2RRightVerticalCalibrated";
BA_ "Confidence" SG_ 656 VCLEFT_hvac2RLeftLateralState 0;
BA_ "Confidence" SG_ 656 VCLEFT_hvac2RLeftVerticalState 0;
BA_ "Confidence" SG_ 656 VCLEFT_hvac2RRightLateralState 0;
BA_ "Confidence" SG_ 656 VCLEFT_hvac2RRightVerticalState 0;
BA_ "Confidence" SG_ 656 VCLEFT_hvacBlowerWindmillElecRpm 0;
BA_ "Confidence" SG_ 656 VCLEFT_hvac2RRightVerticalVeloci 0;
BA_ "SystemSignalLongSymbol" SG_ 656 VCLEFT_hvac2RRightVerticalVeloci "VCLEFT_hvac2RRightVerticalVelocity";
BA_ "Confidence" SG_ 656 VCLEFT_hvacBlowerWindmillBemf 0;
BA_ "Confidence" SG_ 656 VCLEFT_hvac2RLeftVerticalVelocit 0;
BA_ "SystemSignalLongSymbol" SG_ 656 VCLEFT_hvac2RLeftVerticalVelocit "VCLEFT_hvac2RLeftVerticalVelocity";
BA_ "Confidence" SG_ 656 VCLEFT_hvac2RLeftLateralVelocity 0;
BA_ "Confidence" SG_ 656 VCLEFT_vcusbLinSchedule 0;
BA_ "Confidence" SG_ 656 VCLEFT_hvacBlowerArbState 0;
BA_ "Confidence" SG_ 656 VCLEFT_hvacBlowerArbResult 0;
BA_ "Confidence" SG_ 656 VCLEFT_hvac2RLeftLateralDuty 0;
BA_ "Confidence" SG_ 656 VCLEFT_hvac2RLeftVerticalDuty 0;
BA_ "Confidence" SG_ 656 VCLEFT_hvac2RRightLateralDuty 0;
BA_ "Confidence" SG_ 656 VCLEFT_hvac2RRightVerticalDuty 0;
BA_ "Confidence" SG_ 656 VCLEFT_hvacBlowerWindmilling 0;
BA_ "Confidence" SG_ 656 VCLEFT_hvac2RRightLateralVelocit 0;
BA_ "SystemSignalLongSymbol" SG_ 656 VCLEFT_hvac2RRightLateralVelocit "VCLEFT_hvac2RRightLateralVelocity";
BA_ "Confidence" SG_ 656 VCLEFT_hvacBlower1msOverrunFrequ 0;
BA_ "SystemSignalLongSymbol" SG_ 656 VCLEFT_hvacBlower1msOverrunFrequ "VCLEFT_hvacBlower1msOverrunFrequency";
BA_ "Confidence" SG_ 656 VCLEFT_hvacBlower10msOverrunFreq 0;
BA_ "SystemSignalLongSymbol" SG_ 656 VCLEFT_hvacBlower10msOverrunFreq "VCLEFT_hvacBlower10msOverrunFrequency";
BA_ "Confidence" SG_ 657 VCLEFT_thermalLogging1HzIndex 1;
BA_ "Confidence" SG_ 657 VCLEFT_hvac2RLeftLateralZeroStop 0;
BA_ "SystemSignalLongSymbol" SG_ 657 VCLEFT_hvac2RLeftLateralZeroStop "VCLEFT_hvac2RLeftLateralZeroStopVoltage";
BA_ "Confidence" SG_ 657 VCLEFT_hvac2RLeftVerticalZeroSto 0;
BA_ "SystemSignalLongSymbol" SG_ 657 VCLEFT_hvac2RLeftVerticalZeroSto "VCLEFT_hvac2RLeftVerticalZeroStopVoltage";
BA_ "Confidence" SG_ 657 VCLEFT_hvac2RRightLateralZeroSto 0;
BA_ "SystemSignalLongSymbol" SG_ 657 VCLEFT_hvac2RRightLateralZeroSto "VCLEFT_hvac2RRightLateralZeroStopVoltage";
BA_ "Confidence" SG_ 657 VCLEFT_hvac2RRightVerticalZeroSt 0;
BA_ "SystemSignalLongSymbol" SG_ 657 VCLEFT_hvac2RRightVerticalZeroSt "VCLEFT_hvac2RRightVerticalZeroStopVoltage";
BA_ "Confidence" SG_ 657 VCLEFT_hvac2RLeftLateralEndStopV 0;
BA_ "SystemSignalLongSymbol" SG_ 657 VCLEFT_hvac2RLeftLateralEndStopV "VCLEFT_hvac2RLeftLateralEndStopVoltage";
BA_ "Confidence" SG_ 657 VCLEFT_hvac2RLeftVerticalEndStop 0;
BA_ "SystemSignalLongSymbol" SG_ 657 VCLEFT_hvac2RLeftVerticalEndStop "VCLEFT_hvac2RLeftVerticalEndStopVoltage";
BA_ "Confidence" SG_ 657 VCLEFT_hvac2RRightLateralEndStop 0;
BA_ "SystemSignalLongSymbol" SG_ 657 VCLEFT_hvac2RRightLateralEndStop "VCLEFT_hvac2RRightLateralEndStopVoltage";
BA_ "Confidence" SG_ 657 VCLEFT_hvac2RRightVerticalEndSto 0;
BA_ "SystemSignalLongSymbol" SG_ 657 VCLEFT_hvac2RRightVerticalEndSto "VCLEFT_hvac2RRightVerticalEndStopVoltage";
BA_ "Confidence" SG_ 657 VCLEFT_hvacBlowerArbCurrent 0;
BA_ "Confidence" SG_ 657 VCLEFT_hvacBlowerTorqueIndexFilt 0;
BA_ "SystemSignalLongSymbol" SG_ 657 VCLEFT_hvacBlowerTorqueIndexFilt "VCLEFT_hvacBlowerTorqueIndexFiltered";
BA_ "Confidence" SG_ 386 VCLEFT_hvac2RLeftLateralStatus 0;
BA_ "Confidence" SG_ 386 VCLEFT_hvac2RLeftVerticalStatus 0;
BA_ "Confidence" SG_ 386 VCLEFT_hvac2RRightLateralStatus 0;
BA_ "Confidence" SG_ 386 VCLEFT_hvac2RRightVerticalStatus 0;
BA_ "Confidence" SG_ 386 VCLEFT_hvac2RLeftLateralPosition 0;
BA_ "Confidence" SG_ 386 VCLEFT_hvac2RLeftVerticalPositio 0;
BA_ "SystemSignalLongSymbol" SG_ 386 VCLEFT_hvac2RLeftVerticalPositio "VCLEFT_hvac2RLeftVerticalPosition";
BA_ "Confidence" SG_ 386 VCLEFT_hvac2RRightLateralPositio 0;
BA_ "SystemSignalLongSymbol" SG_ 386 VCLEFT_hvac2RRightLateralPositio "VCLEFT_hvac2RRightLateralPosition";
BA_ "Confidence" SG_ 386 VCLEFT_hvac2RRightVerticalPositi 0;
BA_ "SystemSignalLongSymbol" SG_ 386 VCLEFT_hvac2RRightVerticalPositi "VCLEFT_hvac2RRightVerticalPosition";
BA_ "Confidence" SG_ 706 VCLEFT_windowStatusIndex 1;
BA_ "Confidence" SG_ 706 VCLEFT_windowStateLF 0;
BA_ "Confidence" SG_ 706 VCLEFT_windowTrimClearMoveReques 0;
BA_ "SystemSignalLongSymbol" SG_ 706 VCLEFT_windowTrimClearMoveReques "VCLEFT_windowTrimClearMoveRequest";
BA_ "Confidence" SG_ 706 VCLEFT_windowDutyLF 0;
BA_ "Confidence" SG_ 706 VCLEFT_windowTrimClearActiveRequ 0;
BA_ "GenSigSNA" SG_ 706 VCLEFT_windowTrimClearActiveRequ "0";
BA_ "SystemSignalLongSymbol" SG_ 706 VCLEFT_windowTrimClearActiveRequ "VCLEFT_windowTrimClearActiveRequest";
BA_ "Confidence" SG_ 706 VCLEFT_windowCurrentLF 0;
BA_ "Confidence" SG_ 706 VCLEFT_windowPositionLF 0;
BA_ "GenSigSNA" SG_ 706 VCLEFT_windowPositionLF "1";
BA_ "Confidence" SG_ 706 VCLEFT_windowCalibratedLF 0;
BA_ "Confidence" SG_ 706 VCLEFT_windowStateLR 0;
BA_ "Confidence" SG_ 706 VCLEFT_windowDutyLR 0;
BA_ "Confidence" SG_ 706 VCLEFT_windowCurrentLR 0;
BA_ "Confidence" SG_ 706 VCLEFT_windowPositionLR 0;
BA_ "Confidence" SG_ 706 VCLEFT_windowCalibratedLR 0;
BA_ "Confidence" SG_ 706 VCLEFT_windowThermalTCLF 0;
BA_ "Confidence" SG_ 706 VCLEFT_windowThermalModeLF 0;
BA_ "GenSigSNA" SG_ 706 VCLEFT_windowThermalModeLF "0";
BA_ "Confidence" SG_ 706 VCLEFT_windowStopReasonLF 0;
BA_ "Confidence" SG_ 706 VCLEFT_windowStopReqReasonLF 0;
BA_ "Confidence" SG_ 706 VCLEFT_windowThermalTCLR 0;
BA_ "Confidence" SG_ 706 VCLEFT_windowThermalModeLR 0;
BA_ "GenSigSNA" SG_ 706 VCLEFT_windowThermalModeLR "0";
BA_ "Confidence" SG_ 706 VCLEFT_windowStopReasonLR 0;
BA_ "Confidence" SG_ 706 VCLEFT_windowStopReqReasonLR 0;
BA_ "Confidence" SG_ 706 VCLEFT_windowControlStateLF 0;
BA_ "Confidence" SG_ 706 VCLEFT_windowCtrlUnavailableLF 0;
BA_ "Confidence" SG_ 706 VCLEFT_windowControlStateLR 0;
BA_ "Confidence" SG_ 706 VCLEFT_windowCtrlUnavailableLR 0;
BA_ "Confidence" SG_ 706 VCLEFT_windowPositionStateLF 0;
BA_ "Confidence" SG_ 706 VCLEFT_windowPositionStateLR 0;
BA_ "Confidence" SG_ 706 VCLEFT_windowVehGearStateLF 0;
BA_ "GenSigSNA" SG_ 706 VCLEFT_windowVehGearStateLF "0";
BA_ "Confidence" SG_ 706 VCLEFT_windowVehGearStateLR 0;
BA_ "GenSigSNA" SG_ 706 VCLEFT_windowVehGearStateLR "0";
BA_ "Confidence" SG_ 706 VCLEFT_windowSpeedTableStatusLF 0;
BA_ "GenSigSNA" SG_ 706 VCLEFT_windowSpeedTableStatusLF "0";
BA_ "Confidence" SG_ 706 VCLEFT_windowSpeedTableStatusLR 0;
BA_ "GenSigSNA" SG_ 706 VCLEFT_windowSpeedTableStatusLR "0";
BA_ "Confidence" SG_ 549 VCRIGHT_ptcLVState 0;
BA_ "Confidence" SG_ 549 VCRIGHT_ocsLVState 0;
BA_ "Confidence" SG_ 549 VCRIGHT_premAudioLVState 0;
BA_ "Confidence" SG_ 549 VCRIGHT_rearOilPumpLVState 0;
BA_ "Confidence" SG_ 549 VCRIGHT_tunerLVState 0;
BA_ "Confidence" SG_ 549 VCRIGHT_hvcLVState 0;
BA_ "Confidence" SG_ 549 VCRIGHT_rcmLVState 0;
BA_ "Confidence" SG_ 549 VCRIGHT_lumbarLVState 0;
BA_ "Confidence" SG_ 549 VCRIGHT_3RUSBPowered 0;
BA_ "Confidence" SG_ 549 VCRIGHT_cntctrPwrState 0;
BA_ "Confidence" SG_ 549 VCRIGHT_eFuseLockoutStatus 0;
BA_ "Confidence" SG_ 549 VCRIGHT_swEnStatus 0;
BA_ "Confidence" SG_ 549 VCRIGHT_vehiclePowerStateDBG 0;
BA_ "Confidence" SG_ 549 VCRIGHT_parkLVState 0;
BA_ "Confidence" SG_ 549 VCRIGHT_icrLVState 0;
BA_ "Confidence" SG_ 549 VCRIGHT_interiorCameraLedLVState 0;
BA_ "Confidence" SG_ 549 VCRIGHT_diLVState 0;
BA_ "Confidence" SG_ 549 VCRIGHT_accDevicesDetected 0;
BA_ "Confidence" SG_ 643 VCRIGHT_PTCLeftTargetPowerHV 0;
BA_ "Confidence" SG_ 643 VCRIGHT_PTCRightTargetPowerHV 0;
BA_ "Confidence" SG_ 643 VCRIGHT_PTCLeftTargetDuty 0;
BA_ "Confidence" SG_ 643 VCRIGHT_PTCRightTargetDuty 0;
BA_ "Confidence" SG_ 643 VCRIGHT_PTCFlagAllowOperation 0;
BA_ "Confidence" SG_ 643 VCRIGHT_PTCRequestMode 0;
BA_ "Confidence" SG_ 643 VCRIGHT_PTCResistanceCheckEnable 0;
BA_ "Confidence" SG_ 643 VCRIGHT_PTCReset 0;
BA_ "Confidence" SG_ 643 VCRIGHT_PTCLeftDirectDriveIGBTO 0;
BA_ "Confidence" SG_ 643 VCRIGHT_PTCLeftDirectDriveIGBTC 0;
BA_ "Confidence" SG_ 643 VCRIGHT_PTCLeftDirectDriveIGBTI 0;
BA_ "Confidence" SG_ 643 VCRIGHT_PTCRightDirectDriveIGBTI 0;
BA_ "Confidence" SG_ 643 VCRIGHT_PTCRightDirectDriveIGBTC 0;
BA_ "Confidence" SG_ 643 VCRIGHT_PTCRightDirectDriveIGBTO 0;
BA_ "Confidence" SG_ 1795 VCRIGHT_debugThermal10HzIndex 1;
BA_ "Confidence" SG_ 1795 VCRIGHT_hvacPanelFloorSplitRow1 0;
BA_ "Confidence" SG_ 1795 VCRIGHT_hvacDefrostPercent 0;
BA_ "Confidence" SG_ 1795 VCRIGHT_hvacRow2Percent 0;
BA_ "Confidence" SG_ 1795 VCRIGHT_hvacPanelFloorSplitRow2 0;
BA_ "Confidence" SG_ 1795 VCRIGHT_hvacFreshMassCounter 0;
BA_ "Confidence" SG_ 1795 VCRIGHT_hvacRecircMassCounter 0;
BA_ "Confidence" SG_ 1795 VCRIGHT_setTempAdjustmentLeft 0;
BA_ "GenSigSNA" SG_ 1795 VCRIGHT_setTempAdjustmentLeft "127";
BA_ "Confidence" SG_ 1795 VCRIGHT_setTempAdjustmentRight 0;
BA_ "GenSigSNA" SG_ 1795 VCRIGHT_setTempAdjustmentRight "127";
BA_ "Confidence" SG_ 1795 VCRIGHT_hvacLHVaneVelocity 0;
BA_ "Confidence" SG_ 1795 VCRIGHT_hvacRHVaneVelocity 0;
BA_ "Confidence" SG_ 1795 VCRIGHT_hvacVehicleSpeed 0;
BA_ "Confidence" SG_ 1795 VCRIGHT_hvacMassflowCompensated 0;
BA_ "Confidence" SG_ 1795 VCRIGHT_PTCcenterPowerLeft 0;
BA_ "GenSigSNA" SG_ 1795 VCRIGHT_PTCcenterPowerLeft "63";
BA_ "Confidence" SG_ 1795 VCRIGHT_PTCouterPowerLeft 0;
BA_ "GenSigSNA" SG_ 1795 VCRIGHT_PTCouterPowerLeft "63";
BA_ "Confidence" SG_ 1795 VCRIGHT_PTCinnerPowerLeft 0;
BA_ "GenSigSNA" SG_ 1795 VCRIGHT_PTCinnerPowerLeft "63";
BA_ "Confidence" SG_ 1795 VCRIGHT_PTCcenterPowerRight 0;
BA_ "GenSigSNA" SG_ 1795 VCRIGHT_PTCcenterPowerRight "63";
BA_ "Confidence" SG_ 1795 VCRIGHT_PTCouterPowerRight 0;
BA_ "GenSigSNA" SG_ 1795 VCRIGHT_PTCouterPowerRight "63";
BA_ "Confidence" SG_ 1795 VCRIGHT_PTCinnerPowerRight 0;
BA_ "GenSigSNA" SG_ 1795 VCRIGHT_PTCinnerPowerRight "63";
BA_ "Confidence" SG_ 1795 VCRIGHT_PTCcenterStoneTempLeft 0;
BA_ "GenSigSNA" SG_ 1795 VCRIGHT_PTCcenterStoneTempLeft "255";
BA_ "Confidence" SG_ 1795 VCRIGHT_PTCcenterStoneTempRight 0;
BA_ "GenSigSNA" SG_ 1795 VCRIGHT_PTCcenterStoneTempRight "255";
BA_ "Confidence" SG_ 1795 VCRIGHT_PTCinnerStoneTempLeft 0;
BA_ "GenSigSNA" SG_ 1795 VCRIGHT_PTCinnerStoneTempLeft "255";
BA_ "Confidence" SG_ 1795 VCRIGHT_PTCinnerStoneTempRight 0;
BA_ "GenSigSNA" SG_ 1795 VCRIGHT_PTCinnerStoneTempRight "255";
BA_ "Confidence" SG_ 1795 VCRIGHT_PTCouterStoneTempLeft 0;
BA_ "GenSigSNA" SG_ 1795 VCRIGHT_PTCouterStoneTempLeft "255";
BA_ "Confidence" SG_ 1795 VCRIGHT_PTCouterRodTempLeft 0;
BA_ "GenSigSNA" SG_ 1795 VCRIGHT_PTCouterRodTempLeft "255";
BA_ "Confidence" SG_ 1795 VCRIGHT_PTCouterAirTempLeft 0;
BA_ "GenSigSNA" SG_ 1795 VCRIGHT_PTCouterAirTempLeft "255";
BA_ "Confidence" SG_ 1795 VCRIGHT_PTCcenterRodTempLeft 0;
BA_ "GenSigSNA" SG_ 1795 VCRIGHT_PTCcenterRodTempLeft "255";
BA_ "Confidence" SG_ 1795 VCRIGHT_PTCinnerRodTempLeft 0;
BA_ "GenSigSNA" SG_ 1795 VCRIGHT_PTCinnerRodTempLeft "255";
BA_ "Confidence" SG_ 1795 VCRIGHT_PTCcenterAirTempLeft 0;
BA_ "GenSigSNA" SG_ 1795 VCRIGHT_PTCcenterAirTempLeft "255";
BA_ "Confidence" SG_ 1795 VCRIGHT_PTCinnerAirTempLeft 0;
BA_ "GenSigSNA" SG_ 1795 VCRIGHT_PTCinnerAirTempLeft "255";
BA_ "Confidence" SG_ 1795 VCRIGHT_PTCouterStoneTempRight 0;
BA_ "GenSigSNA" SG_ 1795 VCRIGHT_PTCouterStoneTempRight "255";
BA_ "Confidence" SG_ 1795 VCRIGHT_PTCouterRodTempRight 0;
BA_ "GenSigSNA" SG_ 1795 VCRIGHT_PTCouterRodTempRight "255";
BA_ "Confidence" SG_ 1795 VCRIGHT_PTCouterAirTempRight 0;
BA_ "GenSigSNA" SG_ 1795 VCRIGHT_PTCouterAirTempRight "255";
BA_ "Confidence" SG_ 1795 VCRIGHT_PTCcenterRodTempRight 0;
BA_ "GenSigSNA" SG_ 1795 VCRIGHT_PTCcenterRodTempRight "255";
BA_ "Confidence" SG_ 1795 VCRIGHT_PTCinnerRodTempRight 0;
BA_ "GenSigSNA" SG_ 1795 VCRIGHT_PTCinnerRodTempRight "255";
BA_ "Confidence" SG_ 1795 VCRIGHT_PTCcenterAirTempRight 0;
BA_ "GenSigSNA" SG_ 1795 VCRIGHT_PTCcenterAirTempRight "255";
BA_ "Confidence" SG_ 1795 VCRIGHT_PTCinnerAirTempRight 0;
BA_ "GenSigSNA" SG_ 1795 VCRIGHT_PTCinnerAirTempRight "255";
BA_ "Confidence" SG_ 291 VCRIGHT_doorStatus2Index 1;
BA_ "Confidence" SG_ 291 VCRIGHT_frontLatchRelDuty 0;
BA_ "Confidence" SG_ 291 VCRIGHT_BPillarCameraHeaterState 0;
BA_ "GenSigSNA" SG_ 291 VCRIGHT_BPillarCameraHeaterState "0";
BA_ "Confidence" SG_ 291 VCRIGHT_doorLatchAjarSwitchVolta 0;
BA_ "SystemSignalLongSymbol" SG_ 291 VCRIGHT_doorLatchAjarSwitchVolta "VCRIGHT_doorLatchAjarSwitchVoltageF";
BA_ "Confidence" SG_ 291 VCRIGHT_doorLatchAjarSwitch_0001 0;
BA_ "SystemSignalLongSymbol" SG_ 291 VCRIGHT_doorLatchAjarSwitch_0001 "VCRIGHT_doorLatchAjarSwitchVoltageR";
BA_ "Confidence" SG_ 291 VCRIGHT_BPillarCameraHeaterCurre 0;
BA_ "GenSigSNA" SG_ 291 VCRIGHT_BPillarCameraHeaterCurre "63";
BA_ "SystemSignalLongSymbol" SG_ 291 VCRIGHT_BPillarCameraHeaterCurre "VCRIGHT_BPillarCameraHeaterCurrent";
BA_ "Confidence" SG_ 291 VCRIGHT_mirrorTiltXOffset 0;
BA_ "Confidence" SG_ 291 VCRIGHT_mirrorTiltYOffset 0;
BA_ "Confidence" SG_ 915 VCRIGHT_epbmDebugIndex 1;
BA_ "Confidence" SG_ 915 VCRIGHT_epbmCaliperState 0;
BA_ "Confidence" SG_ 915 VCRIGHT_epbmMotorEnabled 0;
BA_ "Confidence" SG_ 915 VCRIGHT_epbMotorCurrent 0;
BA_ "Confidence" SG_ 915 VCRIGHT_epbmApplyVoltage 0;
BA_ "Confidence" SG_ 915 VCRIGHT_epbmReleaseVoltage 0;
BA_ "Confidence" SG_ 915 VCRIGHT_summonFaultReason 0;
BA_ "Confidence" SG_ 915 VCRIGHT_epbSummonState 0;
BA_ "Confidence" SG_ 915 VCRIGHT_epbmSummonState 0;
BA_ "Confidence" SG_ 915 VCRIGHT_epbUnitStatus 0;
BA_ "Confidence" SG_ 915 VCRIGHT_epbmFaultStatus 0;
BA_ "Confidence" SG_ 915 VCRIGHT_epbFaultStatus 0;
BA_ "Confidence" SG_ 915 VCRIGHT_epbmSystemStatus 0;
BA_ "Confidence" SG_ 915 VCRIGHT_epbmAutonomyBehavior 0;
BA_ "Confidence" SG_ 524 VCRIGHT_wattsDemandEvap 0;
BA_ "Confidence" SG_ 524 VCRIGHT_hvacEvapEnabled 0;
BA_ "Confidence" SG_ 524 VCRIGHT_conditioningRequest 0;
BA_ "Confidence" SG_ 524 VCRIGHT_tempEvaporator 0;
BA_ "GenSigSNA" SG_ 524 VCRIGHT_tempEvaporator "2047";
BA_ "Confidence" SG_ 524 VCRIGHT_tempEvaporatorTarget 0;
BA_ "GenSigSNA" SG_ 524 VCRIGHT_tempEvaporatorTarget "255";
BA_ "Confidence" SG_ 524 VCRIGHT_hvacBlowerSpeedRPMReq 0;
BA_ "Confidence" SG_ 524 VCRIGHT_hvacPerfTestRunning 0;
BA_ "Confidence" SG_ 524 VCRIGHT_evapPerformanceLow 0;
BA_ "Confidence" SG_ 524 VCRIGHT_tempAmbientRaw 0;
BA_ "GenSigSNA" SG_ 524 VCRIGHT_tempAmbientRaw "0";
BA_ "Confidence" SG_ 524 VCRIGHT_hvacHeatingEnabledLeft 0;
BA_ "Confidence" SG_ 524 VCRIGHT_hvacHeatingEnabledRight 0;
BA_ "Confidence" SG_ 524 VCRIGHT_hvacPerfTestState 0;
BA_ "Confidence" SG_ 524 VCRIGHT_hvacUnavailable 0;
BA_ "Confidence" SG_ 524 VCRIGHT_hvacBlowerRPMActualAP 0;
BA_ "Confidence" SG_ 524 VCRIGHT_hvacEvapEnabledInColdAmb 0;
BA_ "SystemSignalLongSymbol" SG_ 524 VCRIGHT_hvacEvapEnabledInColdAmb "VCRIGHT_hvacEvapEnabledInColdAmbient";
VAL_ 994 VCLEFT_brakeLightStatus 3 "LIGHT_SNA" 2 "LIGHT_FAULT" 1 "LIGHT_ON" 0 "LIGHT_OFF" ;
VAL_ 994 VCLEFT_tailLightStatus 3 "LIGHT_SNA" 2 "LIGHT_FAULT" 1 "LIGHT_ON" 0 "LIGHT_OFF" ;
VAL_ 994 VCLEFT_turnSignalStatus 3 "LIGHT_SNA" 2 "LIGHT_FAULT" 1 "LIGHT_ON" 0 "LIGHT_OFF" ;
VAL_ 994 VCLEFT_FLMapLightStatus 3 "LIGHT_SNA" 2 "LIGHT_FAULT" 1 "LIGHT_ON" 0 "LIGHT_OFF" ;
VAL_ 994 VCLEFT_FRMapLightStatus 3 "LIGHT_SNA" 2 "LIGHT_FAULT" 1 "LIGHT_ON" 0 "LIGHT_OFF" ;
VAL_ 994 VCLEFT_RLMapLightStatus 3 "LIGHT_SNA" 2 "LIGHT_FAULT" 1 "LIGHT_ON" 0 "LIGHT_OFF" ;
VAL_ 994 VCLEFT_RRMapLightStatus 3 "LIGHT_SNA" 2 "LIGHT_FAULT" 1 "LIGHT_ON" 0 "LIGHT_OFF" ;
VAL_ 994 VCLEFT_leftTurnTrailerLightStatu 3 "LIGHT_SNA" 2 "LIGHT_FAULT" 1 "LIGHT_ON" 0 "LIGHT_OFF" ;
VAL_ 994 VCLEFT_rightTrnTrailerLightStatu 3 "LIGHT_SNA" 2 "LIGHT_FAULT" 1 "LIGHT_ON" 0 "LIGHT_OFF" ;
VAL_ 994 VCLEFT_brakeTrailerLightStatus 3 "LIGHT_SNA" 2 "LIGHT_FAULT" 1 "LIGHT_ON" 0 "LIGHT_OFF" ;
VAL_ 994 VCLEFT_tailTrailerLightStatus 3 "LIGHT_SNA" 2 "LIGHT_FAULT" 1 "LIGHT_ON" 0 "LIGHT_OFF" ;
VAL_ 994 VCLEFT_fogTrailerLightStatus 3 "LIGHT_SNA" 2 "LIGHT_FAULT" 1 "LIGHT_ON" 0 "LIGHT_OFF" ;
VAL_ 994 VCLEFT_frontRideHeight -128 "SNA" ;
VAL_ 994 VCLEFT_rearRideHeight -128 "SNA" ;
VAL_ 994 VCLEFT_trailerDetected 3 "TRAILER_LIGHT_DETECTION_NOT_DETECTED" 2 "TRAILER_LIGHT_DETECTION_DETECTED" 1 "TRAILER_LIGHT_DETECTION_FAULT" 0 "TRAILER_LIGHT_DETECTION_SNA" ;
VAL_ 994 VCLEFT_reverseTrailerLightStatus 3 "LIGHT_SNA" 2 "LIGHT_FAULT" 1 "LIGHT_ON" 0 "LIGHT_OFF" ;
VAL_ 994 VCLEFT_reverseLightStatus 3 "LIGHT_SNA" 2 "LIGHT_FAULT" 1 "LIGHT_ON" 0 "LIGHT_OFF" ;
VAL_ 1802 VCLEFT_logging0point1HzIndex 1 "END" 0 "MISC" ;
VAL_ 1802 VCLEFT_leftBrakeTailLightCurrent 511 "SNA" ;
VAL_ 1802 VCLEFT_leftBrakeTailLightCu_0001 4 "FALLING_EDGE_TRANSIENT" 3 "STEADY_STATE_ON" 2 "RISING_EDGE_TRANSIENT" 1 "STEADY_STATE_OFF" 0 "SNA" ;
VAL_ 1802 VCLEFT_leftRearTurnLightCurrent 511 "SNA" ;
VAL_ 1802 VCLEFT_leftRearTurnLightCurrentS 4 "FALLING_EDGE_TRANSIENT" 3 "STEADY_STATE_ON" 2 "RISING_EDGE_TRANSIENT" 1 "STEADY_STATE_OFF" 0 "SNA" ;
VAL_ 936 VCLEFT_logging1HzIndex 5 "END" 4 "CURRENT_LOGGING" 3 "BODY_CONTROLS_LOGGING" 2 "HSD_CURRENTS_2" 1 "HSD_CURRENTS_1" 0 "MISC" ;
VAL_ 936 VCLEFT_tohcPCBATemperature 255 "SNA" ;
VAL_ 936 VCLEFT_swcResistance 127 "SNA" ;
VAL_ 727 VCLEFT_pitchEstimateFusionState 7 "PITCHESTIMATION_STATE_UNKNOWN" 4 "PITCHESTIMATION_STATE_CALCULATE" 3 "PITCHESTIMATION_STATE_WAIT_FOR_STARTUP" 2 "PITCHESTIMATION_STATE_WAIT_FOR_SPEED" 1 "PITCHESTIMATION_STATE_WAIT_FOR_SIGNALS_AND_DOORS" 0 "PITCHESTIMATION_STATE_INIT" ;
VAL_ 727 VCLEFT_pitchEstimateStateTransit 26 "PITCHESTIMATION_DELTA_LIVE_THEN_VALIDITIES_NOT_GOOD" 25 "PITCHESTIMATION_DELTA_LIVE_THEN_FUSION_INIT" 24 "PITCHESTIMATION_DELTA_LIVE_THEN_LIVE_AX" 23 "PITCHESTIMATION_DELTA_LIVE_THEN_SPEED_AND_EPB_NOT_PARKED" 22 "PITCHESTIMATION_DELTA_LIVE_THEN_NVRAM_DISALLOW" 21 "PITCHESTIMATION_DELTA_LIVE_THEN_TRANSPORT" 20 "PITCHESTIMATION_DELTA_LIVE_THEN_DOORS_CLOSED_LONG_TIME" 19 "PITCHESTIMATION_DELTA_LIVE_THEN_EPB_RELEASING" 18 "PITCHESTIMATION_CARRYOVER_THEN_LIVE_AX" 17 "PITCHESTIMATION_CARRYOVER_THEN_FUSION_READY" 16 "PITCHESTIMATION_CARRYOVER_THEN_VALIDITIES_NOT_GOOD" 15 "PITCHESTIMATION_CARRYOVER_THEN_FUSION_INIT" 14 "PITCHESTIMATION_FROZEN_THEN_LIVE_AX" 13 "PITCHESTIMATION_FROZEN_THEN_FUSION_READY" 12 "PITCHESTIMATION_FROZEN_THEN_VALIDITIES_NOT_GOOD" 11 "PITCHESTIMATION_FROZEN_THEN_FUSION_INIT" 10 "PITCHESTIMATION_FUSION_THEN_LIVE_AX" 9 "PITCHESTIMATION_FUSION_THEN_FUSION_INIT" 8 "PITCHESTIMATION_UNAVAILABLE_THEN_LIVE_AX" 7 "PITCHESTIMATION_UNAVAILABLE_THEN_FUSION_READY" 6 "PITCHESTIMATION_UNAVAILABLE_THEN_DELTA_LIVE_READY" 5 "PITCHESTIMATION_UNAVAILABLE_THEN_SPEED_AND_EPB_NOT_PARKED" 4 "PITCHESTIMATION_UNAVAILABLE_THEN_NVRAM_DISALLOW" 3 "PITCHESTIMATION_UNAVAILABLE_THEN_TRANSPORT" 2 "PITCHESTIMATION_LIVE_AX_THEN_VALIDITIES_NOT_GOOD" 1 "PITCHESTIMATION_LIVE_AX_THEN_NO_LONGER_LIVE_AX" 0 "PITCHESTIMATION_INVALID_STATE_TRANSITION_DEFAULT" ;
VAL_ 727 VCLEFT_pitchEstimateArbitratedSt 7 "PITCHESTIMATION_ARBITRATEDSTATE_UNKNOWN" 5 "PITCHESTIMATION_ARBITRATEDSTATE_LIVE_AX_NO_DELTA" 4 "PITCHESTIMATION_ARBITRATEDSTATE_CYCLE_DELTA_FROZEN" 3 "PITCHESTIMATION_ARBITRATEDSTATE_CYCLE_DELTA_CARRYOVER" 2 "PITCHESTIMATION_ARBITRATEDSTATE_CYCLE_DELTA_LIVE" 1 "PITCHESTIMATION_ARBITRATEDSTATE_FUSION" 0 "PITCHESTIMATION_ARBITRATEDSTATE_UNAVAILABLE" ;
VAL_ 727 VCLEFT_pitchEstimate -512 "SNA" ;
VAL_ 1860 VCLEFT_systemRecallStatus 3 "RECALL_INTERRUPTED" 2 "RECALL_COMPLETE" 1 "RECALL_IN_PROGRESS" 0 "RECALL_SNA" ;
VAL_ 1860 VCLEFT_seatRecallStatus 3 "RECALL_INTERRUPTED" 2 "RECALL_COMPLETE" 1 "RECALL_IN_PROGRESS" 0 "RECALL_SNA" ;
VAL_ 1860 VCLEFT_columnRecallStatus 3 "RECALL_INTERRUPTED" 2 "RECALL_COMPLETE" 1 "RECALL_IN_PROGRESS" 0 "RECALL_SNA" ;
VAL_ 1860 VCLEFT_mirrorRecallStatus 3 "RECALL_INTERRUPTED" 2 "RECALL_COMPLETE" 1 "RECALL_IN_PROGRESS" 0 "RECALL_SNA" ;
VAL_ 1250 VCLEFT_seatStatusIndex 7 "RELATIVE_POSITION" 6 "OFFSETS" 5 "POSITION" 4 "LUMBAR" 3 "TILT" 2 "LIFT" 1 "BACK" 0 "TRACK" ;
VAL_ 1250 VC_AH_1RowLeftSeatMovementHealth 4 "SEAT_CALIBRATION_REQUIRED" 3 "SEAT_IN_NON_USE_POSITION" 2 "SEAT_CANNOT_MOVE" 1 "SEAT_MOVEMENT_HEALTHY" 0 "SEAT_MOVEMENT_HEALTH_UNKNOWN" ;
VAL_ 1250 VCLEFT_frontSeatTrackState 5 "SEAT_STATE_UNDEFINED" 4 "SEAT_STATE_CALIBRATING" 3 "SEAT_STATE_RECALLING" 2 "SEAT_STATE_MOVING_DOWN" 1 "SEAT_STATE_MOVING_UP" 0 "SEAT_STATE_STOPPED" ;
VAL_ 1250 VCLEFT_frontSeatTrackBridgeSt 3 "IO_BRIDGE_STATE_COAST" 2 "IO_BRIDGE_STATE_BRAKE" 1 "IO_BRIDGE_STATE_ENABLED" 0 "IO_BRIDGE_STATE_DISABLED" ;
VAL_ 1250 VCLEFT_frontSeatBackState 5 "SEAT_STATE_UNDEFINED" 4 "SEAT_STATE_CALIBRATING" 3 "SEAT_STATE_RECALLING" 2 "SEAT_STATE_MOVING_DOWN" 1 "SEAT_STATE_MOVING_UP" 0 "SEAT_STATE_STOPPED" ;
VAL_ 1250 VCLEFT_frontSeatBackBridgeSt 3 "IO_BRIDGE_STATE_COAST" 2 "IO_BRIDGE_STATE_BRAKE" 1 "IO_BRIDGE_STATE_ENABLED" 0 "IO_BRIDGE_STATE_DISABLED" ;
VAL_ 1250 VCLEFT_frontSeatLiftState 5 "SEAT_STATE_UNDEFINED" 4 "SEAT_STATE_CALIBRATING" 3 "SEAT_STATE_RECALLING" 2 "SEAT_STATE_MOVING_DOWN" 1 "SEAT_STATE_MOVING_UP" 0 "SEAT_STATE_STOPPED" ;
VAL_ 1250 VCLEFT_frontSeatLiftBridgeSt 3 "IO_BRIDGE_STATE_COAST" 2 "IO_BRIDGE_STATE_BRAKE" 1 "IO_BRIDGE_STATE_ENABLED" 0 "IO_BRIDGE_STATE_DISABLED" ;
VAL_ 1250 VCLEFT_frontSeatTiltState 5 "SEAT_STATE_UNDEFINED" 4 "SEAT_STATE_CALIBRATING" 3 "SEAT_STATE_RECALLING" 2 "SEAT_STATE_MOVING_DOWN" 1 "SEAT_STATE_MOVING_UP" 0 "SEAT_STATE_STOPPED" ;
VAL_ 1250 VCLEFT_frontSeatTiltBridgeSt 3 "IO_BRIDGE_STATE_COAST" 2 "IO_BRIDGE_STATE_BRAKE" 1 "IO_BRIDGE_STATE_ENABLED" 0 "IO_BRIDGE_STATE_DISABLED" ;
VAL_ 1250 VCLEFT_lumbarAState 5 "SEAT_STATE_UNDEFINED" 4 "SEAT_STATE_CALIBRATING" 3 "SEAT_STATE_RECALLING" 2 "SEAT_STATE_MOVING_DOWN" 1 "SEAT_STATE_MOVING_UP" 0 "SEAT_STATE_STOPPED" ;
VAL_ 1250 VCLEFT_lumbarBState 5 "SEAT_STATE_UNDEFINED" 4 "SEAT_STATE_CALIBRATING" 3 "SEAT_STATE_RECALLING" 2 "SEAT_STATE_MOVING_DOWN" 1 "SEAT_STATE_MOVING_UP" 0 "SEAT_STATE_STOPPED" ;
VAL_ 738 VCLEFT_seatStatus2Index 15 "SEAT_HEAT_3R_RIGHT_CUSHION" 14 "SEAT_3ROW_ADJUSTABLE_FOLD_FLAT" 13 "FRONT_SEAT_THIGH_SUPPORT" 12 "SEAT_2ROW_ADJUSTABLE_FOLD_FLAT_2" 11 "SEAT_2ROW_ADJUSTABLE_FOLD_FLAT" 10 "SEAT_HEAT_3R_LEFT" 9 "SEAT_2ROW_EASY_ENTRY" 8 "SEAT_SWITCH_VOLTAGES_2" 7 "SEAT_SWITCH_VOLTAGES_1" 6 "SEAT_2ROW_ACTUATOR" 5 "SEAT_HEAT_REARR_CUSHION" 4 "SEAT_HEAT_REARC" 3 "SEAT_HEAT_REARL" 2 "OCCUPANCY" 1 "SEAT_HEAT_REARL_BACKREST" 0 "SEAT_HEAT_FRONT" ;
VAL_ 738 VCLEFT_frontSeatHeatCurrent 12 "SNA" ;
VAL_ 738 VCLEFT_2RowSeatFoldLeftSwitch 3 "SWITCH_FAULT" 2 "SWITCH_ON" 1 "SWITCH_OFF" 0 "SWITCH_SNA" ;
VAL_ 738 VCLEFT_2RowSeatUnfoldLeftSwitch 3 "SWITCH_FAULT" 2 "SWITCH_ON" 1 "SWITCH_OFF" 0 "SWITCH_SNA" ;
VAL_ 738 VCLEFT_2RowSeatFoldRightSwitch 3 "SWITCH_FAULT" 2 "SWITCH_ON" 1 "SWITCH_OFF" 0 "SWITCH_SNA" ;
VAL_ 738 VCLEFT_2RowSeatUnfoldRightSwitch 3 "SWITCH_FAULT" 2 "SWITCH_ON" 1 "SWITCH_OFF" 0 "SWITCH_SNA" ;
VAL_ 738 VCLEFT_3RowSeatFoldLeftSwitch 3 "SWITCH_FAULT" 2 "SWITCH_ON" 1 "SWITCH_OFF" 0 "SWITCH_SNA" ;
VAL_ 738 VCLEFT_3RowSeatUnfoldLeftSwitch 3 "SWITCH_FAULT" 2 "SWITCH_ON" 1 "SWITCH_OFF" 0 "SWITCH_SNA" ;
VAL_ 738 VCLEFT_3RowSeatFoldRightSwitch 3 "SWITCH_FAULT" 2 "SWITCH_ON" 1 "SWITCH_OFF" 0 "SWITCH_SNA" ;
VAL_ 738 VCLEFT_3RowSeatUnfoldRightSwitch 3 "SWITCH_FAULT" 2 "SWITCH_ON" 1 "SWITCH_OFF" 0 "SWITCH_SNA" ;
VAL_ 738 VC_AH_1RowLeftSeatHeatVentHealth 2 "SEAT_HEAT_VENT_UNAVAILABLE" 1 "SEAT_HEAT_VENT_HEALTHY" 0 "SEAT_HEAT_VENT_HEALTH_UNKNOWN" ;
VAL_ 738 VCLEFT_2RowSeatReclineState 15 "SEAT_ADJUSTABLE_FOLD_FLAT_STATE_SNA" 12 "SEAT_ADJUSTABLE_FOLD_FLAT_STATE_CALIBRATING_ABSOLUTE_SENSOR" 11 "SEAT_ADJUSTABLE_FOLD_FLAT_STATE_CALIBRATING_ZERO_POSITION" 10 "SEAT_ADJUSTABLE_FOLD_FLAT_STATE_WAITING_TO_CLEAR_FOR_UNFOLD" 9 "SEAT_ADJUSTABLE_FOLD_FLAT_STATE_WAITING_TO_CLEAR_FOR_FOLD" 8 "SEAT_ADJUSTABLE_FOLD_FLAT_STATE_MOVING_REARWARD_TO_POSITION" 7 "SEAT_ADJUSTABLE_FOLD_FLAT_STATE_MOVING_FORWARD_TO_POSITION" 6 "SEAT_ADJUSTABLE_FOLD_FLAT_STATE_UNFOLDING" 5 "SEAT_ADJUSTABLE_FOLD_FLAT_STATE_FOLDING" 4 "SEAT_ADJUSTABLE_FOLD_FLAT_STATE_ADJUSTING_REARWARD_FAST" 3 "SEAT_ADJUSTABLE_FOLD_FLAT_STATE_ADJUSTING_FORWARD_FAST" 2 "SEAT_ADJUSTABLE_FOLD_FLAT_STATE_ADJUSTING_REARWARD_COMFORT" 1 "SEAT_ADJUSTABLE_FOLD_FLAT_STATE_ADJUSTING_FORWARD_COMFORT" 0 "SEAT_ADJUSTABLE_FOLD_FLAT_STATE_STOPPED" ;
VAL_ 738 VCLEFT_2RowSeatReclineAbsPosSwit 3 "SWITCH_FAULT" 2 "SWITCH_ON" 1 "SWITCH_OFF" 0 "SWITCH_SNA" ;
VAL_ 738 VCLEFT_2RowSeatReclinePositionSt 4 "SEAT_ADJUSTABLE_FOLD_FLAT_POSITION_STATE_SNA" 3 "SEAT_ADJUSTABLE_FOLD_FLAT_POSITION_STATE_UNKNOWN" 2 "SEAT_ADJUSTABLE_FOLD_FLAT_POSITION_STATE_UNSAFE_INTERMEDIATE" 1 "SEAT_ADJUSTABLE_FOLD_FLAT_POSITION_STATE_UNFOLDED" 0 "SEAT_ADJUSTABLE_FOLD_FLAT_POSITION_STATE_FOLDED" ;
VAL_ 738 VCLEFT_2RowSeatReclineNextToggle 2 "SEAT_ADJUSTABLE_FOLD_FLAT_NEXT_TOGGLE_DIRECTION_SNA" 1 "SEAT_ADJUSTABLE_FOLD_FLAT_NEXT_TOGGLE_DIRECTION_UNFOLD" 0 "SEAT_ADJUSTABLE_FOLD_FLAT_NEXT_TOGGLE_DIRECTION_FOLD" ;
VAL_ 738 VCLEFT_2RowSeat1RClashAvoidanceB 6 "SEAT_FOLD_FLAT_CLASH_AVOIDANCE_REASON_FRONT_SEAT_OCCUPANCY" 5 "SEAT_FOLD_FLAT_CLASH_AVOIDANCE_REASON_FRONT_SEAT_MOVING" 4 "SEAT_FOLD_FLAT_CLASH_AVOIDANCE_REASON_FRONT_SEAT_PROFILE_RECALL" 3 "SEAT_FOLD_FLAT_CLASH_AVOIDANCE_REASON_REAR_SEAT_UNCALIBRATED" 2 "SEAT_FOLD_FLAT_CLASH_AVOIDANCE_REASON_FRONT_SEAT_UNCALIBRATED" 1 "SEAT_FOLD_FLAT_CLASH_AVOIDANCE_REASON_VEHICLE_IN_MOTION" 0 "SEAT_FOLD_FLAT_CLASH_AVOIDANCE_REASON_NONE" ;
VAL_ 738 VCLEFT_2RowSeat1RClashAvoidanceS 3 "SEAT_FOLD_FLAT_CLASH_AVOIDANCE_STATE_RESTORING_FRONT_SEAT" 2 "SEAT_FOLD_FLAT_CLASH_AVOIDANCE_STATE_WAITING_TO_RESTORE_FRONT_SEAT" 1 "SEAT_FOLD_FLAT_CLASH_AVOIDANCE_STATE_FRONT_SEAT_CLEARING" 0 "SEAT_FOLD_FLAT_CLASH_AVOIDANCE_STATE_IDLE" ;
VAL_ 738 VC_AH_2RowLeftSeatMovementHealth 4 "SEAT_CALIBRATION_REQUIRED" 3 "SEAT_IN_NON_USE_POSITION" 2 "SEAT_CANNOT_MOVE" 1 "SEAT_MOVEMENT_HEALTHY" 0 "SEAT_MOVEMENT_HEALTH_UNKNOWN" ;
VAL_ 738 VCLEFT_3RowSeatReclineState 15 "SEAT_ADJUSTABLE_FOLD_FLAT_STATE_SNA" 12 "SEAT_ADJUSTABLE_FOLD_FLAT_STATE_CALIBRATING_ABSOLUTE_SENSOR" 11 "SEAT_ADJUSTABLE_FOLD_FLAT_STATE_CALIBRATING_ZERO_POSITION" 10 "SEAT_ADJUSTABLE_FOLD_FLAT_STATE_WAITING_TO_CLEAR_FOR_UNFOLD" 9 "SEAT_ADJUSTABLE_FOLD_FLAT_STATE_WAITING_TO_CLEAR_FOR_FOLD" 8 "SEAT_ADJUSTABLE_FOLD_FLAT_STATE_MOVING_REARWARD_TO_POSITION" 7 "SEAT_ADJUSTABLE_FOLD_FLAT_STATE_MOVING_FORWARD_TO_POSITION" 6 "SEAT_ADJUSTABLE_FOLD_FLAT_STATE_UNFOLDING" 5 "SEAT_ADJUSTABLE_FOLD_FLAT_STATE_FOLDING" 4 "SEAT_ADJUSTABLE_FOLD_FLAT_STATE_ADJUSTING_REARWARD_FAST" 3 "SEAT_ADJUSTABLE_FOLD_FLAT_STATE_ADJUSTING_FORWARD_FAST" 2 "SEAT_ADJUSTABLE_FOLD_FLAT_STATE_ADJUSTING_REARWARD_COMFORT" 1 "SEAT_ADJUSTABLE_FOLD_FLAT_STATE_ADJUSTING_FORWARD_COMFORT" 0 "SEAT_ADJUSTABLE_FOLD_FLAT_STATE_STOPPED" ;
VAL_ 738 VCLEFT_3RowSeatReclineNextToggle 2 "SEAT_ADJUSTABLE_FOLD_FLAT_NEXT_TOGGLE_DIRECTION_SNA" 1 "SEAT_ADJUSTABLE_FOLD_FLAT_NEXT_TOGGLE_DIRECTION_UNFOLD" 0 "SEAT_ADJUSTABLE_FOLD_FLAT_NEXT_TOGGLE_DIRECTION_FOLD" ;
VAL_ 738 VCLEFT_3RowSeatReclinePositionSt 4 "SEAT_ADJUSTABLE_FOLD_FLAT_POSITION_STATE_SNA" 3 "SEAT_ADJUSTABLE_FOLD_FLAT_POSITION_STATE_UNKNOWN" 2 "SEAT_ADJUSTABLE_FOLD_FLAT_POSITION_STATE_UNSAFE_INTERMEDIATE" 1 "SEAT_ADJUSTABLE_FOLD_FLAT_POSITION_STATE_UNFOLDED" 0 "SEAT_ADJUSTABLE_FOLD_FLAT_POSITION_STATE_FOLDED" ;
VAL_ 738 VCLEFT_3RowSeatReclineAbsPosSwit 3 "SWITCH_FAULT" 2 "SWITCH_ON" 1 "SWITCH_OFF" 0 "SWITCH_SNA" ;
VAL_ 930 VCLEFT_statusIndex 2 "MUX2" 1 "MUX1" 0 "MUX0" ;
VAL_ 930 VCLEFT_swcInputVoltage 255 "SNA" ;
VAL_ 930 VCLEFT_swcPCBATemperature -128 "SNA" ;
VAL_ 930 VCLEFT_LVBatteryTypeDBG 5 "LV_BATTERY_TYPE_TESLA_48V_LI_ION" 4 "LV_BATTERY_TYPE_TESLA_16V_LI_ION" 3 "LV_BATTERY_TYPE_CATL_LI_ION" 2 "LV_BATTERY_TYPE_CLARIOS_B24_FLOODED" 1 "LV_BATTERY_TYPE_ATLASBX_B24_FLOODED" 0 "LV_BATTERY_TYPE_UNKNOWN" ;
VAL_ 930 VCLEFT_trailerAuxCurrent 4095 "SNA" ;
VAL_ 930 VCLEFT_swcHeatTmp 1023 "SNA" ;
VAL_ 930 VCLEFT_swcHeatStatus 4 "HEATER_STATE_FAULT" 3 "HEATER_STATE_OFF_UNAVAILABLE" 2 "HEATER_STATE_OFF" 1 "HEATER_STATE_ON" 0 "HEATER_STATE_SNA" ;
VAL_ 930 VCLEFT_swcHeatPwr 511 "SNA" ;
VAL_ 930 VCLEFT_swcHeatDutyCycle 127 "SNA" ;
VAL_ 930 VCLEFT_autonomyBehaviorStatus 2 "DRIVERLESS_NO_TAKEOVER" 1 "DRIVERLESS_TAKEOVER" 0 "DRIVER" ;
VAL_ 930 VCLEFT_thirdRowLeftMapLightStatu 3 "LIGHT_SNA" 2 "LIGHT_FAULT" 1 "LIGHT_ON" 0 "LIGHT_OFF" ;
VAL_ 930 VCLEFT_thirdRowRightMapLightStat 3 "LIGHT_SNA" 2 "LIGHT_FAULT" 1 "LIGHT_ON" 0 "LIGHT_OFF" ;
VAL_ 610 VCLEFT_steeringColumnSMState 3 "STEERING_COLUMN_STATE_MANUAL_CONTROL" 2 "STEERING_COLUMN_STATE_CALIBRATE" 1 "STEERING_COLUMN_STATE_RECALL" 0 "STEERING_COLUMN_STATE_SNA" ;
VAL_ 610 VCLEFT_steeringColumnLastRequest 5 "STEERING_COLUMN_REQUEST_OUT" 4 "STEERING_COLUMN_REQUEST_IN" 3 "STEERING_COLUMN_REQUEST_DOWN" 2 "STEERING_COLUMN_REQUEST_UP" 1 "STEERING_COLUMN_REQUEST_NONE" 0 "STEERING_COLUMN_REQUEST_SNA" ;
VAL_ 962 VCLEFT_switchStatusIndex 1 "1" 0 "0" ;
VAL_ 962 VCLEFT_rightMirrorTilt 4 "MIRROR_TILT_LEFT" 3 "MIRROR_TILT_RIGHT" 2 "MIRROR_TILT_UP" 1 "MIRROR_TILT_DOWN" 0 "MIRROR_TILT_STOP" ;
VAL_ 962 VCLEFT_frontSeatTrackBack 3 "SWITCH_FAULT" 2 "SWITCH_ON" 1 "SWITCH_OFF" 0 "SWITCH_SNA" ;
VAL_ 962 VCLEFT_frontSeatTrackForward 3 "SWITCH_FAULT" 2 "SWITCH_ON" 1 "SWITCH_OFF" 0 "SWITCH_SNA" ;
VAL_ 962 VCLEFT_frontSeatTiltDown 3 "SWITCH_FAULT" 2 "SWITCH_ON" 1 "SWITCH_OFF" 0 "SWITCH_SNA" ;
VAL_ 962 VCLEFT_frontSeatTiltUp 3 "SWITCH_FAULT" 2 "SWITCH_ON" 1 "SWITCH_OFF" 0 "SWITCH_SNA" ;
VAL_ 962 VCLEFT_frontSeatLiftDown 3 "SWITCH_FAULT" 2 "SWITCH_ON" 1 "SWITCH_OFF" 0 "SWITCH_SNA" ;
VAL_ 962 VCLEFT_frontSeatLiftUp 3 "SWITCH_FAULT" 2 "SWITCH_ON" 1 "SWITCH_OFF" 0 "SWITCH_SNA" ;
VAL_ 962 VCLEFT_frontSeatBackrestBack 3 "SWITCH_FAULT" 2 "SWITCH_ON" 1 "SWITCH_OFF" 0 "SWITCH_SNA" ;
VAL_ 962 VCLEFT_frontSeatBackrestForward 3 "SWITCH_FAULT" 2 "SWITCH_ON" 1 "SWITCH_OFF" 0 "SWITCH_SNA" ;
VAL_ 962 VCLEFT_frontSeatLumbarDown 3 "SWITCH_FAULT" 2 "SWITCH_ON" 1 "SWITCH_OFF" 0 "SWITCH_SNA" ;
VAL_ 962 VCLEFT_frontSeatLumbarUp 3 "SWITCH_FAULT" 2 "SWITCH_ON" 1 "SWITCH_OFF" 0 "SWITCH_SNA" ;
VAL_ 962 VCLEFT_frontSeatLumbarIn 3 "SWITCH_FAULT" 2 "SWITCH_ON" 1 "SWITCH_OFF" 0 "SWITCH_SNA" ;
VAL_ 962 VCLEFT_frontSeatLumbarOut 3 "SWITCH_FAULT" 2 "SWITCH_ON" 1 "SWITCH_OFF" 0 "SWITCH_SNA" ;
VAL_ 962 VCLEFT_frontBuckleSwitch 3 "SWITCH_FAULT" 2 "SWITCH_ON" 1 "SWITCH_OFF" 0 "SWITCH_SNA" ;
VAL_ 962 VCLEFT_frontOccupancySwitch 3 "SWITCH_FAULT" 2 "SWITCH_ON" 1 "SWITCH_OFF" 0 "SWITCH_SNA" ;
VAL_ 962 VCLEFT_rearLeftBuckleSwitch 3 "SWITCH_FAULT" 2 "SWITCH_ON" 1 "SWITCH_OFF" 0 "SWITCH_SNA" ;
VAL_ 962 VCLEFT_rearCenterOccupancySwitch 3 "SWITCH_FAULT" 2 "SWITCH_ON" 1 "SWITCH_OFF" 0 "SWITCH_SNA" ;
VAL_ 962 VCLEFT_rearLeftOccupancySwitch 3 "SWITCH_FAULT" 2 "SWITCH_ON" 1 "SWITCH_OFF" 0 "SWITCH_SNA" ;
VAL_ 962 VCLEFT_rearRightOccupancySwitch 3 "SWITCH_FAULT" 2 "SWITCH_ON" 1 "SWITCH_OFF" 0 "SWITCH_SNA" ;
VAL_ 962 VCLEFT_rearCenterBuckleSwitch 3 "SWITCH_FAULT" 2 "SWITCH_ON" 1 "SWITCH_OFF" 0 "SWITCH_SNA" ;
VAL_ 962 VCLEFT_swcLeftTiltRight 3 "SWITCH_FAULT" 2 "SWITCH_ON" 1 "SWITCH_OFF" 0 "SWITCH_SNA" ;
VAL_ 962 VCLEFT_swcLeftPressed 3 "SWITCH_FAULT" 2 "SWITCH_ON" 1 "SWITCH_OFF" 0 "SWITCH_SNA" ;
VAL_ 962 VCLEFT_swcRightTiltLeft 3 "SWITCH_FAULT" 2 "SWITCH_ON" 1 "SWITCH_OFF" 0 "SWITCH_SNA" ;
VAL_ 962 VCLEFT_swcRightTiltRight 3 "SWITCH_FAULT" 2 "SWITCH_ON" 1 "SWITCH_OFF" 0 "SWITCH_SNA" ;
VAL_ 962 VCLEFT_swcRightPressed 3 "SWITCH_FAULT" 2 "SWITCH_ON" 1 "SWITCH_OFF" 0 "SWITCH_SNA" ;
VAL_ 962 VCLEFT_swcLeftTiltLeft 3 "SWITCH_FAULT" 2 "SWITCH_ON" 1 "SWITCH_OFF" 0 "SWITCH_SNA" ;
VAL_ 962 VCLEFT_swcWiperButtonState 3 "FAULT" 2 "HARD_PRESS" 1 "SOFT_PRESS" 0 "INACTIVE" ;
VAL_ 962 VCLEFT_swcTurnSignalLeftButtonSt 3 "FAULT" 2 "HARD_PRESS" 1 "SOFT_PRESS" 0 "INACTIVE" ;
VAL_ 962 VCLEFT_swcTurnSignalRightButtonS 3 "FAULT" 2 "HARD_PRESS" 1 "SOFT_PRESS" 0 "INACTIVE" ;
VAL_ 962 VCLEFT_swcHighBeamButtonState 3 "FAULT" 2 "HARD_PRESS" 1 "SOFT_PRESS" 0 "INACTIVE" ;
VAL_ 962 VCLEFT_swcVoiceControlPress 3 "SWITCH_FAULT" 2 "SWITCH_ON" 1 "SWITCH_OFF" 0 "SWITCH_SNA" ;
VAL_ 962 VCLEFT_swcCameraButtonState 3 "FAULT" 2 "HARD_PRESS" 1 "SOFT_PRESS" 0 "INACTIVE" ;
VAL_ 962 VCLEFT_swcRightPressedQF 1 "VALID" 0 "INVALID" ;
VAL_ 962 VCLEFT_frontSeatResistiveOccupan 3 "SWITCH_FAULT" 2 "SWITCH_ON" 1 "SWITCH_OFF" 0 "SWITCH_SNA" ;
VAL_ 656 VCLEFT_thermalLogging10HzIndex 5 "END" 4 "2R_HVAC_DUTY" 3 "MISC" 2 "2R_HVAC_VOLTAGE_AND_STATUS" 1 "HVAC_VARS2" 0 "HVAC_VARS" ;
VAL_ 656 VCLEFT_hvac2RLeftLateralCalibrat 1 "CALIBRATED" 0 "NOT_CALIBRATED" ;
VAL_ 656 VCLEFT_hvac2RLeftVerticalCalibra 1 "CALIBRATED" 0 "NOT_CALIBRATED" ;
VAL_ 656 VCLEFT_hvac2RRightLateralCalibra 1 "CALIBRATED" 0 "NOT_CALIBRATED" ;
VAL_ 656 VCLEFT_hvac2RRightVerticalCalibr 1 "CALIBRATED" 0 "NOT_CALIBRATED" ;
VAL_ 656 VCLEFT_hvac2RLeftLateralState 11 "HVAC_ACTUATOR_BRUSHED_STATE_RUNNING_OVERSHOOT" 10 "HVAC_ACTUATOR_BRUSHED_STATE_NEGATIVE_BACKOFF" 9 "HVAC_ACTUATOR_BRUSHED_STATE_POSITIVE_BACKOFF" 8 "HVAC_ACTUATOR_BRUSHED_STATE_CONTROL_DISABLED" 7 "HVAC_ACTUATOR_BRUSHED_STATE_FAULT" 6 "HVAC_ACTUATOR_BRUSHED_STATE_BRAKING" 5 "HVAC_ACTUATOR_BRUSHED_STATE_RUNNING" 4 "HVAC_ACTUATOR_BRUSHED_STATE_NEGATIVE_STALL" 3 "HVAC_ACTUATOR_BRUSHED_STATE_NEGATIVE_RUN" 2 "HVAC_ACTUATOR_BRUSHED_STATE_POSITIVE_STALL" 1 "HVAC_ACTUATOR_BRUSHED_STATE_POSITIVE_RUN" 0 "HVAC_ACTUATOR_BRUSHED_STATE_INIT" ;
VAL_ 656 VCLEFT_hvac2RLeftVerticalState 11 "HVAC_ACTUATOR_BRUSHED_STATE_RUNNING_OVERSHOOT" 10 "HVAC_ACTUATOR_BRUSHED_STATE_NEGATIVE_BACKOFF" 9 "HVAC_ACTUATOR_BRUSHED_STATE_POSITIVE_BACKOFF" 8 "HVAC_ACTUATOR_BRUSHED_STATE_CONTROL_DISABLED" 7 "HVAC_ACTUATOR_BRUSHED_STATE_FAULT" 6 "HVAC_ACTUATOR_BRUSHED_STATE_BRAKING" 5 "HVAC_ACTUATOR_BRUSHED_STATE_RUNNING" 4 "HVAC_ACTUATOR_BRUSHED_STATE_NEGATIVE_STALL" 3 "HVAC_ACTUATOR_BRUSHED_STATE_NEGATIVE_RUN" 2 "HVAC_ACTUATOR_BRUSHED_STATE_POSITIVE_STALL" 1 "HVAC_ACTUATOR_BRUSHED_STATE_POSITIVE_RUN" 0 "HVAC_ACTUATOR_BRUSHED_STATE_INIT" ;
VAL_ 656 VCLEFT_hvac2RRightLateralState 11 "HVAC_ACTUATOR_BRUSHED_STATE_RUNNING_OVERSHOOT" 10 "HVAC_ACTUATOR_BRUSHED_STATE_NEGATIVE_BACKOFF" 9 "HVAC_ACTUATOR_BRUSHED_STATE_POSITIVE_BACKOFF" 8 "HVAC_ACTUATOR_BRUSHED_STATE_CONTROL_DISABLED" 7 "HVAC_ACTUATOR_BRUSHED_STATE_FAULT" 6 "HVAC_ACTUATOR_BRUSHED_STATE_BRAKING" 5 "HVAC_ACTUATOR_BRUSHED_STATE_RUNNING" 4 "HVAC_ACTUATOR_BRUSHED_STATE_NEGATIVE_STALL" 3 "HVAC_ACTUATOR_BRUSHED_STATE_NEGATIVE_RUN" 2 "HVAC_ACTUATOR_BRUSHED_STATE_POSITIVE_STALL" 1 "HVAC_ACTUATOR_BRUSHED_STATE_POSITIVE_RUN" 0 "HVAC_ACTUATOR_BRUSHED_STATE_INIT" ;
VAL_ 656 VCLEFT_hvac2RRightVerticalState 11 "HVAC_ACTUATOR_BRUSHED_STATE_RUNNING_OVERSHOOT" 10 "HVAC_ACTUATOR_BRUSHED_STATE_NEGATIVE_BACKOFF" 9 "HVAC_ACTUATOR_BRUSHED_STATE_POSITIVE_BACKOFF" 8 "HVAC_ACTUATOR_BRUSHED_STATE_CONTROL_DISABLED" 7 "HVAC_ACTUATOR_BRUSHED_STATE_FAULT" 6 "HVAC_ACTUATOR_BRUSHED_STATE_BRAKING" 5 "HVAC_ACTUATOR_BRUSHED_STATE_RUNNING" 4 "HVAC_ACTUATOR_BRUSHED_STATE_NEGATIVE_STALL" 3 "HVAC_ACTUATOR_BRUSHED_STATE_NEGATIVE_RUN" 2 "HVAC_ACTUATOR_BRUSHED_STATE_POSITIVE_STALL" 1 "HVAC_ACTUATOR_BRUSHED_STATE_POSITIVE_RUN" 0 "HVAC_ACTUATOR_BRUSHED_STATE_INIT" ;
VAL_ 656 VCLEFT_vcusbLinSchedule 3 "VCUSB_LIN_SCHEDULE_COUNT" 2 "VCUSB_LIN_SCHEDULE_DIAGNOSTIC" 1 "VCUSB_LIN_SCHEDULE_COMMAND_AND_RESPONSE" 0 "VCUSB_LIN_SCHEDULE_OFF" ;
VAL_ 656 VCLEFT_hvacBlowerArbState 6 "ARBITRATOR_FAULTED" 5 "ARBITRATOR_COMPLETED" 4 "ARBITRATOR_REQUEST_CURRENT" 3 "ARBITRATOR_WAIT_BEFORE_REQUEST" 2 "ARBITRATOR_HIGH_FREQ_VOLT_INJECTION" 1 "ARBITRATOR_READY" 0 "ARBITRATOR_NOT_READY" ;
VAL_ 656 VCLEFT_hvacBlowerArbResult 2 "VC_MOTOR_ID_BOSCH" 1 "VC_MOTOR_ID_DELTA" 0 "VC_MOTOR_ID_UNKNOWN" ;
VAL_ 657 VCLEFT_thermalLogging1HzIndex 15 "MAX" 2 "END" 1 "ENDSTOP" 0 "ZEROSTOP" ;
VAL_ 706 VCLEFT_windowStatusIndex 1 "Mux1" 0 "Mux0" ;
VAL_ 706 VCLEFT_windowStateLF 10 "WINDOW_STATE_SHORT_RISE_REVERSE" 9 "WINDOW_STATE_SHORT_RISE" 8 "WINDOW_STATE_BACKDRIVE" 7 "WINDOW_STATE_MOVING_AUTO_DOWN" 6 "WINDOW_STATE_MOVING_AUTO_UP" 5 "WINDOW_STATE_SHORT_DROP_REVERSE" 4 "WINDOW_STATE_SHORT_DROP" 3 "WINDOW_STATE_BACKOFF" 2 "WINDOW_STATE_MOVING_DOWN" 1 "WINDOW_STATE_MOVING_UP" 0 "WINDOW_STATE_STOPPED" ;
VAL_ 706 VCLEFT_windowTrimClearMoveReques 3 "WINDOW_TRIM_CLEAR_MOVE_REQUEST_BACKDRIVE" 2 "WINDOW_TRIM_CLEAR_MOVE_REQUEST_RESEAL" 1 "WINDOW_TRIM_CLEAR_MOVE_REQUEST_IDLE" 0 "WINDOW_TRIM_CLEAR_MOVE_REQUEST_SNA" ;
VAL_ 706 VCLEFT_windowTrimClearActiveRequ 2 "WINDOW_TRIM_CLEAR_ACTIVE_REQUEST_ACTIVE" 1 "WINDOW_TRIM_CLEAR_ACTIVE_REQUEST_INACTIVE" 0 "WINDOW_TRIM_CLEAR_ACTIVE_REQUEST_SNA" ;
VAL_ 706 VCLEFT_windowPositionLF 1 "SNA" ;
VAL_ 706 VCLEFT_windowStateLR 10 "WINDOW_STATE_SHORT_RISE_REVERSE" 9 "WINDOW_STATE_SHORT_RISE" 8 "WINDOW_STATE_BACKDRIVE" 7 "WINDOW_STATE_MOVING_AUTO_DOWN" 6 "WINDOW_STATE_MOVING_AUTO_UP" 5 "WINDOW_STATE_SHORT_DROP_REVERSE" 4 "WINDOW_STATE_SHORT_DROP" 3 "WINDOW_STATE_BACKOFF" 2 "WINDOW_STATE_MOVING_DOWN" 1 "WINDOW_STATE_MOVING_UP" 0 "WINDOW_STATE_STOPPED" ;
VAL_ 706 VCLEFT_windowThermalModeLF 3 "WINDOW_THERMAL_MODE_CRITICAL" 2 "WINDOW_THERMAL_MODE_ALERT" 1 "WINDOW_THERMAL_MODE_NORMAL" 0 "WINDOW_THERMAL_MODE_SNA" ;
VAL_ 706 VCLEFT_windowStopReasonLF 6 "WINDOW_STOP_REASON_STATE_TIMEOUT" 5 "WINDOW_STOP_REASON_FULL_OPEN_SOFT_STOP" 4 "WINDOW_STOP_REASON_STOP_REQUEST" 3 "WINDOW_STOP_REASON_TARGET_REACHED" 2 "WINDOW_STOP_REASON_NEW_REQUEST" 1 "WINDOW_STOP_REASON_DOOR_OPEN_TRIM_PROTECT" 0 "WINDOW_STOP_REASON_NONE" ;
VAL_ 706 VCLEFT_windowStopReqReasonLF 8 "WINDOW_STOP_REQUEST_REASON_EXTERNAL_REQUEST" 7 "WINDOW_STOP_REQUEST_REASON_FULL_OPEN_SOFT_STOP" 6 "WINDOW_STOP_REQUEST_REASON_STATE_TIMEOUT" 5 "WINDOW_STOP_REQUEST_REASON_STALL" 4 "WINDOW_STOP_REQUEST_REASON_THERMAL" 3 "WINDOW_STOP_REQUEST_REASON_REAR_LOCKOUT" 2 "WINDOW_STOP_REQUEST_REASON_SWITCH_RELEASED" 1 "WINDOW_STOP_REQUEST_REASON_SWITCH_CANCEL_AUTO_MOVEMENT" 0 "WINDOW_STOP_REQUEST_REASON_NONE" ;
VAL_ 706 VCLEFT_windowThermalModeLR 3 "WINDOW_THERMAL_MODE_CRITICAL" 2 "WINDOW_THERMAL_MODE_ALERT" 1 "WINDOW_THERMAL_MODE_NORMAL" 0 "WINDOW_THERMAL_MODE_SNA" ;
VAL_ 706 VCLEFT_windowStopReasonLR 6 "WINDOW_STOP_REASON_STATE_TIMEOUT" 5 "WINDOW_STOP_REASON_FULL_OPEN_SOFT_STOP" 4 "WINDOW_STOP_REASON_STOP_REQUEST" 3 "WINDOW_STOP_REASON_TARGET_REACHED" 2 "WINDOW_STOP_REASON_NEW_REQUEST" 1 "WINDOW_STOP_REASON_DOOR_OPEN_TRIM_PROTECT" 0 "WINDOW_STOP_REASON_NONE" ;
VAL_ 706 VCLEFT_windowStopReqReasonLR 8 "WINDOW_STOP_REQUEST_REASON_EXTERNAL_REQUEST" 7 "WINDOW_STOP_REQUEST_REASON_FULL_OPEN_SOFT_STOP" 6 "WINDOW_STOP_REQUEST_REASON_STATE_TIMEOUT" 5 "WINDOW_STOP_REQUEST_REASON_STALL" 4 "WINDOW_STOP_REQUEST_REASON_THERMAL" 3 "WINDOW_STOP_REQUEST_REASON_REAR_LOCKOUT" 2 "WINDOW_STOP_REQUEST_REASON_SWITCH_RELEASED" 1 "WINDOW_STOP_REQUEST_REASON_SWITCH_CANCEL_AUTO_MOVEMENT" 0 "WINDOW_STOP_REQUEST_REASON_NONE" ;
VAL_ 706 VCLEFT_windowControlStateLF 2 "WINDOW_CONTROL_STATE_GOING_TO_POSITION" 1 "WINDOW_CONTROL_STATE_CLOSING" 0 "WINDOW_CONTROL_STATE_IDLE" ;
VAL_ 706 VCLEFT_windowCtrlUnavailableLF 7 "WINDOW_CONTROL_UNAVAILABLE_REASON_WINDOW_MOVING" 6 "WINDOW_CONTROL_UNAVAILABLE_REASON_VEHICLE_IN_DRIVE" 5 "WINDOW_CONTROL_UNAVAILABLE_REASON_UNCALIBRATED" 4 "WINDOW_CONTROL_UNAVAILABLE_REASON_THERMAL_LIMIT" 3 "WINDOW_CONTROL_UNAVAILABLE_REASON_PINCH" 2 "WINDOW_CONTROL_UNAVAILABLE_REASON_SWITCH_PRESSED" 1 "WINDOW_CONTROL_UNAVAILABLE_REASON_UNEXPECTED" 0 "WINDOW_CONTROL_UNAVAILABLE_REASON_NONE" ;
VAL_ 706 VCLEFT_windowControlStateLR 2 "WINDOW_CONTROL_STATE_GOING_TO_POSITION" 1 "WINDOW_CONTROL_STATE_CLOSING" 0 "WINDOW_CONTROL_STATE_IDLE" ;
VAL_ 706 VCLEFT_windowCtrlUnavailableLR 7 "WINDOW_CONTROL_UNAVAILABLE_REASON_WINDOW_MOVING" 6 "WINDOW_CONTROL_UNAVAILABLE_REASON_VEHICLE_IN_DRIVE" 5 "WINDOW_CONTROL_UNAVAILABLE_REASON_UNCALIBRATED" 4 "WINDOW_CONTROL_UNAVAILABLE_REASON_THERMAL_LIMIT" 3 "WINDOW_CONTROL_UNAVAILABLE_REASON_PINCH" 2 "WINDOW_CONTROL_UNAVAILABLE_REASON_SWITCH_PRESSED" 1 "WINDOW_CONTROL_UNAVAILABLE_REASON_UNEXPECTED" 0 "WINDOW_CONTROL_UNAVAILABLE_REASON_NONE" ;
VAL_ 706 VCLEFT_windowPositionStateLF 7 "WINDOW_POSITION_CLOSED_TRIM_CLEAR" 6 "WINDOW_POSITION_FULL_OPEN" 5 "WINDOW_POSITION_PARTIAL_OPEN" 4 "WINDOW_POSITION_DAS_LIMITED" 3 "WINDOW_POSITION_VENT" 2 "WINDOW_POSITION_CRACKED" 1 "WINDOW_POSITION_CLOSED" 0 "WINDOW_POSITION_UNKNOWN" ;
VAL_ 706 VCLEFT_windowPositionStateLR 7 "WINDOW_POSITION_CLOSED_TRIM_CLEAR" 6 "WINDOW_POSITION_FULL_OPEN" 5 "WINDOW_POSITION_PARTIAL_OPEN" 4 "WINDOW_POSITION_DAS_LIMITED" 3 "WINDOW_POSITION_VENT" 2 "WINDOW_POSITION_CRACKED" 1 "WINDOW_POSITION_CLOSED" 0 "WINDOW_POSITION_UNKNOWN" ;
VAL_ 706 VCLEFT_windowVehGearStateLF 2 "WINDOW_VEHICLE_GEAR_STATE_IN_GEAR" 1 "WINDOW_VEHICLE_GEAR_STATE_PARK" 0 "WINDOW_VEHICLE_GEAR_STATE_UNKNOWN_SNA" ;
VAL_ 706 VCLEFT_windowVehGearStateLR 2 "WINDOW_VEHICLE_GEAR_STATE_IN_GEAR" 1 "WINDOW_VEHICLE_GEAR_STATE_PARK" 0 "WINDOW_VEHICLE_GEAR_STATE_UNKNOWN_SNA" ;
VAL_ 706 VCLEFT_windowSpeedTableStatusLF 2 "WINDOW_SPEED_TABLE_STATUS_FULLY_BUILT" 1 "WINDOW_SPEED_TABLE_STATUS_SENSITIVE_BUILT" 0 "WINDOW_SPEED_TABLE_STATUS_EMPTY_SNA" ;
VAL_ 706 VCLEFT_windowSpeedTableStatusLR 2 "WINDOW_SPEED_TABLE_STATUS_FULLY_BUILT" 1 "WINDOW_SPEED_TABLE_STATUS_SENSITIVE_BUILT" 0 "WINDOW_SPEED_TABLE_STATUS_EMPTY_SNA" ;
VAL_ 549 VCRIGHT_ptcLVState 3 "LV_FAULT" 2 "LV_GOING_DOWN" 1 "LV_ON" 0 "LV_OFF" ;
VAL_ 549 VCRIGHT_ocsLVState 3 "LV_FAULT" 2 "LV_GOING_DOWN" 1 "LV_ON" 0 "LV_OFF" ;
VAL_ 549 VCRIGHT_premAudioLVState 3 "LV_FAULT" 2 "LV_GOING_DOWN" 1 "LV_ON" 0 "LV_OFF" ;
VAL_ 549 VCRIGHT_rearOilPumpLVState 3 "LV_FAULT" 2 "LV_GOING_DOWN" 1 "LV_ON" 0 "LV_OFF" ;
VAL_ 549 VCRIGHT_tunerLVState 3 "LV_FAULT" 2 "LV_GOING_DOWN" 1 "LV_ON" 0 "LV_OFF" ;
VAL_ 549 VCRIGHT_hvcLVState 3 "LV_FAULT" 2 "LV_GOING_DOWN" 1 "LV_ON" 0 "LV_OFF" ;
VAL_ 549 VCRIGHT_rcmLVState 3 "LV_FAULT" 2 "LV_GOING_DOWN" 1 "LV_ON" 0 "LV_OFF" ;
VAL_ 549 VCRIGHT_lumbarLVState 3 "LV_FAULT" 2 "LV_GOING_DOWN" 1 "LV_ON" 0 "LV_OFF" ;
VAL_ 549 VCRIGHT_eFuseLockoutStatus 2 "EFUSE_LOCKOUT_STATUS_ACTIVE" 1 "EFUSE_LOCKOUT_STATUS_PENDING" 0 "EFUSE_LOCKOUT_STATUS_IDLE" ;
VAL_ 549 VCRIGHT_vehiclePowerStateDBG 3 "VEHICLE_POWER_STATE_DRIVE" 2 "VEHICLE_POWER_STATE_ACCESSORY" 1 "VEHICLE_POWER_STATE_CONDITIONING" 0 "VEHICLE_POWER_STATE_OFF" ;
VAL_ 549 VCRIGHT_parkLVState 3 "LV_FAULT" 2 "LV_GOING_DOWN" 1 "LV_ON" 0 "LV_OFF" ;
VAL_ 549 VCRIGHT_icrLVState 3 "LV_FAULT" 2 "LV_GOING_DOWN" 1 "LV_ON" 0 "LV_OFF" ;
VAL_ 549 VCRIGHT_interiorCameraLedLVState 3 "LV_FAULT" 2 "LV_GOING_DOWN" 1 "LV_ON" 0 "LV_OFF" ;
VAL_ 549 VCRIGHT_diLVState 3 "LV_FAULT" 2 "LV_GOING_DOWN" 1 "LV_ON" 0 "LV_OFF" ;
VAL_ 643 VCRIGHT_PTCRequestMode 4 "SEQ_ROD_CIO" 3 "SEQ_ROD_COI" 2 "DIRECT" 1 "DUTY" 0 "POWER" ;
VAL_ 1795 VCRIGHT_debugThermal10HzIndex 10 "END" 9 "HVAC_ACTUATOR_TUNNING" 8 "HVAC_PTC_COI_DEV4" 7 "HVAC_PTC_COI_DEV3" 6 "HVAC_PTC_COI_DEV2" 5 "HVAC_PTC_COI_DEV1" 4 "actuatorStatus" 3 "cabinModel" 2 "airflow" 1 "temps" 0 "heaterAndEvapWatts" ;
VAL_ 1795 VCRIGHT_setTempAdjustmentLeft 127 "SNA" ;
VAL_ 1795 VCRIGHT_setTempAdjustmentRight 127 "SNA" ;
VAL_ 1795 VCRIGHT_PTCcenterPowerLeft 63 "SNA" ;
VAL_ 1795 VCRIGHT_PTCouterPowerLeft 63 "SNA" ;
VAL_ 1795 VCRIGHT_PTCinnerPowerLeft 63 "SNA" ;
VAL_ 1795 VCRIGHT_PTCcenterPowerRight 63 "SNA" ;
VAL_ 1795 VCRIGHT_PTCouterPowerRight 63 "SNA" ;
VAL_ 1795 VCRIGHT_PTCinnerPowerRight 63 "SNA" ;
VAL_ 1795 VCRIGHT_PTCcenterStoneTempLeft 255 "SNA" ;
VAL_ 1795 VCRIGHT_PTCcenterStoneTempRight 255 "SNA" ;
VAL_ 1795 VCRIGHT_PTCinnerStoneTempLeft 255 "SNA" ;
VAL_ 1795 VCRIGHT_PTCinnerStoneTempRight 255 "SNA" ;
VAL_ 1795 VCRIGHT_PTCouterStoneTempLeft 255 "SNA" ;
VAL_ 1795 VCRIGHT_PTCouterRodTempLeft 255 "SNA" ;
VAL_ 1795 VCRIGHT_PTCouterAirTempLeft 255 "SNA" ;
VAL_ 1795 VCRIGHT_PTCcenterRodTempLeft 255 "SNA" ;
VAL_ 1795 VCRIGHT_PTCinnerRodTempLeft 255 "SNA" ;
VAL_ 1795 VCRIGHT_PTCcenterAirTempLeft 255 "SNA" ;
VAL_ 1795 VCRIGHT_PTCinnerAirTempLeft 255 "SNA" ;
VAL_ 1795 VCRIGHT_PTCouterStoneTempRight 255 "SNA" ;
VAL_ 1795 VCRIGHT_PTCouterRodTempRight 255 "SNA" ;
VAL_ 1795 VCRIGHT_PTCouterAirTempRight 255 "SNA" ;
VAL_ 1795 VCRIGHT_PTCcenterRodTempRight 255 "SNA" ;
VAL_ 1795 VCRIGHT_PTCinnerRodTempRight 255 "SNA" ;
VAL_ 1795 VCRIGHT_PTCcenterAirTempRight 255 "SNA" ;
VAL_ 1795 VCRIGHT_PTCinnerAirTempRight 255 "SNA" ;
VAL_ 291 VCRIGHT_doorStatus2Index 1 "MUX1" 0 "MUX0" ;
VAL_ 291 VCRIGHT_BPillarCameraHeaterState 4 "HEATER_STATE_FAULT" 3 "HEATER_STATE_OFF_UNAVAILABLE" 2 "HEATER_STATE_OFF" 1 "HEATER_STATE_ON" 0 "HEATER_STATE_SNA" ;
VAL_ 291 VCRIGHT_BPillarCameraHeaterCurre 63 "SNA" ;
VAL_ 915 VCRIGHT_epbmDebugIndex 1 "TRANSITIONS" 0 "STATES" ;
VAL_ 915 VCRIGHT_epbmCaliperState 6 "EPB_SAVED_CALIPERSTATE_WINCHMODE" 5 "EPB_SAVED_CALIPERSTATE_SERVICE" 4 "EPB_SAVED_CALIPERSTATE_OPEN" 3 "EPB_SAVED_CALIPERSTATE_PARK" 2 "EPB_SAVED_CALIPERSTATE_REAPPLY" 1 "EPB_SAVED_CALIPERSTATE_UNKNOWN" 0 "EPB_SAVED_CALIPERSTATE_UNSAVED" ;
VAL_ 915 VCRIGHT_summonFaultReason 30 "EPB_SUMMONFAULT_MONITOR_TYPE_UNKNOWN" 29 "EPB_SUMMONFAULT_AP_MONITOR" 28 "EPB_SUMMONFAULT_REMOTE_DID_NOT_START" 27 "EPB_SUMMONFAULT_INVALID_REMOTE_STATE" 26 "EPB_SUMMONFAULT_START_IN_UNAVAILABLE" 25 "EPB_SUMMONFAULT_REMOTE_UNIT_FAULTED" 24 "EPB_SUMMONFAULT_LOCAL_UNIT_FAULTED" 23 "EPB_SUMMONFAULT_REMOTE_SUMMON_FAULTED" 22 "EPB_SUMMONFAULT_EPBREMOTE_MIA" 21 "EPB_SUMMONFAULT_PASSIVE_REQUEST" 20 "EPB_SUMMONFAULT_DI_STATE_INVALID" 19 "EPB_SUMMONFAULT_EPB_FAULT" 18 "EPB_SUMMONFAULT_MISMATCH" 17 "EPB_SUMMONFAULT_OOC" 16 "EPB_SUMMONFAULT_PM_REQUEST" 15 "EPB_SUMMONFAULT_PM_MIA" 14 "EPB_SUMMONFAULT_PARK_MIA" 13 "EPB_SUMMONFAULT_EXTERNAL" 12 "EPB_SUMMONFAULT_SPEED" 11 "EPB_SUMMONFAULT_EPBM_REQUEST" 10 "EPB_SUMMONFAULT_EAC_NOT_ALLOWED" 9 "EPB_SUMMONFAULT_VEH_CAN_FAULT" 8 "EPB_SUMMONFAULT_ESP_FAULT" 7 "EPB_SUMMONFAULT_DAS_FAULT" 6 "EPB_SUMMONFAULT_DI_APC_FAULT" 5 "EPB_SUMMONFAULT_DI_FAULT" 4 "EPB_SUMMONFAULT_EPBM_MIA" 3 "EPB_SUMMONFAULT_ESP_MIA" 2 "EPB_SUMMONFAULT_DAS_MIA" 1 "EPB_SUMMONFAULT_DI_MIA" 0 "EPB_SUMMONFAULT_NONE" ;
VAL_ 915 VCRIGHT_epbSummonState 6 "EPB_SUMMON_UNAVAILABLE" 5 "EPB_SUMMON_FAULT" 4 "EPB_SUMMON_COMPLETE" 3 "EPB_SUMMON_ACTIVE" 2 "EPB_SUMMON_ARMED" 1 "EPB_SUMMON_IDLE" 0 "EPB_SUMMON_INIT" ;
VAL_ 915 VCRIGHT_epbmSummonState 6 "EPB_SUMMON_UNAVAILABLE" 5 "EPB_SUMMON_FAULT" 4 "EPB_SUMMON_COMPLETE" 3 "EPB_SUMMON_ACTIVE" 2 "EPB_SUMMON_ARMED" 1 "EPB_SUMMON_IDLE" 0 "EPB_SUMMON_INIT" ;
VAL_ 915 VCRIGHT_epbUnitStatus 23 "EPB_STATUS_COUNT" 22 "EPB_STATUS_AUTONOMY_OPEN" 21 "EPB_STATUS_FREE_ROLL_MODE" 20 "EPB_STATUS_DYNAMIC_PARKING" 19 "EPB_STATUS_EXTERNAL_PARKING" 18 "EPB_STATUS_RELEASING_FOR_EXTERNAL_PARK" 17 "EPB_STATUS_EXTERNAL_DYNAMIC" 16 "EPB_STATUS_SUMMON_PARKING" 15 "EPB_STATUS_SUMMON_RELEASING" 14 "EPB_STATUS_SUMMON" 13 "EPB_STATUS_WINCHMODE_PENDING" 12 "EPB_STATUS_PARK_PENDING" 11 "EPB_STATUS_SERVICE_RELEASING" 10 "EPB_STATUS_RELEASING" 9 "EPB_STATUS_DYNAMIC_APPLYING" 8 "EPB_STATUS_PARKING" 7 "EPB_STATUS_WINCHMODE_RELEASING" 6 "EPB_STATUS_WINCHMODE" 5 "EPB_STATUS_SERVICE" 4 "EPB_STATUS_START" 3 "EPB_STATUS_PARK" 2 "EPB_STATUS_DYNAMIC" 1 "EPB_STATUS_OPEN" 0 "EPB_STATUS_UNKNOWN" ;
VAL_ 915 VCRIGHT_epbmFaultStatus 3 "EPB_STATUS_FAULT_IDLE" 2 "EPB_STATUS_FAULT" 1 "EPB_STATUS_RETRY" 0 "EPB_STATUS_NOMINAL" ;
VAL_ 915 VCRIGHT_epbFaultStatus 3 "EPB_STATUS_FAULT_IDLE" 2 "EPB_STATUS_FAULT" 1 "EPB_STATUS_RETRY" 0 "EPB_STATUS_NOMINAL" ;
VAL_ 915 VCRIGHT_epbmSystemStatus 8 "EPB_VEHICLE_STATUS_MISMATCH" 7 "EPB_VEHICLE_STATUS_FAULT_SECURE" 6 "EPB_VEHICLE_STATUS_FAULT" 5 "EPB_VEHICLE_STATUS_RELEASING" 4 "EPB_VEHICLE_STATUS_PARKING" 3 "EPB_VEHICLE_STATUS_DYNAMIC" 2 "EPB_VEHICLE_STATUS_PARKED" 1 "EPB_VEHICLE_STATUS_RELEASED" 0 "EPB_VEHICLE_STATUS_UNKNOWN" ;
VAL_ 915 VCRIGHT_epbmAutonomyBehavior 2 "DRIVERLESS_NO_TAKEOVER" 1 "DRIVERLESS_TAKEOVER" 0 "DRIVER" ;
VAL_ 524 VCRIGHT_tempEvaporator 2047 "SNA" ;
VAL_ 524 VCRIGHT_tempEvaporatorTarget 255 "SNA" ;
VAL_ 524 VCRIGHT_tempAmbientRaw 0 "SNA" ;
VAL_ 524 VCRIGHT_hvacPerfTestState 2 "BLOWING" 1 "WAITING" 0 "STOPPED" ;
